VERSION "GM Global B Super Cruise 1 CAN8"
NS_ :

    CM_ BO_ 648 "Full freshness counter companion for 0x0C1. The next observed protected frame carries (counter + 1) modulo 32. Counter pairing verified; authentication key and data ID remain unresolved.";
CM_ BO_ 650 "Full freshness counter companion for 0x0C6. The next observed protected frame carries (counter + 1) modulo 32. Counter pairing verified; authentication key and data ID remain unresolved.";
CM_ BO_ 654 "Full freshness counter companion for 0x0D1. The next observed protected frame carries (counter + 1) modulo 32. Counter pairing verified; authentication key and data ID remain unresolved.";
CM_ BO_ 656 "Full freshness counter companion for 0x0D4. The next observed protected frame carries (counter + 1) modulo 32. Counter pairing verified; authentication key and data ID remain unresolved.";
CM_ BO_ 655 "Full freshness counter companion for 0x0FE. The next observed protected frame carries (counter + 1) modulo 32. Counter pairing verified; authentication key and data ID remain unresolved.";
CM_ BO_ 1326 "Full freshness counter companion for 0x252. The next observed protected frame carries (counter + 1) modulo 32. Counter pairing verified; authentication key and data ID remain unresolved.";

BA_DEF_
    BA_
    BA_DEF_DEF_
BS_:
BU_: ACP3_MCU CGM FCM PARK_ASSIST LRR LFR RFR LCRR LRR_SIDE RRR_SIDE Vector__XXX

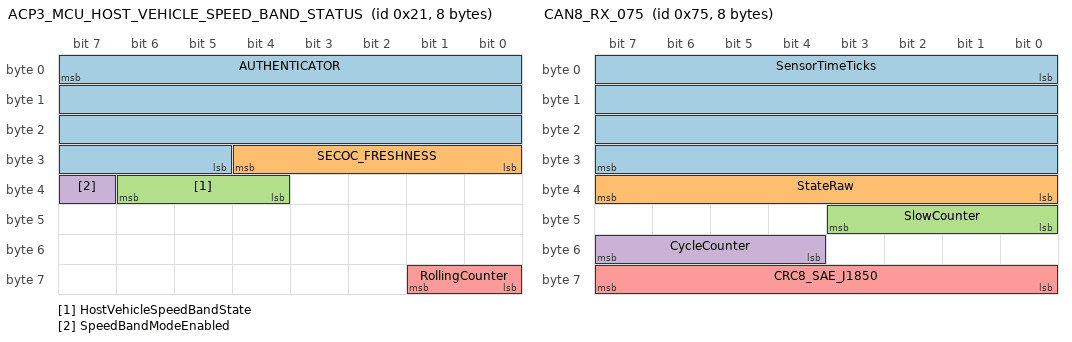
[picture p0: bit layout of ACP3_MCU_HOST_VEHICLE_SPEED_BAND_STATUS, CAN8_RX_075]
BO_ 33 ACP3_MCU_HOST_VEHICLE_SPEED_BAND_STATUS: 8 ACP3_MCU
 SG_ AUTHENTICATOR : 7|27@0+ (1,0) [0|134217727] "" Vector__XXX
 SG_ SECOC_FRESHNESS : 28|5@0+ (1,0) [0|31] "" Vector__XXX
 SG_ HostVehicleSpeedBandState : 36|3@1+ (1,0) [0|7] "" Vector__XXX
 SG_ SpeedBandModeEnabled : 39|1@1+ (1,0) [0|1] "" Vector__XXX
 SG_ RollingCounter : 56|2@1+ (1,0) [0|3] "" Vector__XXX

BO_ 117 CAN8_RX_075: 8 Vector__XXX
 SG_ SensorTimeTicks : 0|32@1+ (1,0) [0|4294967295] "tick" ACP3_MCU
 SG_ StateRaw : 32|8@1+ (1,0) [0|255] "" ACP3_MCU
 SG_ SlowCounter : 40|4@1+ (1,0) [0|15] "" ACP3_MCU
 SG_ CycleCounter : 52|4@1+ (1,0) [0|15] "" ACP3_MCU
 SG_ CRC8_SAE_J1850 : 56|8@1+ (1,0) [0|255] "" ACP3_MCU

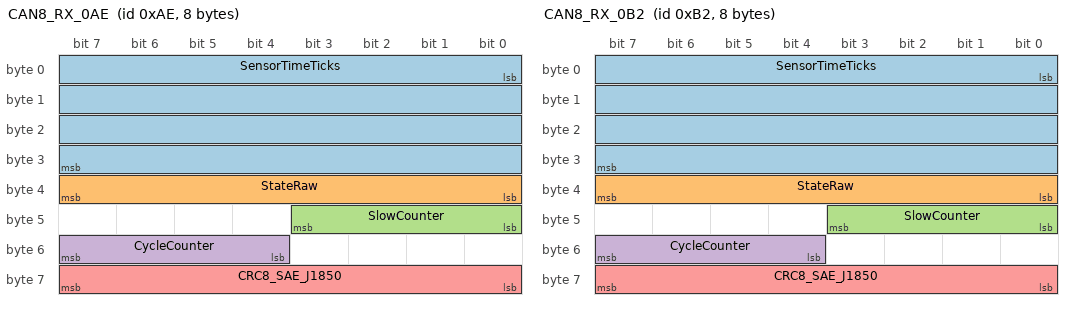
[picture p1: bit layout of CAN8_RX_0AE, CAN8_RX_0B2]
BO_ 174 CAN8_RX_0AE: 8 Vector__XXX
 SG_ SensorTimeTicks : 0|32@1+ (1,0) [0|4294967295] "tick" ACP3_MCU
 SG_ StateRaw : 32|8@1+ (1,0) [0|255] "" ACP3_MCU
 SG_ SlowCounter : 40|4@1+ (1,0) [0|15] "" ACP3_MCU
 SG_ CycleCounter : 52|4@1+ (1,0) [0|15] "" ACP3_MCU
 SG_ CRC8_SAE_J1850 : 56|8@1+ (1,0) [0|255] "" ACP3_MCU

BO_ 178 CAN8_RX_0B2: 8 Vector__XXX
 SG_ SensorTimeTicks : 0|32@1+ (1,0) [0|4294967295] "tick" ACP3_MCU
 SG_ StateRaw : 32|8@1+ (1,0) [0|255] "" ACP3_MCU
 SG_ SlowCounter : 40|4@1+ (1,0) [0|15] "" ACP3_MCU
 SG_ CycleCounter : 52|4@1+ (1,0) [0|15] "" ACP3_MCU
 SG_ CRC8_SAE_J1850 : 56|8@1+ (1,0) [0|255] "" ACP3_MCU

BO_ 180 PARK_ASSIST_ULTRASONIC_BANK_A_0B4: 48 PARK_ASSIST
 SG_ AUTHENTICATOR : 7|32@0+ (1,0) [0|4294967295] "" ACP3_MCU
 SG_ SECOC_FRESHNESS : 39|5@0+ (1,0) [0|31] "" ACP3_MCU
 SG_ SECOC_AUX : 34|3@0+ (1,0) [0|7] "" ACP3_MCU
 SG_ ApplicationHeaderRaw : 40|8@1+ (1,0) [0|255] "" ACP3_MCU
 SG_ UltrasonicRecord1Raw : 48|48@1+ (1,0) [0|281474976710655] "" ACP3_MCU
 SG_ UltrasonicRecord2Raw : 96|48@1+ (1,0) [0|281474976710655] "" ACP3_MCU
 SG_ UltrasonicRecord3Raw : 144|48@1+ (1,0) [0|281474976710655] "" ACP3_MCU
 SG_ UltrasonicRecord4Raw : 192|48@1+ (1,0) [0|281474976710655] "" ACP3_MCU
 SG_ UltrasonicRecord5Raw : 240|48@1+ (1,0) [0|281474976710655] "" ACP3_MCU
 SG_ UltrasonicRecord6Raw : 288|48@1+ (1,0) [0|281474976710655] "" ACP3_MCU
 SG_ ApplicationTailRaw : 336|16@1+ (1,0) [0|65535] "" ACP3_MCU
 SG_ ReservedTail : 352|32@1+ (1,0) [0|4294967295] "" ACP3_MCU

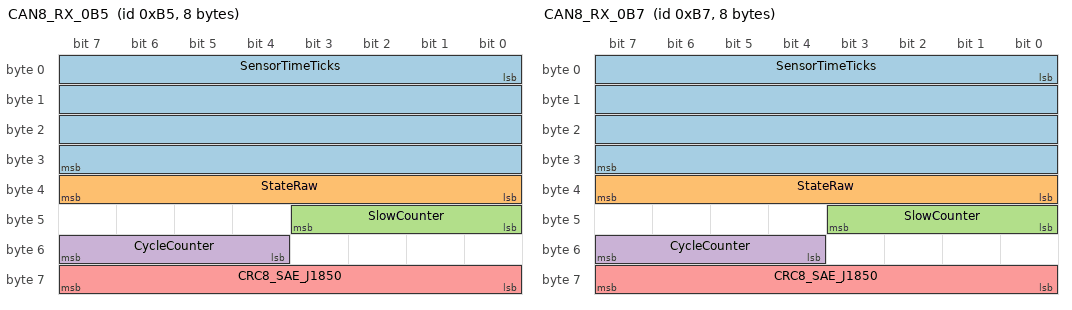
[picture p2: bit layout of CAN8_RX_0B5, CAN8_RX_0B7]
BO_ 181 CAN8_RX_0B5: 8 Vector__XXX
 SG_ SensorTimeTicks : 0|32@1+ (1,0) [0|4294967295] "tick" ACP3_MCU
 SG_ StateRaw : 32|8@1+ (1,0) [0|255] "" ACP3_MCU
 SG_ SlowCounter : 40|4@1+ (1,0) [0|15] "" ACP3_MCU
 SG_ CycleCounter : 52|4@1+ (1,0) [0|15] "" ACP3_MCU
 SG_ CRC8_SAE_J1850 : 56|8@1+ (1,0) [0|255] "" ACP3_MCU

BO_ 183 CAN8_RX_0B7: 8 Vector__XXX
 SG_ SensorTimeTicks : 0|32@1+ (1,0) [0|4294967295] "tick" ACP3_MCU
 SG_ StateRaw : 32|8@1+ (1,0) [0|255] "" ACP3_MCU
 SG_ SlowCounter : 40|4@1+ (1,0) [0|15] "" ACP3_MCU
 SG_ CycleCounter : 52|4@1+ (1,0) [0|15] "" ACP3_MCU
 SG_ CRC8_SAE_J1850 : 56|8@1+ (1,0) [0|255] "" ACP3_MCU

BO_ 190 RRR_SIDE_OBJECT_PAGE0_0BE: 64 RRR_SIDE
 SG_ CycleCounter : 6|2@1+ (1,0) [0|3] "" ACP3_MCU
 SG_ Object0LongitudinalEstimate : 318|11@0- (0.125,0) [-128|127.875] "m" ACP3_MCU
 SG_ Object0LateralEstimate : 323|10@0- (0.125,0) [-64|63.875] "m" ACP3_MCU
 SG_ Object1LongitudinalEstimate : 329|11@0- (0.125,0) [-128|127.875] "m" ACP3_MCU
 SG_ Object1LateralEstimate : 350|10@0- (0.125,0) [-64|63.875] "m" ACP3_MCU
 SG_ Object2LongitudinalEstimate : 356|11@0- (0.125,0) [-128|127.875] "m" ACP3_MCU
 SG_ Object2LateralEstimate : 361|10@0- (0.125,0) [-64|63.875] "m" ACP3_MCU
 SG_ Object3LongitudinalEstimate : 383|11@0- (0.125,0) [-128|127.875] "m" ACP3_MCU
 SG_ Object3LateralEstimate : 388|10@0- (0.125,0) [-64|63.875] "m" ACP3_MCU
 SG_ Object4LongitudinalEstimate : 394|11@0- (0.125,0) [-128|127.875] "m" ACP3_MCU
 SG_ Object4LateralEstimate : 415|10@0- (0.125,0) [-64|63.875] "m" ACP3_MCU
 SG_ Object5LongitudinalEstimate : 421|11@0- (0.125,0) [-128|127.875] "m" ACP3_MCU
 SG_ Object5LateralEstimate : 426|10@0- (0.125,0) [-64|63.875] "m" ACP3_MCU
 SG_ Object6LongitudinalEstimate : 432|11@0- (0.125,0) [-128|127.875] "m" ACP3_MCU
 SG_ Object6LateralEstimate : 453|10@0- (0.125,0) [-64|63.875] "m" ACP3_MCU
 SG_ Object7LongitudinalEstimate : 459|11@0- (0.125,0) [-128|127.875] "m" ACP3_MCU
 SG_ Object7LateralEstimate : 464|10@0- (0.125,0) [-64|63.875] "m" ACP3_MCU
 SG_ Object8LongitudinalEstimate : 486|11@0- (0.125,0) [-128|127.875] "m" ACP3_MCU
 SG_ Object8LateralEstimate : 491|10@0- (0.125,0) [-64|63.875] "m" ACP3_MCU

BO_ 191 RRR_SIDE_OBJECT_PAGE1_0BF: 64 RRR_SIDE
 SG_ CycleCounter : 6|2@1+ (1,0) [0|3] "" ACP3_MCU

BO_ 193 RRR_SIDE_SECURITY_AUX0_0C1: 48 RRR_SIDE
 SG_ SECOC_FRESHNESS : 39|5@0+ (1,0) [0|31] "" ACP3_MCU
 SG_ ApplicationCounter : 376|2@1+ (1,0) [0|3] "" ACP3_MCU
 SG_ Object0LongitudinalRaw : 278|11@0- (1,0) [-1024|1023] "" ACP3_MCU
 SG_ Object0TrackId : 240|6@0+ (1,0) [0|63] "" ACP3_MCU
 SG_ Object0RelativeLongitudinalVelocityRaw : 307|11@0- (1,0) [-1024|1023] "" ACP3_MCU
 SG_ Object0RelativeLateralVelocityCandidateRaw : 248|9@0- (1,0) [-256|255] "" ACP3_MCU

BO_ 197 LRR_SIDE_OBJECT_PAGE0_0C5: 64 LRR_SIDE
 SG_ CycleCounter : 6|2@1+ (1,0) [0|3] "" ACP3_MCU
 SG_ Object1TrackId : 102|6@0+ (1,0) [0|63] "" ACP3_MCU
 SG_ Object2TrackId : 226|6@0+ (1,0) [0|63] "" ACP3_MCU
 SG_ Object3TrackId : 374|6@0+ (1,0) [0|63] "" ACP3_MCU
 SG_ Object1RelativeLongitudinalVelocityRaw : 145|11@0- (1,0) [-1024|1023] "" ACP3_MCU
 SG_ Object1RelativeLateralVelocityCandidateRaw : 110|9@0- (1,0) [-256|255] "" ACP3_MCU
 SG_ Object2RelativeLongitudinalVelocityRaw : 293|11@0- (1,0) [-1024|1023] "" ACP3_MCU
 SG_ Object2RelativeLateralVelocityCandidateRaw : 234|9@0- (1,0) [-256|255] "" ACP3_MCU
 SG_ Object3RelativeLongitudinalVelocityRaw : 425|11@0- (1,0) [-1024|1023] "" ACP3_MCU
 SG_ Object3RelativeLateralVelocityCandidateRaw : 382|9@0- (1,0) [-256|255] "" ACP3_MCU

BO_ 198 LRR_SIDE_SECURITY_AUX0_0C6: 48 LRR_SIDE
 SG_ SECOC_FRESHNESS : 39|5@0+ (1,0) [0|31] "" ACP3_MCU
 SG_ ApplicationCounter : 376|2@1+ (1,0) [0|3] "" ACP3_MCU
 SG_ Object0LongitudinalRaw : 278|11@0- (1,0) [-1024|1023] "" ACP3_MCU
 SG_ Object0TrackId : 240|6@0+ (1,0) [0|63] "" ACP3_MCU
 SG_ Object0RelativeLongitudinalVelocityRaw : 307|11@0- (1,0) [-1024|1023] "" ACP3_MCU
 SG_ Object0RelativeLateralVelocityCandidateRaw : 248|9@0- (1,0) [-256|255] "" ACP3_MCU

BO_ 199 LCRR_OBJECT_PAGE0_0C7: 64 LCRR
 SG_ CycleCounter : 6|2@1+ (1,0) [0|3] "" ACP3_MCU
 SG_ Object0LongitudinalEstimate : 318|11@0- (0.125,0) [-128|127.875] "m" ACP3_MCU
 SG_ Object0LateralEstimate : 323|10@0- (0.125,0) [-64|63.875] "m" ACP3_MCU
 SG_ Object1LongitudinalEstimate : 329|11@0- (0.125,0) [-128|127.875] "m" ACP3_MCU
 SG_ Object1LateralEstimate : 350|10@0- (0.125,0) [-64|63.875] "m" ACP3_MCU
 SG_ Object2LongitudinalEstimate : 356|11@0- (0.125,0) [-128|127.875] "m" ACP3_MCU
 SG_ Object2LateralEstimate : 361|10@0- (0.125,0) [-64|63.875] "m" ACP3_MCU
 SG_ Object3LongitudinalEstimate : 383|11@0- (0.125,0) [-128|127.875] "m" ACP3_MCU
 SG_ Object3LateralEstimate : 388|10@0- (0.125,0) [-64|63.875] "m" ACP3_MCU
 SG_ Object4LongitudinalEstimate : 394|11@0- (0.125,0) [-128|127.875] "m" ACP3_MCU
 SG_ Object4LateralEstimate : 415|10@0- (0.125,0) [-64|63.875] "m" ACP3_MCU
 SG_ Object5LongitudinalEstimate : 421|11@0- (0.125,0) [-128|127.875] "m" ACP3_MCU
 SG_ Object5LateralEstimate : 426|10@0- (0.125,0) [-64|63.875] "m" ACP3_MCU
 SG_ Object6LongitudinalEstimate : 432|11@0- (0.125,0) [-128|127.875] "m" ACP3_MCU
 SG_ Object6LateralEstimate : 453|10@0- (0.125,0) [-64|63.875] "m" ACP3_MCU
 SG_ Object7LongitudinalEstimate : 459|11@0- (0.125,0) [-128|127.875] "m" ACP3_MCU
 SG_ Object7LateralEstimate : 464|10@0- (0.125,0) [-64|63.875] "m" ACP3_MCU
 SG_ Object8LongitudinalEstimate : 486|11@0- (0.125,0) [-128|127.875] "m" ACP3_MCU
 SG_ Object8LateralEstimate : 491|10@0- (0.125,0) [-64|63.875] "m" ACP3_MCU

BO_ 200 LCRR_OBJECT_PAGE1_0C8: 64 LCRR
 SG_ CycleCounter : 6|2@1+ (1,0) [0|3] "" ACP3_MCU

BO_ 201 LCRR_OBJECT_PAGE2_0C9: 64 LCRR
 SG_ CycleCounter : 6|2@1+ (1,0) [0|3] "" ACP3_MCU
 SG_ Object1TrackId : 102|6@0+ (1,0) [0|63] "" ACP3_MCU
 SG_ Object2TrackId : 226|6@0+ (1,0) [0|63] "" ACP3_MCU
 SG_ Object3TrackId : 374|6@0+ (1,0) [0|63] "" ACP3_MCU
 SG_ Object1RelativeLongitudinalVelocityRaw : 145|11@0- (1,0) [-1024|1023] "" ACP3_MCU
 SG_ Object1RelativeLateralVelocityCandidateRaw : 110|9@0- (1,0) [-256|255] "" ACP3_MCU
 SG_ Object2RelativeLongitudinalVelocityRaw : 293|11@0- (1,0) [-1024|1023] "" ACP3_MCU
 SG_ Object2RelativeLateralVelocityCandidateRaw : 234|9@0- (1,0) [-256|255] "" ACP3_MCU
 SG_ Object3RelativeLongitudinalVelocityRaw : 425|11@0- (1,0) [-1024|1023] "" ACP3_MCU
 SG_ Object3RelativeLateralVelocityCandidateRaw : 382|9@0- (1,0) [-256|255] "" ACP3_MCU

BO_ 207 RFR_OBJECT_PAGE0_0CF: 64 RFR
 SG_ CycleCounter : 6|2@1+ (1,0) [0|3] "" ACP3_MCU
 SG_ Object0LongitudinalEstimate : 318|11@0- (0.125,0) [-128|127.875] "m" ACP3_MCU
 SG_ Object0LateralEstimate : 323|10@0- (0.125,0) [-64|63.875] "m" ACP3_MCU
 SG_ Object1LongitudinalEstimate : 329|11@0- (0.125,0) [-128|127.875] "m" ACP3_MCU
 SG_ Object1LateralEstimate : 350|10@0- (0.125,0) [-64|63.875] "m" ACP3_MCU
 SG_ Object2LongitudinalEstimate : 356|11@0- (0.125,0) [-128|127.875] "m" ACP3_MCU
 SG_ Object2LateralEstimate : 361|10@0- (0.125,0) [-64|63.875] "m" ACP3_MCU
 SG_ Object3LongitudinalEstimate : 383|11@0- (0.125,0) [-128|127.875] "m" ACP3_MCU
 SG_ Object3LateralEstimate : 388|10@0- (0.125,0) [-64|63.875] "m" ACP3_MCU
 SG_ Object4LongitudinalEstimate : 394|11@0- (0.125,0) [-128|127.875] "m" ACP3_MCU
 SG_ Object4LateralEstimate : 415|10@0- (0.125,0) [-64|63.875] "m" ACP3_MCU
 SG_ Object5LongitudinalEstimate : 421|11@0- (0.125,0) [-128|127.875] "m" ACP3_MCU
 SG_ Object5LateralEstimate : 426|10@0- (0.125,0) [-64|63.875] "m" ACP3_MCU
 SG_ Object6LongitudinalEstimate : 432|11@0- (0.125,0) [-128|127.875] "m" ACP3_MCU
 SG_ Object6LateralEstimate : 453|10@0- (0.125,0) [-64|63.875] "m" ACP3_MCU
 SG_ Object7LongitudinalEstimate : 459|11@0- (0.125,0) [-128|127.875] "m" ACP3_MCU
 SG_ Object7LateralEstimate : 464|10@0- (0.125,0) [-64|63.875] "m" ACP3_MCU
 SG_ Object8LongitudinalEstimate : 486|11@0- (0.125,0) [-128|127.875] "m" ACP3_MCU
 SG_ Object8LateralEstimate : 491|10@0- (0.125,0) [-64|63.875] "m" ACP3_MCU

BO_ 208 RFR_OBJECT_PAGE1_0D0: 64 RFR
 SG_ CycleCounter : 6|2@1+ (1,0) [0|3] "" ACP3_MCU

BO_ 209 RFR_SECURITY_AUX0_0D1: 48 RFR
 SG_ SECOC_FRESHNESS : 39|5@0+ (1,0) [0|31] "" ACP3_MCU
 SG_ ApplicationCounter : 376|2@1+ (1,0) [0|3] "" ACP3_MCU
 SG_ Object0LongitudinalRaw : 278|11@0- (1,0) [-1024|1023] "" ACP3_MCU
 SG_ Object0TrackId : 240|6@0+ (1,0) [0|63] "" ACP3_MCU
 SG_ Object0RelativeLongitudinalVelocityRaw : 307|11@0- (1,0) [-1024|1023] "" ACP3_MCU
 SG_ Object0RelativeLateralVelocityCandidateRaw : 248|9@0- (1,0) [-256|255] "" ACP3_MCU

BO_ 210 LFR_OBJECT_PAGE2_0D2: 64 LFR
 SG_ CycleCounter : 6|2@1+ (1,0) [0|3] "" ACP3_MCU
 SG_ Object0LongitudinalEstimate : 318|11@0- (0.125,0) [-128|127.875] "m" ACP3_MCU
 SG_ Object0LateralEstimate : 323|10@0- (0.125,0) [-64|63.875] "m" ACP3_MCU
 SG_ Object1LongitudinalEstimate : 329|11@0- (0.125,0) [-128|127.875] "m" ACP3_MCU
 SG_ Object1LateralEstimate : 350|10@0- (0.125,0) [-64|63.875] "m" ACP3_MCU
 SG_ Object2LongitudinalEstimate : 356|11@0- (0.125,0) [-128|127.875] "m" ACP3_MCU
 SG_ Object2LateralEstimate : 361|10@0- (0.125,0) [-64|63.875] "m" ACP3_MCU
 SG_ Object3LongitudinalEstimate : 383|11@0- (0.125,0) [-128|127.875] "m" ACP3_MCU
 SG_ Object3LateralEstimate : 388|10@0- (0.125,0) [-64|63.875] "m" ACP3_MCU
 SG_ Object4LongitudinalEstimate : 394|11@0- (0.125,0) [-128|127.875] "m" ACP3_MCU
 SG_ Object4LateralEstimate : 415|10@0- (0.125,0) [-64|63.875] "m" ACP3_MCU
 SG_ Object5LongitudinalEstimate : 421|11@0- (0.125,0) [-128|127.875] "m" ACP3_MCU
 SG_ Object5LateralEstimate : 426|10@0- (0.125,0) [-64|63.875] "m" ACP3_MCU
 SG_ Object6LongitudinalEstimate : 432|11@0- (0.125,0) [-128|127.875] "m" ACP3_MCU
 SG_ Object6LateralEstimate : 453|10@0- (0.125,0) [-64|63.875] "m" ACP3_MCU
 SG_ Object7LongitudinalEstimate : 459|11@0- (0.125,0) [-128|127.875] "m" ACP3_MCU
 SG_ Object7LateralEstimate : 464|10@0- (0.125,0) [-64|63.875] "m" ACP3_MCU
 SG_ Object8LongitudinalEstimate : 486|11@0- (0.125,0) [-128|127.875] "m" ACP3_MCU
 SG_ Object8LateralEstimate : 491|10@0- (0.125,0) [-64|63.875] "m" ACP3_MCU

BO_ 211 LFR_OBJECT_PAGE3_0D3: 64 LFR
 SG_ CycleCounter : 6|2@1+ (1,0) [0|3] "" ACP3_MCU

BO_ 212 LFR_SECURITY_AUX1_0D4: 48 LFR
 SG_ SECOC_FRESHNESS : 39|5@0+ (1,0) [0|31] "" ACP3_MCU
 SG_ ApplicationCounter : 376|2@1+ (1,0) [0|3] "" ACP3_MCU
 SG_ Object0LongitudinalRaw : 278|11@0- (1,0) [-1024|1023] "" ACP3_MCU
 SG_ Object0TrackId : 240|6@0+ (1,0) [0|63] "" ACP3_MCU
 SG_ Object0RelativeLongitudinalVelocityRaw : 307|11@0- (1,0) [-1024|1023] "" ACP3_MCU
 SG_ Object0RelativeLateralVelocityCandidateRaw : 248|9@0- (1,0) [-256|255] "" ACP3_MCU

BO_ 216 CAMERA_0D8: 48 FCM
 SG_ RawField01 : 4|2@1+ (1,0) [0|0] "" ACP3_MCU
 SG_ RawField02_RollingCounter : 6|2@1+ (1,0) [0|0] "" ACP3_MCU
 SG_ RawField03 : 3|5@0+ (1,0) [0|0] "" ACP3_MCU
 SG_ RawField04 : 14|9@0- (1,0) [0|0] "" ACP3_MCU
 SG_ RawField05 : 18|2@1+ (1,0) [0|0] "" ACP3_MCU
 SG_ RawField06 : 20|2@1+ (1,0) [0|0] "" ACP3_MCU
 SG_ RawField07 : 17|5@0+ (1,0) [0|0] "" ACP3_MCU
 SG_ RawField08 : 28|9@0- (1,0) [0|0] "" ACP3_MCU
 SG_ RawField09 : 32|2@1+ (1,0) [0|0] "" ACP3_MCU
 SG_ RawField10 : 34|2@1+ (1,0) [0|0] "" ACP3_MCU
 SG_ RawField11 : 42|9@0- (1,0) [0|0] "" ACP3_MCU
 SG_ RawField12 : 43|5@1+ (1,0) [0|0] "" ACP3_MCU
 SG_ RawField13 : 48|2@1+ (1,0) [0|0] "" ACP3_MCU
 SG_ RawField14 : 56|9@0- (1,0) [0|0] "" ACP3_MCU
 SG_ RawField15 : 57|5@1+ (1,0) [0|0] "" ACP3_MCU
 SG_ RawField16 : 62|2@1+ (1,0) [0|0] "" ACP3_MCU
 SG_ RawField17 : 76|2@1+ (1,0) [0|0] "" ACP3_MCU
 SG_ RawField18 : 78|2@1+ (1,0) [0|0] "" ACP3_MCU
 SG_ RawField19 : 75|5@0+ (1,0) [0|0] "" ACP3_MCU
 SG_ RawField20 : 86|9@0- (1,0) [0|0] "" ACP3_MCU
 SG_ RawField21 : 90|2@1+ (1,0) [0|0] "" ACP3_MCU
 SG_ RawField22 : 92|2@1+ (1,0) [0|0] "" ACP3_MCU
 SG_ RawField23 : 89|5@0+ (1,0) [0|0] "" ACP3_MCU
 SG_ RawField24 : 100|9@0- (1,0) [0|0] "" ACP3_MCU
 SG_ RawField25 : 104|2@1+ (1,0) [0|0] "" ACP3_MCU
 SG_ RawField26 : 106|2@1+ (1,0) [0|0] "" ACP3_MCU
 SG_ RawField27 : 114|9@0- (1,0) [0|0] "" ACP3_MCU
 SG_ RawField28 : 115|5@1+ (1,0) [0|0] "" ACP3_MCU
 SG_ RawField29 : 120|2@1+ (1,0) [0|0] "" ACP3_MCU
 SG_ RawField30 : 128|9@0- (1,0) [0|0] "" ACP3_MCU
 SG_ RawField31 : 129|5@1+ (1,0) [0|0] "" ACP3_MCU
 SG_ RawField32 : 134|2@1+ (1,0) [0|0] "" ACP3_MCU
 SG_ RawField33 : 148|2@1+ (1,0) [0|0] "" ACP3_MCU
 SG_ RawField34 : 150|2@1+ (1,0) [0|0] "" ACP3_MCU
 SG_ RawField35 : 147|5@0+ (1,0) [0|0] "" ACP3_MCU
 SG_ RawField36 : 158|9@0- (1,0) [0|0] "" ACP3_MCU
 SG_ RawField37 : 162|2@1+ (1,0) [0|0] "" ACP3_MCU
 SG_ RawField38 : 164|2@1+ (1,0) [0|0] "" ACP3_MCU
 SG_ RawField39 : 161|5@0+ (1,0) [0|0] "" ACP3_MCU
 SG_ RawField40 : 172|9@0- (1,0) [0|0] "" ACP3_MCU
 SG_ RawField41 : 176|2@1+ (1,0) [0|0] "" ACP3_MCU
 SG_ RawField42 : 178|2@1+ (1,0) [0|0] "" ACP3_MCU
 SG_ RawField43 : 186|9@0- (1,0) [0|0] "" ACP3_MCU
 SG_ RawField44 : 187|5@1+ (1,0) [0|0] "" ACP3_MCU
 SG_ RawField45 : 192|2@1+ (1,0) [0|0] "" ACP3_MCU
 SG_ RawField46 : 200|9@0- (1,0) [0|0] "" ACP3_MCU
 SG_ RawField47 : 201|5@1+ (1,0) [0|0] "" ACP3_MCU
 SG_ RawField48 : 206|2@1+ (1,0) [0|0] "" ACP3_MCU
 SG_ RawField49 : 220|2@1+ (1,0) [0|0] "" ACP3_MCU
 SG_ RawField50 : 222|2@1+ (1,0) [0|0] "" ACP3_MCU
 SG_ RawField51 : 219|5@0+ (1,0) [0|0] "" ACP3_MCU
 SG_ RawField52 : 230|9@0- (1,0) [0|0] "" ACP3_MCU
 SG_ RawField53 : 234|2@1+ (1,0) [0|0] "" ACP3_MCU
 SG_ RawField54 : 236|2@1+ (1,0) [0|0] "" ACP3_MCU
 SG_ RawField55 : 233|5@0+ (1,0) [0|0] "" ACP3_MCU
 SG_ RawField56 : 244|9@0- (1,0) [0|0] "" ACP3_MCU
 SG_ RawField57 : 248|2@1+ (1,0) [0|0] "" ACP3_MCU
 SG_ RawField58 : 250|2@1+ (1,0) [0|0] "" ACP3_MCU
 SG_ RawField59 : 258|9@0- (1,0) [0|0] "" ACP3_MCU
 SG_ RawField60 : 259|5@1+ (1,0) [0|0] "" ACP3_MCU
 SG_ RawField61 : 264|2@1+ (1,0) [0|0] "" ACP3_MCU
 SG_ RawField62 : 272|6@1+ (1,0) [0|0] "" ACP3_MCU
 SG_ RawField63 : 278|2@1+ (1,0) [0|0] "" ACP3_MCU
 SG_ RawField64 : 287|9@0- (1,0) [0|0] "" ACP3_MCU
 SG_ RawField65 : 294|11@0- (1,0) [0|0] "" ACP3_MCU
 SG_ RawField66 : 298|2@1+ (1,0) [0|0] "" ACP3_MCU
 SG_ RawField67 : 297|6@0+ (1,0) [0|0] "" ACP3_MCU
 SG_ RawField68 : 307|7@0+ (1,0) [0|0] "" ACP3_MCU
 SG_ RawField69 : 315|2@1+ (1,0) [0|0] "" ACP3_MCU
 SG_ RawField70 : 314|8@0+ (1,0) [0|0] "" ACP3_MCU
 SG_ RawField71 : 321|2@1+ (1,0) [0|0] "" ACP3_MCU
 SG_ RawField72 : 320|6@0+ (1,0) [0|0] "" ACP3_MCU
 SG_ RawField73 : 330|9@0- (1,0) [0|0] "" ACP3_MCU
 SG_ RawField74 : 337|11@0- (1,0) [0|0] "" ACP3_MCU
 SG_ RawField75 : 357|2@1+ (1,0) [0|0] "" ACP3_MCU
 SG_ RawField76 : 356|6@0+ (1,0) [0|0] "" ACP3_MCU
 SG_ RawField77 : 360|7@1+ (1,0) [0|0] "" ACP3_MCU
 SG_ RawField78 : 374|2@1+ (1,0) [0|0] "" ACP3_MCU
 SG_ RawField79 : 373|8@0+ (1,0) [0|0] "" ACP3_MCU
 SG_ RawField80 : 376|6@1+ (1,0) [0|0] "" ACP3_MCU

BO_ 217 CAMERA_0D9: 64 FCM
 SG_ RawField01_RollingCounter : 6|2@1+ (1,0) [0|0] "" ACP3_MCU
 SG_ RawField02 : 5|8@0+ (1,0) [0|0] "" ACP3_MCU
 SG_ RawField03 : 8|1@1+ (1,0) [0|0] "" ACP3_MCU
 SG_ RawField04 : 9|2@1+ (1,0) [0|0] "" ACP3_MCU
 SG_ RawField05 : 11|1@1+ (1,0) [0|0] "" ACP3_MCU
 SG_ RawField06 : 12|2@1+ (1,0) [0|0] "" ACP3_MCU
 SG_ RawField07 : 23|1@1+ (1,0) [0|0] "" ACP3_MCU
 SG_ RawField08 : 22|8@0+ (1,0) [0|0] "" ACP3_MCU
 SG_ RawField09 : 24|1@1+ (1,0) [0|0] "" ACP3_MCU
 SG_ RawField10 : 25|1@1+ (1,0) [0|0] "" ACP3_MCU
 SG_ RawField11 : 26|2@1+ (1,0) [0|0] "" ACP3_MCU
 SG_ RawField12 : 28|1@1+ (1,0) [0|0] "" ACP3_MCU
 SG_ RawField13 : 29|2@1+ (1,0) [0|0] "" ACP3_MCU
 SG_ RawField14 : 32|8@1+ (1,0) [0|0] "" ACP3_MCU
 SG_ RawField15 : 41|1@1+ (1,0) [0|0] "" ACP3_MCU
 SG_ RawField16 : 40|8@0+ (1,0) [0|0] "" ACP3_MCU
 SG_ RawField17 : 42|1@1+ (1,0) [0|0] "" ACP3_MCU
 SG_ RawField18 : 43|2@1+ (1,0) [0|0] "" ACP3_MCU
 SG_ RawField19 : 45|1@1+ (1,0) [0|0] "" ACP3_MCU
 SG_ RawField20 : 46|2@1+ (1,0) [0|0] "" ACP3_MCU
 SG_ RawField21 : 48|2@0+ (1,0) [0|0] "" ACP3_MCU
 SG_ RawField22 : 58|1@1+ (1,0) [0|0] "" ACP3_MCU
 SG_ RawField23 : 57|8@0+ (1,0) [0|0] "" ACP3_MCU
 SG_ RawField24 : 59|1@1+ (1,0) [0|0] "" ACP3_MCU
 SG_ RawField25 : 60|2@1+ (1,0) [0|0] "" ACP3_MCU
 SG_ RawField26 : 62|1@1+ (1,0) [0|0] "" ACP3_MCU
 SG_ RawField27 : 64|2@1+ (1,0) [0|0] "" ACP3_MCU
 SG_ RawField28 : 75|1@1+ (1,0) [0|0] "" ACP3_MCU
 SG_ RawField29 : 74|8@0+ (1,0) [0|0] "" ACP3_MCU
 SG_ RawField30 : 76|1@1+ (1,0) [0|0] "" ACP3_MCU
 SG_ RawField31 : 77|2@1+ (1,0) [0|0] "" ACP3_MCU
 SG_ RawField32 : 79|1@1+ (1,0) [0|0] "" ACP3_MCU
 SG_ RawField33 : 80|1@1+ (1,0) [0|0] "" ACP3_MCU
 SG_ RawField34 : 81|2@1+ (1,0) [0|0] "" ACP3_MCU
 SG_ RawField35 : 90|2@1+ (1,0) [0|0] "" ACP3_MCU
 SG_ RawField36 : 89|16@0- (1,0) [0|0] "" ACP3_MCU
 SG_ RawField37 : 92|1@1+ (1,0) [0|0] "" ACP3_MCU
 SG_ RawField38 : 93|1@1+ (1,0) [0|0] "" ACP3_MCU
 SG_ RawField39 : 94|2@1+ (1,0) [0|0] "" ACP3_MCU
 SG_ RawField40 : 105|16@0- (1,0) [0|0] "" ACP3_MCU
 SG_ RawField41 : 121|10@0- (1,0) [0|0] "" ACP3_MCU
 SG_ RawField42 : 136|8@1+ (1,0) [0|0] "" ACP3_MCU
 SG_ RawField43 : 151|10@0+ (1,0) [0|0] "" ACP3_MCU
 SG_ RawField44 : 157|8@0+ (1,0) [0|0] "" ACP3_MCU
 SG_ RawField45 : 165|8@0+ (1,0) [0|0] "" ACP3_MCU
 SG_ RawField46 : 172|2@1+ (1,0) [0|0] "" ACP3_MCU
 SG_ RawField47 : 171|16@0- (1,0) [0|0] "" ACP3_MCU
 SG_ RawField48 : 187|16@0- (1,0) [0|0] "" ACP3_MCU
 SG_ RawField49 : 203|10@0- (1,0) [0|0] "" ACP3_MCU
 SG_ RawField50 : 209|8@0+ (1,0) [0|0] "" ACP3_MCU
 SG_ RawField51 : 217|10@0+ (1,0) [0|0] "" ACP3_MCU
 SG_ RawField52 : 232|8@1+ (1,0) [0|0] "" ACP3_MCU
 SG_ RawField53 : 240|8@1+ (1,0) [0|0] "" ACP3_MCU
 SG_ RawField54 : 254|2@1+ (1,0) [0|0] "" ACP3_MCU
 SG_ RawField55 : 253|16@0- (1,0) [0|0] "" ACP3_MCU
 SG_ RawField56 : 269|16@0- (1,0) [0|0] "" ACP3_MCU
 SG_ RawField57 : 285|10@0- (1,0) [0|0] "" ACP3_MCU
 SG_ RawField58 : 291|8@0+ (1,0) [0|0] "" ACP3_MCU
 SG_ RawField59 : 299|10@0+ (1,0) [0|0] "" ACP3_MCU
 SG_ RawField60 : 305|8@0+ (1,0) [0|0] "" ACP3_MCU
 SG_ RawField61 : 313|8@0+ (1,0) [0|0] "" ACP3_MCU
 SG_ RawField62 : 321|10@0- (1,0) [0|0] "" ACP3_MCU
 SG_ RawField63 : 343|10@0- (1,0) [0|0] "" ACP3_MCU
 SG_ RawField64 : 349|10@0- (1,0) [0|0] "" ACP3_MCU
 SG_ RawField65 : 355|10@0- (1,0) [0|0] "" ACP3_MCU
 SG_ RawField66 : 361|10@0- (1,0) [0|0] "" ACP3_MCU
 SG_ RawField67 : 383|10@0- (1,0) [0|0] "" ACP3_MCU
 SG_ RawField68 : 389|10@0- (1,0) [0|0] "" ACP3_MCU
 SG_ RawField69 : 395|10@0- (1,0) [0|0] "" ACP3_MCU
 SG_ RawField70 : 401|10@0- (1,0) [0|0] "" ACP3_MCU
 SG_ RawField71 : 423|10@0- (1,0) [0|0] "" ACP3_MCU
 SG_ RawField72 : 429|10@0- (1,0) [0|0] "" ACP3_MCU
 SG_ RawField73 : 435|10@0- (1,0) [0|0] "" ACP3_MCU
 SG_ RawField74 : 441|10@0- (1,0) [0|0] "" ACP3_MCU
 SG_ RawField75 : 463|10@0- (1,0) [0|0] "" ACP3_MCU
 SG_ RawField76 : 469|10@0- (1,0) [0|0] "" ACP3_MCU
 SG_ RawField77 : 475|32@0+ (1,0) [0|0] "" ACP3_MCU
 SG_ RawField78 : 504|4@1+ (1,0) [0|0] "" ACP3_MCU

BO_ 218 CAMERA_0DA: 64 FCM
 SG_ RawField01 : 3|11@0+ (1,0) [0|0] "" ACP3_MCU
 SG_ RawField02 : 4|2@1+ (1,0) [0|0] "" ACP3_MCU
 SG_ RawField03_RollingCounter : 6|2@1+ (1,0) [0|0] "" ACP3_MCU
 SG_ RawField04 : 8|10@0+ (1,0) [0|0] "" ACP3_MCU
 SG_ RawField05 : 28|11@0+ (1,0) [0|0] "" ACP3_MCU
 SG_ RawField06 : 29|2@1+ (1,0) [0|0] "" ACP3_MCU
 SG_ RawField07 : 33|10@0+ (1,0) [0|0] "" ACP3_MCU
 SG_ RawField08 : 51|11@0+ (1,0) [0|0] "" ACP3_MCU
 SG_ RawField09 : 52|2@1+ (1,0) [0|0] "" ACP3_MCU
 SG_ RawField10 : 54|2@1+ (1,0) [0|0] "" ACP3_MCU
 SG_ RawField11 : 56|10@0+ (1,0) [0|0] "" ACP3_MCU
 SG_ RawField12 : 76|11@0+ (1,0) [0|0] "" ACP3_MCU
 SG_ RawField13_Flag : 77|2@1+ (1,0) [0|0] "" ACP3_MCU
 SG_ RawField14 : 81|10@0+ (1,0) [0|0] "" ACP3_MCU
 SG_ RawField15 : 99|11@0+ (1,0) [0|0] "" ACP3_MCU
 SG_ RawField16 : 100|2@1+ (1,0) [0|0] "" ACP3_MCU
 SG_ RawField17 : 102|2@1+ (1,0) [0|0] "" ACP3_MCU
 SG_ RawField18 : 104|10@0+ (1,0) [0|0] "" ACP3_MCU
 SG_ RawField19 : 124|11@0+ (1,0) [0|0] "" ACP3_MCU
 SG_ RawField20_Flag : 125|2@1+ (1,0) [0|0] "" ACP3_MCU
 SG_ RawField21 : 129|10@0+ (1,0) [0|0] "" ACP3_MCU
 SG_ RawField22 : 147|11@0+ (1,0) [0|0] "" ACP3_MCU
 SG_ RawField23 : 148|2@1+ (1,0) [0|0] "" ACP3_MCU
 SG_ RawField24 : 150|2@1+ (1,0) [0|0] "" ACP3_MCU
 SG_ RawField25 : 152|10@0+ (1,0) [0|0] "" ACP3_MCU
 SG_ RawField26 : 172|11@0+ (1,0) [0|0] "" ACP3_MCU
 SG_ RawField27 : 173|2@1+ (1,0) [0|0] "" ACP3_MCU
 SG_ RawField28 : 177|10@0+ (1,0) [0|0] "" ACP3_MCU
 SG_ RawField29 : 195|11@0+ (1,0) [0|0] "" ACP3_MCU
 SG_ RawField30 : 196|2@1+ (1,0) [0|0] "" ACP3_MCU
 SG_ RawField31 : 198|2@1+ (1,0) [0|0] "" ACP3_MCU
 SG_ RawField32 : 200|10@0+ (1,0) [0|0] "" ACP3_MCU
 SG_ RawField33 : 220|11@0+ (1,0) [0|0] "" ACP3_MCU
 SG_ RawField34 : 221|2@1+ (1,0) [0|0] "" ACP3_MCU
 SG_ RawField35 : 225|10@0+ (1,0) [0|0] "" ACP3_MCU
 SG_ RawField36 : 243|11@0+ (1,0) [0|0] "" ACP3_MCU
 SG_ RawField37 : 244|2@1+ (1,0) [0|0] "" ACP3_MCU
 SG_ RawField38 : 246|2@1+ (1,0) [0|0] "" ACP3_MCU
 SG_ RawField39 : 248|10@0+ (1,0) [0|0] "" ACP3_MCU
 SG_ RawField40 : 268|11@0+ (1,0) [0|0] "" ACP3_MCU
 SG_ RawField41 : 269|2@1+ (1,0) [0|0] "" ACP3_MCU
 SG_ RawField42 : 273|10@0+ (1,0) [0|0] "" ACP3_MCU
 SG_ RawField43 : 291|11@0+ (1,0) [0|0] "" ACP3_MCU
 SG_ RawField44 : 292|2@1+ (1,0) [0|0] "" ACP3_MCU
 SG_ RawField45 : 294|2@1+ (1,0) [0|0] "" ACP3_MCU
 SG_ RawField46 : 296|10@0+ (1,0) [0|0] "" ACP3_MCU
 SG_ RawField47 : 316|11@0+ (1,0) [0|0] "" ACP3_MCU
 SG_ RawField48 : 317|2@1+ (1,0) [0|0] "" ACP3_MCU
 SG_ RawField49 : 321|10@0+ (1,0) [0|0] "" ACP3_MCU
 SG_ RawField50 : 339|11@0+ (1,0) [0|0] "" ACP3_MCU
 SG_ RawField51 : 340|2@1+ (1,0) [0|0] "" ACP3_MCU
 SG_ RawField52 : 342|2@1+ (1,0) [0|0] "" ACP3_MCU
 SG_ RawField53 : 344|10@0+ (1,0) [0|0] "" ACP3_MCU
 SG_ RawField54 : 364|11@0+ (1,0) [0|0] "" ACP3_MCU
 SG_ RawField55 : 365|2@1+ (1,0) [0|0] "" ACP3_MCU
 SG_ RawField56 : 369|10@0+ (1,0) [0|0] "" ACP3_MCU
 SG_ RawField57 : 387|11@0+ (1,0) [0|0] "" ACP3_MCU
 SG_ RawField58 : 388|2@1+ (1,0) [0|0] "" ACP3_MCU
 SG_ RawField59 : 390|2@1+ (1,0) [0|0] "" ACP3_MCU
 SG_ RawField60 : 392|10@0+ (1,0) [0|0] "" ACP3_MCU
 SG_ RawField61 : 412|11@0+ (1,0) [0|0] "" ACP3_MCU
 SG_ RawField62 : 413|2@1+ (1,0) [0|0] "" ACP3_MCU
 SG_ RawField63 : 417|10@0+ (1,0) [0|0] "" ACP3_MCU
 SG_ RawField64 : 435|11@0+ (1,0) [0|0] "" ACP3_MCU
 SG_ RawField65 : 436|2@1+ (1,0) [0|0] "" ACP3_MCU
 SG_ RawField66 : 438|2@1+ (1,0) [0|0] "" ACP3_MCU
 SG_ RawField67 : 440|10@0+ (1,0) [0|0] "" ACP3_MCU
 SG_ RawField68 : 460|11@0+ (1,0) [0|0] "" ACP3_MCU
 SG_ RawField69 : 461|2@1+ (1,0) [0|0] "" ACP3_MCU
 SG_ RawField70 : 465|10@0+ (1,0) [0|0] "" ACP3_MCU
 SG_ RawField71 : 481|26@0+ (1,0) [0|0] "" ACP3_MCU
 SG_ RawField72 : 482|2@1+ (1,0) [0|0] "" ACP3_MCU
 SG_ RawField73 : 484|2@1+ (1,0) [0|0] "" ACP3_MCU
 SG_ RawField74 : 486|2@1+ (1,0) [0|0] "" ACP3_MCU

BO_ 219 CAMERA_0DB: 64 FCM
 SG_ RawField01 : 4|2@1+ (1,0) [0|0] "" ACP3_MCU
 SG_ RightRoadEdgeCandidateCurvatureRaw : 3|16@0- (1,0) [0|0] "" ACP3_MCU
 SG_ RawField03_RollingCounter : 6|2@1+ (1,0) [0|0] "" ACP3_MCU
 SG_ RightRoadEdgeCandidateCurvatureRateRaw : 19|16@0- (1,0) [0|0] "" ACP3_MCU
 SG_ RawField05 : 35|7@0+ (1,0) [0|0] "" ACP3_MCU
 SG_ RawField06 : 44|7@0+ (1,0) [0|0] "" ACP3_MCU
 SG_ RawField07 : 53|7@0+ (1,0) [0|0] "" ACP3_MCU
 SG_ RawField08 : 56|7@1+ (1,0) [0|0] "" ACP3_MCU
 SG_ RightRoadEdgeCandidateHeadingRaw : 71|10@0- (1,0) [0|0] "" ACP3_MCU
 SG_ RightRoadEdgeCandidateOffsetEstimate : 77|13@0- (0.00390625,0) [-16|15.99609375] "m" ACP3_MCU
 SG_ RightRoadEdgeCandidateRoleCandidateRaw : 80|4@0+ (1,0) [0|0] "" ACP3_MCU
 SG_ RawField12 : 88|3@1+ (1,0) [0|0] "" ACP3_MCU
 SG_ RightRoadEdgeCandidateActivityCandidateRaw : 91|2@1+ (1,0) [0|0] "" ACP3_MCU
 SG_ RightRoadEdgeCandidateRangeEndEstimate : 97|7@1+ (1,0) [0|127] "m" ACP3_MCU
 SG_ RightRoadEdgeCandidateRangeStartEstimate : 96|7@0+ (1,0) [0|127] "m" ACP3_MCU
 SG_ RawField16 : 105|6@0+ (1,0) [0|0] "" ACP3_MCU
 SG_ RawField17 : 114|2@1+ (1,0) [0|0] "" ACP3_MCU
 SG_ RawField18 : 113|6@0+ (1,0) [0|0] "" ACP3_MCU
 SG_ RawField19 : 122|2@1+ (1,0) [0|0] "" ACP3_MCU
 SG_ RawField20 : 121|3@0+ (1,0) [0|0] "" ACP3_MCU
 SG_ Object0OrientationCandidateRaw : 133|11@0- (1,0) [0|0] "" ACP3_MCU
 SG_ RawField22 : 134|1@1+ (1,0) [0|0] "" ACP3_MCU
 SG_ RawField23 : 138|13@0- (1,0) [0|0] "" ACP3_MCU
 SG_ Object0IdCandidate : 152|6@1+ (1,0) [0|0] "" ACP3_MCU
 SG_ RawField25 : 162|9@0- (1,0) [0|0] "" ACP3_MCU
 SG_ RawField26 : 163|2@1+ (1,0) [0|0] "" ACP3_MCU
 SG_ RawField27 : 165|3@1+ (1,0) [0|0] "" ACP3_MCU
 SG_ RawField28 : 169|9@0- (1,0) [0|0] "" ACP3_MCU
 SG_ Object0LongitudinalEstimate : 176|11@0+ (0.125,0) [0|255.875] "m" ACP3_MCU
 SG_ RawField30 : 197|15@0+ (1,0) [0|0] "" ACP3_MCU
 SG_ Object0RelativeLongitudinalVelocityEstimate : 214|11@0- (0.125,0) [-128|127.875] "m/s" ACP3_MCU
 SG_ RawField32 : 219|10@0+ (1,0) [0|0] "" ACP3_MCU
 SG_ Object0LateralEstimate : 225|10@0- (0.125,0) [-64|63.875] "m" ACP3_MCU
 SG_ RawField34 : 247|14@0+ (1,0) [0|0] "" ACP3_MCU
 SG_ Object0RelativeLateralVelocityEstimate : 249|9@0- (0.125,0) [-32|31.875] "m/s" ACP3_MCU
 SG_ RawField36 : 256|10@0+ (1,0) [0|0] "" ACP3_MCU
 SG_ RawField37 : 272|7@1+ (1,0) [0|0] "" ACP3_MCU
 SG_ Object0StateCandidateRaw : 281|2@1+ (1,0) [0|0] "" ACP3_MCU
 SG_ RawField39 : 283|2@1+ (1,0) [0|0] "" ACP3_MCU
 SG_ RawField40 : 285|3@1+ (1,0) [0|0] "" ACP3_MCU
 SG_ RawField41 : 280|2@0+ (1,0) [0|0] "" ACP3_MCU
 SG_ RawField42 : 289|6@1+ (1,0) [0|0] "" ACP3_MCU
 SG_ RawField43 : 288|2@0+ (1,0) [0|0] "" ACP3_MCU
 SG_ Object1OrientationCandidateRaw : 298|11@0- (1,0) [0|0] "" ACP3_MCU
 SG_ RawField45 : 299|1@1+ (1,0) [0|0] "" ACP3_MCU
 SG_ RawField46 : 300|3@1+ (1,0) [0|0] "" ACP3_MCU
 SG_ RawField47 : 319|13@0- (1,0) [0|0] "" ACP3_MCU
 SG_ Object1IdCandidate : 322|6@0+ (1,0) [0|0] "" ACP3_MCU
 SG_ RawField49 : 328|2@1+ (1,0) [0|0] "" ACP3_MCU
 SG_ RawField50 : 330|3@1+ (1,0) [0|0] "" ACP3_MCU
 SG_ RawField51 : 343|9@0- (1,0) [0|0] "" ACP3_MCU
 SG_ RawField52 : 350|9@0- (1,0) [0|0] "" ACP3_MCU
 SG_ Object1LongitudinalEstimate : 357|11@0+ (0.125,0) [0|255.875] "m" ACP3_MCU
 SG_ RawField54 : 362|15@0+ (1,0) [0|0] "" ACP3_MCU
 SG_ Object1RelativeLongitudinalVelocityEstimate : 379|11@0- (0.125,0) [-128|127.875] "m/s" ACP3_MCU
 SG_ RawField56 : 384|10@0+ (1,0) [0|0] "" ACP3_MCU
 SG_ Object1LateralEstimate : 406|10@0- (0.125,0) [-64|63.875] "m" ACP3_MCU
 SG_ RawField58 : 412|14@0+ (1,0) [0|0] "" ACP3_MCU
 SG_ Object1RelativeLateralVelocityEstimate : 430|9@0- (0.125,0) [-32|31.875] "m/s" ACP3_MCU
 SG_ RawField60 : 437|10@0+ (1,0) [0|0] "" ACP3_MCU
 SG_ RawField61 : 443|7@0+ (1,0) [0|0] "" ACP3_MCU
 SG_ RawField62 : 448|2@1+ (1,0) [0|0] "" ACP3_MCU
 SG_ RawField63 : 450|3@1+ (1,0) [0|0] "" ACP3_MCU
 SG_ RawField64 : 458|2@1+ (1,0) [0|0] "" ACP3_MCU
 SG_ RawField65 : 460|2@1+ (1,0) [0|0] "" ACP3_MCU
 SG_ Object1StateCandidateRaw : 462|2@1+ (1,0) [0|0] "" ACP3_MCU
 SG_ RawField67 : 457|28@0+ (1,0) [0|0] "" ACP3_MCU
 SG_ RawField68 : 493|19@0+ (1,0) [0|0] "" ACP3_MCU

BO_ 220 CAMERA_0DC: 64 FCM
 SG_ RawField01 : 4|2@1+ (1,0) [0|0] "" ACP3_MCU
 SG_ RawField02 : 3|16@0- (1,0) [0|0] "" ACP3_MCU
 SG_ RawField03_RollingCounter : 6|2@1+ (1,0) [0|0] "" ACP3_MCU
 SG_ RawField04 : 19|16@0- (1,0) [0|0] "" ACP3_MCU
 SG_ RawField05 : 35|7@0+ (1,0) [0|0] "" ACP3_MCU
 SG_ RawField06 : 44|7@0+ (1,0) [0|0] "" ACP3_MCU
 SG_ RawField07 : 53|7@0+ (1,0) [0|0] "" ACP3_MCU
 SG_ RawField08 : 56|7@1+ (1,0) [0|0] "" ACP3_MCU
 SG_ RawField09 : 71|10@0- (1,0) [0|0] "" ACP3_MCU
 SG_ RightSecondaryBoundaryCandidateOffsetEstimate : 77|13@0- (0.00390625,0) [-16|15.99609375] "m" ACP3_MCU
 SG_ RightSecondaryBoundaryCandidateRoleCandidateRaw : 80|4@0+ (1,0) [0|0] "" ACP3_MCU
 SG_ RawField12 : 88|3@1+ (1,0) [0|0] "" ACP3_MCU
 SG_ RightSecondaryBoundaryCandidateActivityCandidateRaw : 91|2@1+ (1,0) [0|0] "" ACP3_MCU
 SG_ RightSecondaryBoundaryCandidateRangeEndEstimate : 97|7@1+ (1,0) [0|127] "m" ACP3_MCU
 SG_ RightSecondaryBoundaryCandidateRangeStartEstimate : 96|7@0+ (1,0) [0|127] "m" ACP3_MCU
 SG_ RawField16 : 105|6@0+ (1,0) [0|0] "" ACP3_MCU
 SG_ RawField17 : 114|2@1+ (1,0) [0|0] "" ACP3_MCU
 SG_ RawField18 : 113|6@0+ (1,0) [0|0] "" ACP3_MCU
 SG_ RawField19 : 122|2@1+ (1,0) [0|0] "" ACP3_MCU
 SG_ RawField20 : 121|3@0+ (1,0) [0|0] "" ACP3_MCU
 SG_ Object0OrientationCandidateRaw : 133|11@0- (1,0) [0|0] "" ACP3_MCU
 SG_ RawField22 : 134|1@1+ (1,0) [0|0] "" ACP3_MCU
 SG_ RawField23 : 138|13@0- (1,0) [0|0] "" ACP3_MCU
 SG_ Object0IdCandidate : 152|6@1+ (1,0) [0|0] "" ACP3_MCU
 SG_ RawField25 : 162|9@0- (1,0) [0|0] "" ACP3_MCU
 SG_ RawField26 : 163|2@1+ (1,0) [0|0] "" ACP3_MCU
 SG_ RawField27 : 165|3@1+ (1,0) [0|0] "" ACP3_MCU
 SG_ RawField28 : 169|9@0- (1,0) [0|0] "" ACP3_MCU
 SG_ Object0LongitudinalEstimate : 176|11@0+ (0.125,0) [0|255.875] "m" ACP3_MCU
 SG_ RawField30 : 197|15@0+ (1,0) [0|0] "" ACP3_MCU
 SG_ Object0RelativeLongitudinalVelocityEstimate : 214|11@0- (0.125,0) [-128|127.875] "m/s" ACP3_MCU
 SG_ RawField32 : 219|10@0+ (1,0) [0|0] "" ACP3_MCU
 SG_ Object0LateralEstimate : 225|10@0- (0.125,0) [-64|63.875] "m" ACP3_MCU
 SG_ RawField34 : 247|14@0+ (1,0) [0|0] "" ACP3_MCU
 SG_ Object0RelativeLateralVelocityEstimate : 249|9@0- (0.125,0) [-32|31.875] "m/s" ACP3_MCU
 SG_ RawField36 : 256|10@0+ (1,0) [0|0] "" ACP3_MCU
 SG_ RawField37 : 272|7@1+ (1,0) [0|0] "" ACP3_MCU
 SG_ Object0StateCandidateRaw : 281|2@1+ (1,0) [0|0] "" ACP3_MCU
 SG_ RawField39 : 283|2@1+ (1,0) [0|0] "" ACP3_MCU
 SG_ RawField40 : 285|3@1+ (1,0) [0|0] "" ACP3_MCU
 SG_ RawField41 : 280|2@0+ (1,0) [0|0] "" ACP3_MCU
 SG_ RawField42 : 289|6@1+ (1,0) [0|0] "" ACP3_MCU
 SG_ RawField43 : 288|2@0+ (1,0) [0|0] "" ACP3_MCU
 SG_ Object1OrientationCandidateRaw : 298|11@0- (1,0) [0|0] "" ACP3_MCU
 SG_ RawField45 : 299|1@1+ (1,0) [0|0] "" ACP3_MCU
 SG_ RawField46 : 300|3@1+ (1,0) [0|0] "" ACP3_MCU
 SG_ RawField47 : 319|13@0- (1,0) [0|0] "" ACP3_MCU
 SG_ Object1IdCandidate : 322|6@0+ (1,0) [0|0] "" ACP3_MCU
 SG_ RawField49 : 328|2@1+ (1,0) [0|0] "" ACP3_MCU
 SG_ RawField50 : 330|3@1+ (1,0) [0|0] "" ACP3_MCU
 SG_ RawField51 : 343|9@0- (1,0) [0|0] "" ACP3_MCU
 SG_ RawField52 : 350|9@0- (1,0) [0|0] "" ACP3_MCU
 SG_ Object1LongitudinalEstimate : 357|11@0+ (0.125,0) [0|255.875] "m" ACP3_MCU
 SG_ RawField54 : 362|15@0+ (1,0) [0|0] "" ACP3_MCU
 SG_ Object1RelativeLongitudinalVelocityEstimate : 379|11@0- (0.125,0) [-128|127.875] "m/s" ACP3_MCU
 SG_ RawField56 : 384|10@0+ (1,0) [0|0] "" ACP3_MCU
 SG_ Object1LateralEstimate : 406|10@0- (0.125,0) [-64|63.875] "m" ACP3_MCU
 SG_ RawField58 : 412|14@0+ (1,0) [0|0] "" ACP3_MCU
 SG_ Object1RelativeLateralVelocityEstimate : 430|9@0- (0.125,0) [-32|31.875] "m/s" ACP3_MCU
 SG_ RawField60 : 437|10@0+ (1,0) [0|0] "" ACP3_MCU
 SG_ RawField61 : 443|7@0+ (1,0) [0|0] "" ACP3_MCU
 SG_ RawField62 : 448|2@1+ (1,0) [0|0] "" ACP3_MCU
 SG_ RawField63 : 450|3@1+ (1,0) [0|0] "" ACP3_MCU
 SG_ RawField64 : 458|2@1+ (1,0) [0|0] "" ACP3_MCU
 SG_ RawField65 : 460|2@1+ (1,0) [0|0] "" ACP3_MCU
 SG_ Object1StateCandidateRaw : 462|2@1+ (1,0) [0|0] "" ACP3_MCU
 SG_ RawField67 : 457|28@0+ (1,0) [0|0] "" ACP3_MCU
 SG_ RawField68 : 493|22@0+ (1,0) [0|0] "" ACP3_MCU

BO_ 221 CAMERA_0DD: 64 FCM
 SG_ RawField01 : 4|2@1+ (1,0) [0|0] "" ACP3_MCU
 SG_ RawField02 : 3|16@0- (1,0) [0|0] "" ACP3_MCU
 SG_ RawField03_RollingCounter : 6|2@1+ (1,0) [0|0] "" ACP3_MCU
 SG_ RawField04 : 19|16@0- (1,0) [0|0] "" ACP3_MCU
 SG_ RawField05 : 35|7@0+ (1,0) [0|0] "" ACP3_MCU
 SG_ RawField06 : 44|7@0+ (1,0) [0|0] "" ACP3_MCU
 SG_ RawField07 : 53|7@0+ (1,0) [0|0] "" ACP3_MCU
 SG_ RawField08 : 56|7@1+ (1,0) [0|0] "" ACP3_MCU
 SG_ RawField09 : 71|10@0- (1,0) [0|0] "" ACP3_MCU
 SG_ RawField10 : 77|13@0- (1,0) [0|0] "" ACP3_MCU
 SG_ RawField11 : 80|4@0+ (1,0) [0|0] "" ACP3_MCU
 SG_ RawField12 : 88|3@1+ (1,0) [0|0] "" ACP3_MCU
 SG_ RawField13 : 91|2@1+ (1,0) [0|0] "" ACP3_MCU
 SG_ RawField14 : 97|7@1+ (1,0) [0|0] "" ACP3_MCU
 SG_ RawField15 : 96|7@0+ (1,0) [0|0] "" ACP3_MCU
 SG_ RawField16 : 105|6@0+ (1,0) [0|0] "" ACP3_MCU
 SG_ RawField17 : 114|2@1+ (1,0) [0|0] "" ACP3_MCU
 SG_ OuterRightLaneCandidateCurvatureRaw : 113|16@0- (1,0) [0|0] "" ACP3_MCU
 SG_ OuterRightLaneCandidateCurvatureRateRaw : 129|16@0- (1,0) [0|0] "" ACP3_MCU
 SG_ OuterRightLaneCandidateSupportRaw : 145|7@0+ (1,0) [0|0] "" ACP3_MCU
 SG_ RawField21 : 154|7@0+ (1,0) [0|0] "" ACP3_MCU
 SG_ RawField22 : 163|7@0+ (1,0) [0|0] "" ACP3_MCU
 SG_ RawField23 : 172|7@0+ (1,0) [0|0] "" ACP3_MCU
 SG_ OuterRightLaneCandidateHeadingRaw : 181|10@0- (1,0) [0|0] "" ACP3_MCU
 SG_ OuterRightLaneCandidateOffsetEstimate : 187|13@0- (0.00390625,0) [-16|15.99609375] "m" ACP3_MCU
 SG_ OuterRightLaneCandidateActivityCandidateRaw : 201|2@1+ (1,0) [0|0] "" ACP3_MCU
 SG_ OuterRightLaneCandidateRoleCandidateRaw : 203|4@1+ (1,0) [0|0] "" ACP3_MCU
 SG_ RawField28 : 200|3@0+ (1,0) [0|0] "" ACP3_MCU
 SG_ OuterRightLaneCandidateRangeEndEstimate : 213|7@0+ (1,0) [0|127] "m" ACP3_MCU
 SG_ OuterRightLaneCandidateRangeStartEstimate : 216|7@1+ (1,0) [0|127] "m" ACP3_MCU
 SG_ RawField31 : 224|2@1+ (1,0) [0|0] "" ACP3_MCU
 SG_ RawField32 : 226|6@1+ (1,0) [0|0] "" ACP3_MCU
 SG_ RawField33 : 237|3@1+ (1,0) [0|0] "" ACP3_MCU
 SG_ RawField34 : 236|6@0+ (1,0) [0|0] "" ACP3_MCU
 SG_ RawField35 : 241|6@1+ (1,0) [0|0] "" ACP3_MCU
 SG_ RawField36 : 240|2@0+ (1,0) [0|0] "" ACP3_MCU
 SG_ RawField37 : 254|9@0- (1,0) [0|0] "" ACP3_MCU
 SG_ RawField38 : 261|9@0- (1,0) [0|0] "" ACP3_MCU
 SG_ RawField39 : 268|11@0+ (1,0) [0|0] "" ACP3_MCU
 SG_ RawField40 : 273|10@0- (1,0) [0|0] "" ACP3_MCU
 SG_ RawField41 : 295|10@0- (1,0) [0|0] "" ACP3_MCU
 SG_ RawField42 : 301|9@0- (1,0) [0|0] "" ACP3_MCU
 SG_ RawField43 : 305|2@1+ (1,0) [0|0] "" ACP3_MCU
 SG_ RawField44 : 307|2@1+ (1,0) [0|0] "" ACP3_MCU
 SG_ RawField45 : 304|2@0+ (1,0) [0|0] "" ACP3_MCU
 SG_ RawField46 : 313|6@1+ (1,0) [0|0] "" ACP3_MCU
 SG_ RawField47 : 312|2@0+ (1,0) [0|0] "" ACP3_MCU
 SG_ Object0OrientationCandidateRaw : 322|11@0- (1,0) [0|0] "" ACP3_MCU
 SG_ RawField49 : 323|1@1+ (1,0) [0|0] "" ACP3_MCU
 SG_ RawField50 : 324|3@1+ (1,0) [0|0] "" ACP3_MCU
 SG_ RawField51 : 343|13@0- (1,0) [0|0] "" ACP3_MCU
 SG_ Object0IdCandidate : 346|6@0+ (1,0) [0|0] "" ACP3_MCU
 SG_ RawField53 : 352|2@1+ (1,0) [0|0] "" ACP3_MCU
 SG_ RawField54 : 354|3@1+ (1,0) [0|0] "" ACP3_MCU
 SG_ RawField55 : 367|9@0- (1,0) [0|0] "" ACP3_MCU
 SG_ RawField56 : 374|9@0- (1,0) [0|0] "" ACP3_MCU
 SG_ Object0LongitudinalEstimate : 381|11@0+ (0.125,0) [0|255.875] "m" ACP3_MCU
 SG_ RawField58 : 386|15@0+ (1,0) [0|0] "" ACP3_MCU
 SG_ Object0RelativeLongitudinalVelocityEstimate : 403|11@0- (0.125,0) [-128|127.875] "m/s" ACP3_MCU
 SG_ RawField60 : 408|10@0+ (1,0) [0|0] "" ACP3_MCU
 SG_ Object0LateralEstimate : 430|10@0- (0.125,0) [-64|63.875] "m" ACP3_MCU
 SG_ RawField62 : 436|14@0+ (1,0) [0|0] "" ACP3_MCU
 SG_ Object0RelativeLateralVelocityEstimate : 454|9@0- (0.125,0) [-32|31.875] "m/s" ACP3_MCU
 SG_ RawField64 : 461|10@0+ (1,0) [0|0] "" ACP3_MCU
 SG_ RawField65 : 467|7@0+ (1,0) [0|0] "" ACP3_MCU
 SG_ RawField66 : 472|2@1+ (1,0) [0|0] "" ACP3_MCU
 SG_ RawField67 : 474|3@1+ (1,0) [0|0] "" ACP3_MCU
 SG_ RawField68 : 480|2@1+ (1,0) [0|0] "" ACP3_MCU
 SG_ RawField69 : 482|2@1+ (1,0) [0|0] "" ACP3_MCU
 SG_ RawField70 : 484|2@1+ (1,0) [0|0] "" ACP3_MCU
 SG_ Object0StateCandidateRaw : 486|2@1+ (1,0) [0|0] "" ACP3_MCU
 SG_ RawField72 : 495|24@0+ (1,0) [0|0] "" ACP3_MCU

BO_ 222 CAMERA_0DE: 64 FCM
 SG_ RawField01 : 4|2@1+ (1,0) [0|0] "" ACP3_MCU
 SG_ RawField02 : 3|6@0+ (1,0) [0|0] "" ACP3_MCU
 SG_ RawField03_RollingCounter : 6|2@1+ (1,0) [0|0] "" ACP3_MCU
 SG_ RawField04 : 12|2@1+ (1,0) [0|0] "" ACP3_MCU
 SG_ RawField05 : 11|7@0+ (1,0) [0|0] "" ACP3_MCU
 SG_ RawField06 : 16|3@1+ (1,0) [0|0] "" ACP3_MCU
 SG_ RawField07 : 19|2@1+ (1,0) [0|0] "" ACP3_MCU
 SG_ RawField08_Flag : 24|1@1+ (1,0) [0|0] "" ACP3_MCU
 SG_ RawField09 : 25|3@1+ (1,0) [0|0] "" ACP3_MCU
 SG_ RawField10 : 28|4@1+ (1,0) [0|0] "" ACP3_MCU
 SG_ RawField11 : 36|11@0+ (1,0) [0|0] "" ACP3_MCU
 SG_ RawField12 : 37|3@1+ (1,0) [0|0] "" ACP3_MCU
 SG_ RawField13 : 41|1@1+ (1,0) [0|0] "" ACP3_MCU
 SG_ RawField14 : 40|2@0+ (1,0) [0|0] "" ACP3_MCU
 SG_ RightLaneCurvatureRaw : 54|16@0- (1,0) [0|0] "" ACP3_MCU
 SG_ RawField16 : 70|16@0- (1,0) [0|0] "" ACP3_MCU
 SG_ RawField17 : 80|7@1+ (1,0) [0|0] "" ACP3_MCU
 SG_ RawField18 : 89|7@1+ (1,0) [0|0] "" ACP3_MCU
 SG_ RawField19 : 88|7@0+ (1,0) [0|0] "" ACP3_MCU
 SG_ RawField20 : 97|7@0+ (1,0) [0|0] "" ACP3_MCU
 SG_ RightLaneHeadingRaw : 106|10@0- (1,0) [0|0] "" ACP3_MCU
 SG_ RightLaneOffsetEstimate : 112|13@0- (0.00390625,0) [-16|15.99609375] "m" ACP3_MCU
 SG_ RightLaneRoleCandidateRaw : 128|4@1+ (1,0) [0|0] "" ACP3_MCU
 SG_ RightLaneStateRaw : 139|3@1+ (1,0) [0|0] "" ACP3_MCU
 SG_ RightLaneRangeEndEstimate : 138|7@0+ (1,0) [0|127] "m" ACP3_MCU
 SG_ RightLaneActivityCandidateRaw : 142|2@1+ (1,0) [0|0] "" ACP3_MCU
 SG_ RightLaneRangeStartEstimate : 147|7@0+ (1,0) [0|127] "m" ACP3_MCU
 SG_ RawField28 : 156|6@0+ (1,0) [0|0] "" ACP3_MCU
 SG_ RawField29 : 162|5@1+ (1,0) [0|0] "" ACP3_MCU
 SG_ RawField30 : 161|8@0+ (1,0) [0|0] "" ACP3_MCU
 SG_ RawField31 : 169|1@1+ (1,0) [0|0] "" ACP3_MCU
 SG_ RawField32 : 168|6@0+ (1,0) [0|0] "" ACP3_MCU
 SG_ RawField33 : 176|3@1+ (1,0) [0|0] "" ACP3_MCU
 SG_ RawField34 : 187|3@1+ (1,0) [0|0] "" ACP3_MCU
 SG_ RawField35 : 186|6@0+ (1,0) [0|0] "" ACP3_MCU
 SG_ RawField36 : 190|2@1+ (1,0) [0|0] "" ACP3_MCU
 SG_ RawField37 : 196|6@0+ (1,0) [0|0] "" ACP3_MCU
 SG_ RawField38 : 204|9@0- (1,0) [0|0] "" ACP3_MCU
 SG_ RawField39 : 205|2@1+ (1,0) [0|0] "" ACP3_MCU
 SG_ RawField40 : 211|9@0- (1,0) [0|0] "" ACP3_MCU
 SG_ RawField41 : 218|11@0+ (1,0) [0|0] "" ACP3_MCU
 SG_ RawField42 : 239|10@0- (1,0) [0|0] "" ACP3_MCU
 SG_ RawField43 : 245|10@0- (1,0) [0|0] "" ACP3_MCU
 SG_ RawField44 : 251|9@0- (1,0) [0|0] "" ACP3_MCU
 SG_ RawField45 : 257|2@1+ (1,0) [0|0] "" ACP3_MCU
 SG_ RawField46 : 256|2@0+ (1,0) [0|0] "" ACP3_MCU
 SG_ RawField47 : 266|5@1+ (1,0) [0|0] "" ACP3_MCU
 SG_ RawField48 : 265|8@0+ (1,0) [0|0] "" ACP3_MCU
 SG_ RawField49 : 273|1@1+ (1,0) [0|0] "" ACP3_MCU
 SG_ RawField50 : 272|4@0+ (1,0) [0|0] "" ACP3_MCU
 SG_ RawField51 : 282|2@1+ (1,0) [0|0] "" ACP3_MCU
 SG_ RawField52 : 281|8@0+ (1,0) [0|0] "" ACP3_MCU
 SG_ RawField53 : 284|1@1+ (1,0) [0|0] "" ACP3_MCU
 SG_ RawField54 : 289|1@1+ (1,0) [0|0] "" ACP3_MCU
 SG_ RawField55_Flag : 288|2@0+ (1,0) [0|0] "" ACP3_MCU
 SG_ RawField56 : 297|6@1+ (1,0) [0|0] "" ACP3_MCU
 SG_ RawField57_Flag : 296|2@0+ (1,0) [0|0] "" ACP3_MCU
 SG_ Object0OrientationCandidateRaw : 306|11@0- (1,0) [0|0] "" ACP3_MCU
 SG_ RawField59 : 307|1@1+ (1,0) [0|0] "" ACP3_MCU
 SG_ RawField60 : 308|3@1+ (1,0) [0|0] "" ACP3_MCU
 SG_ RawField61 : 327|13@0- (1,0) [0|0] "" ACP3_MCU
 SG_ Object0IdCandidate : 330|6@0+ (1,0) [0|0] "" ACP3_MCU
 SG_ RawField63 : 336|2@1+ (1,0) [0|0] "" ACP3_MCU
 SG_ RawField64 : 338|3@1+ (1,0) [0|0] "" ACP3_MCU
 SG_ RawField65 : 351|9@0- (1,0) [0|0] "" ACP3_MCU
 SG_ RawField66 : 358|9@0- (1,0) [0|0] "" ACP3_MCU
 SG_ Object0LongitudinalEstimate : 365|11@0+ (0.125,0) [0|255.875] "m" ACP3_MCU
 SG_ RawField68 : 370|15@0+ (1,0) [0|0] "" ACP3_MCU
 SG_ Object0RelativeLongitudinalVelocityEstimate : 387|11@0- (0.125,0) [-128|127.875] "m/s" ACP3_MCU
 SG_ RawField70 : 392|10@0+ (1,0) [0|0] "" ACP3_MCU
 SG_ Object0LateralEstimate : 414|10@0- (0.125,0) [-64|63.875] "m" ACP3_MCU
 SG_ RawField72 : 420|14@0+ (1,0) [0|0] "" ACP3_MCU
 SG_ Object0RelativeLateralVelocityEstimate : 438|9@0- (0.125,0) [-32|31.875] "m/s" ACP3_MCU
 SG_ RawField74 : 445|10@0+ (1,0) [0|0] "" ACP3_MCU
 SG_ RawField75 : 451|7@0+ (1,0) [0|0] "" ACP3_MCU
 SG_ RawField76 : 456|2@1+ (1,0) [0|0] "" ACP3_MCU
 SG_ RawField77 : 458|3@1+ (1,0) [0|0] "" ACP3_MCU
 SG_ RawField78 : 466|4@1+ (1,0) [0|0] "" ACP3_MCU
 SG_ Object0StateCandidateRaw : 470|2@1+ (1,0) [0|0] "" ACP3_MCU
 SG_ RawField80 : 465|3@0+ (1,0) [0|0] "" ACP3_MCU
 SG_ RawField81 : 473|6@1+ (1,0) [0|0] "" ACP3_MCU
 SG_ RawField82 : 472|6@0+ (1,0) [0|0] "" ACP3_MCU
 SG_ RawField83 : 480|1@1+ (1,0) [0|0] "" ACP3_MCU
 SG_ RawField84 : 481|1@1+ (1,0) [0|0] "" ACP3_MCU
 SG_ RawField85 : 482|1@1+ (1,0) [0|0] "" ACP3_MCU
 SG_ RawField86 : 489|2@1+ (1,0) [0|0] "" ACP3_MCU
 SG_ RawField87 : 491|2@1+ (1,0) [0|0] "" ACP3_MCU
 SG_ RawField88 : 493|1@1+ (1,0) [0|0] "" ACP3_MCU
 SG_ RawField89 : 494|1@1+ (1,0) [0|0] "" ACP3_MCU
 SG_ RawField90 : 495|1@1+ (1,0) [0|0] "" ACP3_MCU
 SG_ RawField91 : 488|2@0+ (1,0) [0|0] "" ACP3_MCU
 SG_ RawField92 : 502|15@0+ (1,0) [0|0] "" ACP3_MCU

BO_ 233 CAMERA_0E9: 64 FCM
 SG_ RawField01_Entropy : 7|32@0+ (1,0) [0|0] "" ACP3_MCU
 SG_ RawField02_Counter : 35|5@1+ (1,0) [0|0] "" ACP3_MCU
 SG_ LeftLaneStateRaw : 44|2@1+ (1,0) [0|0] "" ACP3_MCU
 SG_ LeftLaneCurvatureRaw : 43|16@0- (1,0) [0|0] "" ACP3_MCU
 SG_ RawField05_RollingCounter : 46|2@1+ (1,0) [0|0] "" ACP3_MCU
 SG_ RawField06 : 59|16@0- (1,0) [0|0] "" ACP3_MCU
 SG_ RawField07 : 75|7@0+ (1,0) [0|0] "" ACP3_MCU
 SG_ RawField08 : 84|7@0+ (1,0) [0|0] "" ACP3_MCU
 SG_ RawField09 : 93|7@0+ (1,0) [0|0] "" ACP3_MCU
 SG_ RawField10 : 96|7@1+ (1,0) [0|0] "" ACP3_MCU
 SG_ LeftLaneHeadingRaw : 111|10@0- (1,0) [0|0] "" ACP3_MCU
 SG_ LeftLaneOffsetEstimate : 117|13@0- (0.00390625,0) [-16|15.99609375] "m" ACP3_MCU
 SG_ LeftLaneRoleCandidateRaw : 120|4@0+ (1,0) [0|0] "" ACP3_MCU
 SG_ RawField14 : 128|3@1+ (1,0) [0|0] "" ACP3_MCU
 SG_ LeftLaneActivityCandidateRaw : 131|2@1+ (1,0) [0|0] "" ACP3_MCU
 SG_ LeftLaneRangeEndEstimate : 137|7@1+ (1,0) [0|127] "m" ACP3_MCU
 SG_ LeftLaneRangeStartEstimate : 136|7@0+ (1,0) [0|127] "m" ACP3_MCU
 SG_ RawField18 : 145|6@0+ (1,0) [0|0] "" ACP3_MCU
 SG_ RawField19 : 154|2@1+ (1,0) [0|0] "" ACP3_MCU
 SG_ RawField20 : 153|3@0+ (1,0) [0|0] "" ACP3_MCU
 SG_ RawField21 : 161|6@1+ (1,0) [0|0] "" ACP3_MCU
 SG_ RawField22 : 160|6@0+ (1,0) [0|0] "" ACP3_MCU
 SG_ RawField23 : 168|9@0- (1,0) [0|0] "" ACP3_MCU
 SG_ RawField24 : 169|2@1+ (1,0) [0|0] "" ACP3_MCU
 SG_ RawField25 : 191|9@0- (1,0) [0|0] "" ACP3_MCU
 SG_ RawField26 : 198|11@0+ (1,0) [0|0] "" ACP3_MCU
 SG_ RawField27 : 203|10@0- (1,0) [0|0] "" ACP3_MCU
 SG_ RawField28 : 209|10@0- (1,0) [0|0] "" ACP3_MCU
 SG_ RawField29 : 231|9@0- (1,0) [0|0] "" ACP3_MCU
 SG_ RawField30_Flag : 233|2@1+ (1,0) [0|0] "" ACP3_MCU
 SG_ RawField31 : 235|2@1+ (1,0) [0|0] "" ACP3_MCU
 SG_ RawField32 : 232|6@0+ (1,0) [0|0] "" ACP3_MCU
 SG_ RawField33 : 237|2@1+ (1,0) [0|0] "" ACP3_MCU
 SG_ RawField34_Flag : 241|2@1+ (1,0) [0|0] "" ACP3_MCU
 SG_ RawField35 : 240|3@0+ (1,0) [0|0] "" ACP3_MCU
 SG_ Object0OrientationCandidateRaw : 252|11@0- (1,0) [0|0] "" ACP3_MCU
 SG_ RawField37 : 253|1@1+ (1,0) [0|0] "" ACP3_MCU
 SG_ RawField38 : 257|13@0- (1,0) [0|0] "" ACP3_MCU
 SG_ Object0IdCandidate : 276|6@0+ (1,0) [0|0] "" ACP3_MCU
 SG_ RawField40 : 281|9@0- (1,0) [0|0] "" ACP3_MCU
 SG_ RawField41 : 282|2@1+ (1,0) [0|0] "" ACP3_MCU
 SG_ RawField42 : 284|3@1+ (1,0) [0|0] "" ACP3_MCU
 SG_ RawField43 : 288|9@0- (1,0) [0|0] "" ACP3_MCU
 SG_ Object0LongitudinalEstimate : 311|11@0+ (0.125,0) [0|255.875] "m" ACP3_MCU
 SG_ RawField45 : 316|15@0+ (1,0) [0|0] "" ACP3_MCU
 SG_ Object0RelativeLongitudinalVelocityEstimate : 333|11@0- (0.125,0) [-128|127.875] "m/s" ACP3_MCU
 SG_ RawField47 : 338|10@0+ (1,0) [0|0] "" ACP3_MCU
 SG_ Object0LateralEstimate : 344|10@0- (0.125,0) [-64|63.875] "m" ACP3_MCU
 SG_ RawField49 : 366|14@0+ (1,0) [0|0] "" ACP3_MCU
 SG_ Object0RelativeLateralVelocityEstimate : 368|9@0- (0.125,0) [-32|31.875] "m/s" ACP3_MCU
 SG_ RawField51 : 391|10@0+ (1,0) [0|0] "" ACP3_MCU
 SG_ RawField52 : 397|7@0+ (1,0) [0|0] "" ACP3_MCU
 SG_ Object0StateCandidateRaw : 400|2@1+ (1,0) [0|0] "" ACP3_MCU
 SG_ RawField54 : 402|2@1+ (1,0) [0|0] "" ACP3_MCU
 SG_ RawField55 : 404|3@1+ (1,0) [0|0] "" ACP3_MCU
 SG_ RawField56 : 413|9@0- (1,0) [0|0] "" ACP3_MCU
 SG_ RawField57_RollingCounter : 414|2@1+ (1,0) [0|0] "" ACP3_MCU
 SG_ RawField58 : 420|9@0- (1,0) [0|0] "" ACP3_MCU
 SG_ RawField59 : 427|9@0- (1,0) [0|0] "" ACP3_MCU
 SG_ RawField60 : 434|9@0- (1,0) [0|0] "" ACP3_MCU
 SG_ RawField61 : 441|9@0- (1,0) [0|0] "" ACP3_MCU
 SG_ RawField62 : 448|9@0- (1,0) [0|0] "" ACP3_MCU
 SG_ RawField63 : 471|9@0- (1,0) [0|0] "" ACP3_MCU
 SG_ RawField64 : 478|9@0- (1,0) [0|0] "" ACP3_MCU
 SG_ RawField65 : 485|9@0- (1,0) [0|0] "" ACP3_MCU
 SG_ RawField66 : 492|9@0- (1,0) [0|0] "" ACP3_MCU
 SG_ RawField67 : 496|2@1+ (1,0) [0|0] "" ACP3_MCU
 SG_ RawField68 : 498|2@1+ (1,0) [0|0] "" ACP3_MCU
 SG_ RawField69 : 504|6@1+ (1,0) [0|0] "" ACP3_MCU
 SG_ RawField70 : 510|2@1+ (1,0) [0|0] "" ACP3_MCU

BO_ 234 CAMERA_0EA: 64 FCM
 SG_ RawField01 : 1|1@1+ (1,0) [0|0] "" ACP3_MCU
 SG_ RawField02 : 2|1@1+ (1,0) [0|0] "" ACP3_MCU
 SG_ RawField03 : 0|7@0+ (1,0) [0|0] "" ACP3_MCU
 SG_ RawField04 : 3|1@1+ (1,0) [0|0] "" ACP3_MCU
 SG_ RawField05 : 4|1@1+ (1,0) [0|0] "" ACP3_MCU
 SG_ RawField06 : 5|1@1+ (1,0) [0|0] "" ACP3_MCU
 SG_ RawField07_RollingCounter : 6|2@1+ (1,0) [0|0] "" ACP3_MCU
 SG_ RawField08 : 9|1@1+ (1,0) [0|0] "" ACP3_MCU
 SG_ RawField09 : 8|7@0+ (1,0) [0|0] "" ACP3_MCU
 SG_ RawField10 : 17|1@1+ (1,0) [0|0] "" ACP3_MCU
 SG_ RawField11 : 16|7@0+ (1,0) [0|0] "" ACP3_MCU
 SG_ RawField12 : 25|1@1+ (1,0) [0|0] "" ACP3_MCU
 SG_ RawField13 : 24|7@0+ (1,0) [0|0] "" ACP3_MCU
 SG_ RawField14 : 33|1@1+ (1,0) [0|0] "" ACP3_MCU
 SG_ RawField15 : 32|7@0+ (1,0) [0|0] "" ACP3_MCU
 SG_ RawField16 : 41|1@1+ (1,0) [0|0] "" ACP3_MCU
 SG_ RawField17 : 40|7@0+ (1,0) [0|0] "" ACP3_MCU
 SG_ RawField18 : 49|1@1+ (1,0) [0|0] "" ACP3_MCU
 SG_ RawField19 : 48|7@0+ (1,0) [0|0] "" ACP3_MCU
 SG_ RawField20 : 56|1@1+ (1,0) [0|0] "" ACP3_MCU
 SG_ RawField21 : 57|1@1+ (1,0) [0|0] "" ACP3_MCU
 SG_ RawField22 : 69|11@0+ (1,0) [0|0] "" ACP3_MCU
 SG_ RawField23 : 70|1@1+ (1,0) [0|0] "" ACP3_MCU
 SG_ RawField24 : 71|1@1+ (1,0) [0|0] "" ACP3_MCU
 SG_ RawField25_Flag : 74|1@1+ (1,0) [0|0] "" ACP3_MCU
 SG_ RawField26 : 73|6@0+ (1,0) [0|0] "" ACP3_MCU
 SG_ RawField27 : 83|10@0+ (1,0) [0|0] "" ACP3_MCU
 SG_ RawField28 : 88|2@1+ (1,0) [0|0] "" ACP3_MCU
 SG_ RawField29_Flag : 96|6@1+ (1,0) [0|0] "" ACP3_MCU
 SG_ RawField30 : 102|2@1+ (1,0) [0|0] "" ACP3_MCU
 SG_ RawField31 : 111|10@0+ (1,0) [0|0] "" ACP3_MCU
 SG_ RawField32 : 116|2@1+ (1,0) [0|0] "" ACP3_MCU
 SG_ OuterLeftLaneCandidateCurvatureRaw : 115|16@0- (1,0) [0|0] "" ACP3_MCU
 SG_ OuterLeftLaneCandidateCurvatureRateRaw : 131|16@0- (1,0) [0|0] "" ACP3_MCU
 SG_ OuterLeftLaneCandidateSupportRaw : 147|7@0+ (1,0) [0|0] "" ACP3_MCU
 SG_ RawField36 : 156|7@0+ (1,0) [0|0] "" ACP3_MCU
 SG_ RawField37 : 165|7@0+ (1,0) [0|0] "" ACP3_MCU
 SG_ RawField38 : 168|7@1+ (1,0) [0|0] "" ACP3_MCU
 SG_ OuterLeftLaneCandidateHeadingRaw : 183|10@0- (1,0) [0|0] "" ACP3_MCU
 SG_ OuterLeftLaneCandidateOffsetEstimate : 189|13@0- (0.00390625,0) [-16|15.99609375] "m" ACP3_MCU
 SG_ OuterLeftLaneCandidateRoleCandidateRaw : 192|4@0+ (1,0) [0|0] "" ACP3_MCU
 SG_ RawField42 : 200|3@1+ (1,0) [0|0] "" ACP3_MCU
 SG_ OuterLeftLaneCandidateActivityCandidateRaw : 203|2@1+ (1,0) [0|0] "" ACP3_MCU
 SG_ OuterLeftLaneCandidateRangeEndEstimate : 209|7@1+ (1,0) [0|127] "m" ACP3_MCU
 SG_ OuterLeftLaneCandidateRangeStartEstimate : 208|7@0+ (1,0) [0|127] "m" ACP3_MCU
 SG_ RawField46 : 217|6@0+ (1,0) [0|0] "" ACP3_MCU
 SG_ RawField47 : 226|2@1+ (1,0) [0|0] "" ACP3_MCU
 SG_ RawField48 : 225|3@0+ (1,0) [0|0] "" ACP3_MCU
 SG_ RawField49 : 233|6@1+ (1,0) [0|0] "" ACP3_MCU
 SG_ RawField50 : 232|6@0+ (1,0) [0|0] "" ACP3_MCU
 SG_ RawField51 : 240|9@0- (1,0) [0|0] "" ACP3_MCU
 SG_ RawField52 : 241|2@1+ (1,0) [0|0] "" ACP3_MCU
 SG_ RawField53 : 263|9@0- (1,0) [0|0] "" ACP3_MCU
 SG_ RawField54 : 270|11@0+ (1,0) [0|0] "" ACP3_MCU
 SG_ RawField55 : 275|10@0- (1,0) [0|0] "" ACP3_MCU
 SG_ RawField56 : 281|10@0- (1,0) [0|0] "" ACP3_MCU
 SG_ RawField57 : 303|9@0- (1,0) [0|0] "" ACP3_MCU
 SG_ RawField58 : 305|1@1+ (1,0) [0|0] "" ACP3_MCU
 SG_ RawField59 : 306|1@1+ (1,0) [0|0] "" ACP3_MCU
 SG_ RawField60 : 307|2@1+ (1,0) [0|0] "" ACP3_MCU
 SG_ RawField61 : 309|2@1+ (1,0) [0|0] "" ACP3_MCU
 SG_ RawField62 : 304|2@0+ (1,0) [0|0] "" ACP3_MCU
 SG_ RawField63 : 313|6@1+ (1,0) [0|0] "" ACP3_MCU
 SG_ RawField64 : 312|2@0+ (1,0) [0|0] "" ACP3_MCU
 SG_ Object0OrientationCandidateRaw : 322|11@0- (1,0) [0|0] "" ACP3_MCU
 SG_ RawField66 : 323|1@1+ (1,0) [0|0] "" ACP3_MCU
 SG_ RawField67 : 324|3@1+ (1,0) [0|0] "" ACP3_MCU
 SG_ RawField68 : 343|13@0- (1,0) [0|0] "" ACP3_MCU
 SG_ Object0IdCandidate : 346|6@0+ (1,0) [0|0] "" ACP3_MCU
 SG_ RawField70 : 352|2@1+ (1,0) [0|0] "" ACP3_MCU
 SG_ RawField71 : 354|3@1+ (1,0) [0|0] "" ACP3_MCU
 SG_ RawField72 : 367|9@0- (1,0) [0|0] "" ACP3_MCU
 SG_ RawField73 : 374|9@0- (1,0) [0|0] "" ACP3_MCU
 SG_ Object0LongitudinalEstimate : 381|11@0+ (0.125,0) [0|255.875] "m" ACP3_MCU
 SG_ RawField75 : 386|15@0+ (1,0) [0|0] "" ACP3_MCU
 SG_ Object0RelativeLongitudinalVelocityEstimate : 403|11@0- (0.125,0) [-128|127.875] "m/s" ACP3_MCU
 SG_ RawField77 : 408|10@0+ (1,0) [0|0] "" ACP3_MCU
 SG_ Object0LateralEstimate : 430|10@0- (0.125,0) [-64|63.875] "m" ACP3_MCU
 SG_ RawField79 : 436|14@0+ (1,0) [0|0] "" ACP3_MCU
 SG_ Object0RelativeLateralVelocityEstimate : 454|9@0- (0.125,0) [-32|31.875] "m/s" ACP3_MCU
 SG_ RawField81 : 461|10@0+ (1,0) [0|0] "" ACP3_MCU
 SG_ RawField82 : 467|7@0+ (1,0) [0|0] "" ACP3_MCU
 SG_ RawField83 : 472|2@1+ (1,0) [0|0] "" ACP3_MCU
 SG_ RawField84 : 474|3@1+ (1,0) [0|0] "" ACP3_MCU
 SG_ RawField85 : 483|10@0+ (1,0) [0|0] "" ACP3_MCU
 SG_ RawField86 : 484|1@1+ (1,0) [0|0] "" ACP3_MCU
 SG_ RawField87 : 485|1@1+ (1,0) [0|0] "" ACP3_MCU
 SG_ Object0StateCandidateRaw : 486|2@1+ (1,0) [0|0] "" ACP3_MCU
 SG_ RawField89 : 489|1@1+ (1,0) [0|0] "" ACP3_MCU
 SG_ RawField90 : 488|2@0+ (1,0) [0|0] "" ACP3_MCU
 SG_ RawField91 : 496|2@1+ (1,0) [0|0] "" ACP3_MCU
 SG_ RawField92 : 498|2@1+ (1,0) [0|0] "" ACP3_MCU
 SG_ RawField93 : 500|2@1+ (1,0) [0|0] "" ACP3_MCU
 SG_ RawField94 : 502|1@1+ (1,0) [0|0] "" ACP3_MCU
 SG_ RawField95 : 504|8@1+ (1,0) [0|0] "" ACP3_MCU

BO_ 235 CAMERA_0EB: 64 FCM
 SG_ RawField01 : 4|2@1+ (1,0) [0|0] "" ACP3_MCU
 SG_ RawField02 : 3|16@0- (1,0) [0|0] "" ACP3_MCU
 SG_ RawField03_RollingCounter : 6|2@1+ (1,0) [0|0] "" ACP3_MCU
 SG_ RawField04 : 19|16@0- (1,0) [0|0] "" ACP3_MCU
 SG_ RawField05 : 35|7@0+ (1,0) [0|0] "" ACP3_MCU
 SG_ RawField06 : 44|7@0+ (1,0) [0|0] "" ACP3_MCU
 SG_ RawField07 : 53|7@0+ (1,0) [0|0] "" ACP3_MCU
 SG_ RawField08 : 56|7@1+ (1,0) [0|0] "" ACP3_MCU
 SG_ RawField09 : 71|10@0- (1,0) [0|0] "" ACP3_MCU
 SG_ RawField10 : 77|13@0- (1,0) [0|0] "" ACP3_MCU
 SG_ RawField11 : 80|4@0+ (1,0) [0|0] "" ACP3_MCU
 SG_ RawField12 : 88|3@1+ (1,0) [0|0] "" ACP3_MCU
 SG_ RawField13 : 91|2@1+ (1,0) [0|0] "" ACP3_MCU
 SG_ RawField14 : 97|7@1+ (1,0) [0|0] "" ACP3_MCU
 SG_ RawField15 : 96|7@0+ (1,0) [0|0] "" ACP3_MCU
 SG_ RawField16 : 105|6@0+ (1,0) [0|0] "" ACP3_MCU
 SG_ RawField17 : 114|2@1+ (1,0) [0|0] "" ACP3_MCU
 SG_ RawField18 : 113|16@0- (1,0) [0|0] "" ACP3_MCU
 SG_ RawField19 : 129|16@0- (1,0) [0|0] "" ACP3_MCU
 SG_ RawField20 : 145|7@0+ (1,0) [0|0] "" ACP3_MCU
 SG_ RawField21 : 154|7@0+ (1,0) [0|0] "" ACP3_MCU
 SG_ RawField22 : 163|7@0+ (1,0) [0|0] "" ACP3_MCU
 SG_ RawField23 : 172|7@0+ (1,0) [0|0] "" ACP3_MCU
 SG_ RawField24 : 181|10@0- (1,0) [0|0] "" ACP3_MCU
 SG_ LeftSecondaryBoundaryCandidateOffsetEstimate : 187|13@0- (0.00390625,0) [-16|15.99609375] "m" ACP3_MCU
 SG_ LeftSecondaryBoundaryCandidateActivityCandidateRaw : 201|2@1+ (1,0) [0|0] "" ACP3_MCU
 SG_ LeftSecondaryBoundaryCandidateRoleCandidateRaw : 203|4@1+ (1,0) [0|0] "" ACP3_MCU
 SG_ RawField28 : 200|3@0+ (1,0) [0|0] "" ACP3_MCU
 SG_ LeftSecondaryBoundaryCandidateRangeEndEstimate : 213|7@0+ (1,0) [0|127] "m" ACP3_MCU
 SG_ LeftSecondaryBoundaryCandidateRangeStartEstimate : 216|7@1+ (1,0) [0|127] "m" ACP3_MCU
 SG_ RawField31 : 224|2@1+ (1,0) [0|0] "" ACP3_MCU
 SG_ RawField32 : 226|6@1+ (1,0) [0|0] "" ACP3_MCU
 SG_ RawField33 : 237|3@1+ (1,0) [0|0] "" ACP3_MCU
 SG_ RawField34 : 236|6@0+ (1,0) [0|0] "" ACP3_MCU
 SG_ RawField35 : 241|6@1+ (1,0) [0|0] "" ACP3_MCU
 SG_ RawField36 : 240|2@0+ (1,0) [0|0] "" ACP3_MCU
 SG_ RawField37 : 254|9@0- (1,0) [0|0] "" ACP3_MCU
 SG_ RawField38 : 261|9@0- (1,0) [0|0] "" ACP3_MCU
 SG_ RawField39 : 268|11@0+ (1,0) [0|0] "" ACP3_MCU
 SG_ RawField40 : 273|10@0- (1,0) [0|0] "" ACP3_MCU
 SG_ RawField41 : 295|10@0- (1,0) [0|0] "" ACP3_MCU
 SG_ RawField42 : 301|9@0- (1,0) [0|0] "" ACP3_MCU
 SG_ RawField43 : 305|2@1+ (1,0) [0|0] "" ACP3_MCU
 SG_ RawField44 : 307|2@1+ (1,0) [0|0] "" ACP3_MCU
 SG_ RawField45 : 304|2@0+ (1,0) [0|0] "" ACP3_MCU
 SG_ RawField46 : 313|6@1+ (1,0) [0|0] "" ACP3_MCU
 SG_ RawField47 : 312|2@0+ (1,0) [0|0] "" ACP3_MCU
 SG_ Object0OrientationCandidateRaw : 322|11@0- (1,0) [0|0] "" ACP3_MCU
 SG_ RawField49 : 323|1@1+ (1,0) [0|0] "" ACP3_MCU
 SG_ RawField50 : 324|3@1+ (1,0) [0|0] "" ACP3_MCU
 SG_ RawField51 : 343|13@0- (1,0) [0|0] "" ACP3_MCU
 SG_ Object0IdCandidate : 346|6@0+ (1,0) [0|0] "" ACP3_MCU
 SG_ RawField53 : 352|2@1+ (1,0) [0|0] "" ACP3_MCU
 SG_ RawField54 : 354|3@1+ (1,0) [0|0] "" ACP3_MCU
 SG_ RawField55 : 367|9@0- (1,0) [0|0] "" ACP3_MCU
 SG_ RawField56 : 374|9@0- (1,0) [0|0] "" ACP3_MCU
 SG_ Object0LongitudinalEstimate : 381|11@0+ (0.125,0) [0|255.875] "m" ACP3_MCU
 SG_ RawField58 : 386|15@0+ (1,0) [0|0] "" ACP3_MCU
 SG_ Object0RelativeLongitudinalVelocityEstimate : 403|11@0- (0.125,0) [-128|127.875] "m/s" ACP3_MCU
 SG_ RawField60 : 408|10@0+ (1,0) [0|0] "" ACP3_MCU
 SG_ Object0LateralEstimate : 430|10@0- (0.125,0) [-64|63.875] "m" ACP3_MCU
 SG_ RawField62 : 436|14@0+ (1,0) [0|0] "" ACP3_MCU
 SG_ Object0RelativeLateralVelocityEstimate : 454|9@0- (0.125,0) [-32|31.875] "m/s" ACP3_MCU
 SG_ RawField64 : 461|10@0+ (1,0) [0|0] "" ACP3_MCU
 SG_ RawField65 : 467|7@0+ (1,0) [0|0] "" ACP3_MCU
 SG_ RawField66 : 472|2@1+ (1,0) [0|0] "" ACP3_MCU
 SG_ RawField67 : 474|3@1+ (1,0) [0|0] "" ACP3_MCU
 SG_ RawField68 : 480|2@1+ (1,0) [0|0] "" ACP3_MCU
 SG_ RawField69 : 482|2@1+ (1,0) [0|0] "" ACP3_MCU
 SG_ RawField70 : 484|2@1+ (1,0) [0|0] "" ACP3_MCU
 SG_ Object0StateCandidateRaw : 486|2@1+ (1,0) [0|0] "" ACP3_MCU
 SG_ RawField72 : 495|24@0+ (1,0) [0|0] "" ACP3_MCU

BO_ 236 CAMERA_0EC: 64 FCM
 SG_ RawField01 : 4|2@1+ (1,0) [0|0] "" ACP3_MCU
 SG_ LeftRoadEdgeCandidateCurvatureRaw : 3|16@0- (1,0) [0|0] "" ACP3_MCU
 SG_ RawField03_RollingCounter : 6|2@1+ (1,0) [0|0] "" ACP3_MCU
 SG_ LeftRoadEdgeCandidateCurvatureRateRaw : 19|16@0- (1,0) [0|0] "" ACP3_MCU
 SG_ RawField05 : 35|7@0+ (1,0) [0|0] "" ACP3_MCU
 SG_ RawField06 : 44|7@0+ (1,0) [0|0] "" ACP3_MCU
 SG_ RawField07 : 53|7@0+ (1,0) [0|0] "" ACP3_MCU
 SG_ RawField08 : 56|7@1+ (1,0) [0|0] "" ACP3_MCU
 SG_ LeftRoadEdgeCandidateHeadingRaw : 71|10@0- (1,0) [0|0] "" ACP3_MCU
 SG_ LeftRoadEdgeCandidateOffsetEstimate : 77|13@0- (0.00390625,0) [-16|15.99609375] "m" ACP3_MCU
 SG_ LeftRoadEdgeCandidateRoleCandidateRaw : 80|4@0+ (1,0) [0|0] "" ACP3_MCU
 SG_ RawField12 : 88|3@1+ (1,0) [0|0] "" ACP3_MCU
 SG_ LeftRoadEdgeCandidateActivityCandidateRaw : 91|2@1+ (1,0) [0|0] "" ACP3_MCU
 SG_ LeftRoadEdgeCandidateRangeEndEstimate : 97|7@1+ (1,0) [0|127] "m" ACP3_MCU
 SG_ LeftRoadEdgeCandidateRangeStartEstimate : 96|7@0+ (1,0) [0|127] "m" ACP3_MCU
 SG_ RawField16 : 105|6@0+ (1,0) [0|0] "" ACP3_MCU
 SG_ RawField17 : 114|2@1+ (1,0) [0|0] "" ACP3_MCU
 SG_ RawField18 : 113|16@0- (1,0) [0|0] "" ACP3_MCU
 SG_ RawField19 : 129|16@0- (1,0) [0|0] "" ACP3_MCU
 SG_ RawField20 : 145|7@0+ (1,0) [0|0] "" ACP3_MCU
 SG_ RawField21 : 154|7@0+ (1,0) [0|0] "" ACP3_MCU
 SG_ RawField22 : 163|7@0+ (1,0) [0|0] "" ACP3_MCU
 SG_ RawField23 : 172|7@0+ (1,0) [0|0] "" ACP3_MCU
 SG_ RawField24 : 181|10@0- (1,0) [0|0] "" ACP3_MCU
 SG_ RawField25 : 187|13@0- (1,0) [0|0] "" ACP3_MCU
 SG_ RawField26 : 201|2@1+ (1,0) [0|0] "" ACP3_MCU
 SG_ RawField27 : 203|4@1+ (1,0) [0|0] "" ACP3_MCU
 SG_ RawField28 : 200|3@0+ (1,0) [0|0] "" ACP3_MCU
 SG_ RawField29 : 213|7@0+ (1,0) [0|0] "" ACP3_MCU
 SG_ RawField30 : 216|7@1+ (1,0) [0|0] "" ACP3_MCU
 SG_ RawField31 : 224|2@1+ (1,0) [0|0] "" ACP3_MCU
 SG_ RawField32 : 226|6@1+ (1,0) [0|0] "" ACP3_MCU
 SG_ RawField33 : 232|2@1+ (1,0) [0|0] "" ACP3_MCU
 SG_ RawField34 : 234|6@1+ (1,0) [0|0] "" ACP3_MCU
 SG_ Object0OrientationCandidateRaw : 243|11@0- (1,0) [0|0] "" ACP3_MCU
 SG_ RawField36 : 244|1@1+ (1,0) [0|0] "" ACP3_MCU
 SG_ RawField37 : 245|3@1+ (1,0) [0|0] "" ACP3_MCU
 SG_ RawField38 : 248|13@0- (1,0) [0|0] "" ACP3_MCU
 SG_ Object0IdCandidate : 267|6@0+ (1,0) [0|0] "" ACP3_MCU
 SG_ RawField40 : 272|9@0- (1,0) [0|0] "" ACP3_MCU
 SG_ RawField41 : 273|2@1+ (1,0) [0|0] "" ACP3_MCU
 SG_ RawField42 : 275|3@1+ (1,0) [0|0] "" ACP3_MCU
 SG_ RawField43 : 295|9@0- (1,0) [0|0] "" ACP3_MCU
 SG_ Object0LongitudinalEstimate : 302|11@0+ (0.125,0) [0|255.875] "m" ACP3_MCU
 SG_ RawField45 : 307|15@0+ (1,0) [0|0] "" ACP3_MCU
 SG_ Object0RelativeLongitudinalVelocityEstimate : 324|11@0- (0.125,0) [-128|127.875] "m/s" ACP3_MCU
 SG_ RawField47 : 329|10@0+ (1,0) [0|0] "" ACP3_MCU
 SG_ Object0LateralEstimate : 351|10@0- (0.125,0) [-64|63.875] "m" ACP3_MCU
 SG_ RawField49 : 357|14@0+ (1,0) [0|0] "" ACP3_MCU
 SG_ Object0RelativeLateralVelocityEstimate : 375|9@0- (0.125,0) [-32|31.875] "m/s" ACP3_MCU
 SG_ RawField51 : 382|10@0+ (1,0) [0|0] "" ACP3_MCU
 SG_ RawField52 : 388|7@0+ (1,0) [0|0] "" ACP3_MCU
 SG_ RawField53 : 393|2@1+ (1,0) [0|0] "" ACP3_MCU
 SG_ RawField54 : 395|3@1+ (1,0) [0|0] "" ACP3_MCU
 SG_ Object0StateCandidateRaw : 392|2@0+ (1,0) [0|0] "" ACP3_MCU
 SG_ RawField56 : 403|2@1+ (1,0) [0|0] "" ACP3_MCU
 SG_ RawField57 : 405|2@1+ (1,0) [0|0] "" ACP3_MCU
 SG_ RawField58 : 402|28@0+ (1,0) [0|0] "" ACP3_MCU
 SG_ RawField59 : 438|32@0+ (1,0) [0|0] "" ACP3_MCU
 SG_ RawField60 : 470|32@0+ (1,0) [0|0] "" ACP3_MCU
 SG_ RawField61 : 502|15@0+ (1,0) [0|0] "" ACP3_MCU

BO_ 237 CAMERA_0ED: 48 FCM
 SG_ RawField01 : 0|1@1+ (1,0) [0|0] "" ACP3_MCU
 SG_ RawField02_Flag : 1|1@1+ (1,0) [0|0] "" ACP3_MCU
 SG_ RawField03 : 2|1@1+ (1,0) [0|0] "" ACP3_MCU
 SG_ RawField04 : 3|1@1+ (1,0) [0|0] "" ACP3_MCU
 SG_ RawField05 : 4|1@1+ (1,0) [0|0] "" ACP3_MCU
 SG_ RawField06 : 5|1@1+ (1,0) [0|0] "" ACP3_MCU
 SG_ RawField07_RollingCounter : 6|2@1+ (1,0) [0|0] "" ACP3_MCU
 SG_ RawField08 : 12|1@1+ (1,0) [0|0] "" ACP3_MCU
 SG_ RawField09 : 13|1@1+ (1,0) [0|0] "" ACP3_MCU
 SG_ RawField10 : 11|7@0+ (1,0) [0|0] "" ACP3_MCU
 SG_ RawField11 : 14|1@1+ (1,0) [0|0] "" ACP3_MCU
 SG_ RawField12 : 15|1@1+ (1,0) [0|0] "" ACP3_MCU
 SG_ RawField13 : 20|7@0+ (1,0) [0|0] "" ACP3_MCU
 SG_ RawField14 : 29|7@0+ (1,0) [0|0] "" ACP3_MCU
 SG_ RawField15 : 32|7@1+ (1,0) [0|0] "" ACP3_MCU
 SG_ RawField16 : 41|7@1+ (1,0) [0|0] "" ACP3_MCU
 SG_ LeftBoundaryCandidateCurvatureRaw : 40|16@0- (1,0) [0|0] "" ACP3_MCU
 SG_ LeftBoundaryCandidateCurvatureRateRaw : 56|16@0- (1,0) [0|0] "" ACP3_MCU
 SG_ LeftBoundaryCandidateHeadingRaw : 72|10@0- (1,0) [0|0] "" ACP3_MCU
 SG_ LeftBoundaryCandidateOffsetEstimate : 94|12@0- (0.00390625,0) [-8|7.99609375] "m" ACP3_MCU
 SG_ LeftBoundaryCandidateSupportRaw : 98|7@0+ (1,0) [0|0] "" ACP3_MCU
 SG_ LeftBoundaryCandidateExtentRaw : 107|7@0+ (1,0) [0|0] "" ACP3_MCU
 SG_ RawField23 : 116|7@0+ (1,0) [0|0] "" ACP3_MCU
 SG_ RawField24_Flag : 124|2@1+ (1,0) [0|0] "" ACP3_MCU
 SG_ RightBoundaryCandidateCurvatureRaw : 123|16@0- (1,0) [0|0] "" ACP3_MCU
 SG_ RightBoundaryCandidateCurvatureRateRaw : 139|16@0- (1,0) [0|0] "" ACP3_MCU
 SG_ RightBoundaryCandidateHeadingRaw : 155|10@0- (1,0) [0|0] "" ACP3_MCU
 SG_ RightBoundaryCandidateOffsetEstimate : 161|12@0- (0.00390625,0) [-8|7.99609375] "m" ACP3_MCU
 SG_ RightBoundaryCandidateSupportRaw : 181|7@0+ (1,0) [0|0] "" ACP3_MCU
 SG_ RightBoundaryCandidateExtentRaw : 184|7@1+ (1,0) [0|0] "" ACP3_MCU
 SG_ RawField31 : 193|7@1+ (1,0) [0|0] "" ACP3_MCU
 SG_ RawField32 : 192|2@0+ (1,0) [0|0] "" ACP3_MCU
 SG_ CenterCandidateCurvatureRaw : 206|16@0- (1,0) [0|0] "" ACP3_MCU
 SG_ CenterCandidateCurvatureRateRaw : 222|16@0- (1,0) [0|0] "" ACP3_MCU
 SG_ CenterCandidateHeadingRaw : 238|10@0- (1,0) [0|0] "" ACP3_MCU
 SG_ CenterCandidateOffsetEstimate : 244|12@0- (0.00390625,0) [-8|7.99609375] "m" ACP3_MCU
 SG_ CenterCandidateSupportRaw : 248|7@0+ (1,0) [0|0] "" ACP3_MCU
 SG_ CenterCandidateExtentRaw : 257|7@0+ (1,0) [0|0] "" ACP3_MCU
 SG_ RawField39 : 266|7@0+ (1,0) [0|0] "" ACP3_MCU
 SG_ RawField40 : 274|2@1+ (1,0) [0|0] "" ACP3_MCU
 SG_ CenterCopyCandidateCurvatureRaw : 273|16@0- (1,0) [0|0] "" ACP3_MCU
 SG_ CenterCopyCandidateCurvatureRateRaw : 289|16@0- (1,0) [0|0] "" ACP3_MCU
 SG_ CenterCopyCandidateHeadingRaw : 305|10@0- (1,0) [0|0] "" ACP3_MCU
 SG_ CenterCopyCandidateOffsetEstimate : 327|12@0- (0.00390625,0) [-8|7.99609375] "m" ACP3_MCU
 SG_ CenterCopyCandidateSupportRaw : 331|7@0+ (1,0) [0|0] "" ACP3_MCU
 SG_ CenterCopyCandidateExtentRaw : 340|7@0+ (1,0) [0|0] "" ACP3_MCU
 SG_ RawField47 : 349|7@0+ (1,0) [0|0] "" ACP3_MCU
 SG_ RawField48 : 352|1@1+ (1,0) [0|0] "" ACP3_MCU
 SG_ RawField49 : 353|1@1+ (1,0) [0|0] "" ACP3_MCU
 SG_ RawField50 : 354|1@1+ (1,0) [0|0] "" ACP3_MCU
 SG_ RawField51 : 355|1@1+ (1,0) [0|0] "" ACP3_MCU
 SG_ RawField52 : 356|1@1+ (1,0) [0|0] "" ACP3_MCU
 SG_ RawField53 : 357|2@1+ (1,0) [0|0] "" ACP3_MCU
 SG_ RawField54 : 360|17@0+ (1,0) [0|0] "" ACP3_MCU
 SG_ RawField55 : 361|2@1+ (1,0) [0|0] "" ACP3_MCU
 SG_ RawField56 : 363|2@1+ (1,0) [0|0] "" ACP3_MCU
 SG_ RawField57 : 365|1@1+ (1,0) [0|0] "" ACP3_MCU
 SG_ RawField58 : 366|1@1+ (1,0) [0|0] "" ACP3_MCU
 SG_ RawField59 : 367|1@1+ (1,0) [0|0] "" ACP3_MCU

BO_ 238 CAMERA_0EE: 64 FCM
 SG_ RawField01 : 5|11@0+ (1,0) [0|0] "" ACP3_MCU
 SG_ RawField02_RollingCounter : 6|2@1+ (1,0) [0|0] "" ACP3_MCU
 SG_ RawField03 : 10|10@0+ (1,0) [0|0] "" ACP3_MCU
 SG_ RawField04 : 16|2@0+ (1,0) [0|0] "" ACP3_MCU
 SG_ RawField05 : 30|11@0+ (1,0) [0|0] "" ACP3_MCU
 SG_ RawField06 : 35|10@0+ (1,0) [0|0] "" ACP3_MCU
 SG_ RawField07 : 40|2@1+ (1,0) [0|0] "" ACP3_MCU
 SG_ RawField08 : 55|11@0+ (1,0) [0|0] "" ACP3_MCU
 SG_ RawField09 : 60|10@0+ (1,0) [0|0] "" ACP3_MCU
 SG_ RawField10 : 65|2@1+ (1,0) [0|0] "" ACP3_MCU
 SG_ RawField11 : 64|11@0+ (1,0) [0|0] "" ACP3_MCU
 SG_ RawField12 : 85|10@0+ (1,0) [0|0] "" ACP3_MCU
 SG_ RawField13 : 90|2@1+ (1,0) [0|0] "" ACP3_MCU
 SG_ RawField14 : 89|11@0+ (1,0) [0|0] "" ACP3_MCU
 SG_ RawField15 : 110|10@0+ (1,0) [0|0] "" ACP3_MCU
 SG_ RawField16 : 114|11@0+ (1,0) [0|0] "" ACP3_MCU
 SG_ RawField17 : 115|2@1+ (1,0) [0|0] "" ACP3_MCU
 SG_ RawField18 : 135|10@0+ (1,0) [0|0] "" ACP3_MCU
 SG_ RawField19 : 139|11@0+ (1,0) [0|0] "" ACP3_MCU
 SG_ RawField20 : 140|2@1+ (1,0) [0|0] "" ACP3_MCU
 SG_ RawField21 : 144|10@0+ (1,0) [0|0] "" ACP3_MCU
 SG_ RawField22 : 164|11@0+ (1,0) [0|0] "" ACP3_MCU
 SG_ RawField23 : 165|2@1+ (1,0) [0|0] "" ACP3_MCU
 SG_ RawField24 : 169|10@0+ (1,0) [0|0] "" ACP3_MCU
 SG_ RawField25 : 189|11@0+ (1,0) [0|0] "" ACP3_MCU
 SG_ RawField26 : 190|2@1+ (1,0) [0|0] "" ACP3_MCU
 SG_ RawField27 : 194|10@0+ (1,0) [0|0] "" ACP3_MCU
 SG_ RawField28 : 200|2@0+ (1,0) [0|0] "" ACP3_MCU
 SG_ RawField29 : 214|11@0+ (1,0) [0|0] "" ACP3_MCU
 SG_ RawField30 : 219|10@0+ (1,0) [0|0] "" ACP3_MCU
 SG_ RawField31 : 224|2@1+ (1,0) [0|0] "" ACP3_MCU
 SG_ RawField32 : 239|12@0- (1,0) [0|0] "" ACP3_MCU
 SG_ RawField33 : 243|14@0- (1,0) [0|0] "" ACP3_MCU
 SG_ RawField34 : 259|12@0+ (1,0) [0|0] "" ACP3_MCU
 SG_ RawField35 : 260|2@1+ (1,0) [0|0] "" ACP3_MCU
 SG_ RawField36 : 279|14@0+ (1,0) [0|0] "" ACP3_MCU
 SG_ RawField37 : 280|2@1+ (1,0) [0|0] "" ACP3_MCU
 SG_ RawField38 : 292|10@0+ (1,0) [0|0] "" ACP3_MCU
 SG_ RawField39_Flag : 293|1@1+ (1,0) [0|0] "" ACP3_MCU
 SG_ RawField40 : 294|2@1+ (1,0) [0|0] "" ACP3_MCU
 SG_ RawField41 : 298|10@0+ (1,0) [0|0] "" ACP3_MCU
 SG_ RawField42 : 304|10@0+ (1,0) [0|0] "" ACP3_MCU
 SG_ RawField43 : 326|10@0+ (1,0) [0|0] "" ACP3_MCU
 SG_ RawField44 : 332|10@0+ (1,0) [0|0] "" ACP3_MCU
 SG_ RawField45 : 338|10@0+ (1,0) [0|0] "" ACP3_MCU
 SG_ RawField46 : 344|10@0+ (1,0) [0|0] "" ACP3_MCU
 SG_ RawField47 : 366|10@0+ (1,0) [0|0] "" ACP3_MCU
 SG_ RawField48 : 372|10@0+ (1,0) [0|0] "" ACP3_MCU
 SG_ RawField49 : 378|10@0+ (1,0) [0|0] "" ACP3_MCU
 SG_ RawField50 : 384|10@0+ (1,0) [0|0] "" ACP3_MCU
 SG_ RawField51 : 406|10@0+ (1,0) [0|0] "" ACP3_MCU
 SG_ RawField52 : 412|10@0+ (1,0) [0|0] "" ACP3_MCU
 SG_ RawField53 : 418|10@0+ (1,0) [0|0] "" ACP3_MCU
 SG_ RawField54 : 424|10@0+ (1,0) [0|0] "" ACP3_MCU
 SG_ RawField55 : 441|2@1+ (1,0) [0|0] "" ACP3_MCU
 SG_ RawField56 : 440|30@0+ (1,0) [0|0] "" ACP3_MCU
 SG_ RawField57 : 443|2@1+ (1,0) [0|0] "" ACP3_MCU
 SG_ RawField58 : 445|2@1+ (1,0) [0|0] "" ACP3_MCU
 SG_ RawField59 : 474|32@0+ (1,0) [0|0] "" ACP3_MCU
 SG_ RawField60 : 504|3@1+ (1,0) [0|0] "" ACP3_MCU

BO_ 239 CAMERA_0EF: 64 FCM
 SG_ RawField01_RollingCounter : 6|2@1+ (1,0) [0|0] "" ACP3_MCU
 SG_ RawField02 : 5|8@0+ (1,0) [0|0] "" ACP3_MCU
 SG_ RawField03 : 8|1@1+ (1,0) [0|0] "" ACP3_MCU
 SG_ RawField04 : 9|2@1+ (1,0) [0|0] "" ACP3_MCU
 SG_ RawField05 : 11|1@1+ (1,0) [0|0] "" ACP3_MCU
 SG_ RawField06 : 12|2@1+ (1,0) [0|0] "" ACP3_MCU
 SG_ RawField07 : 22|8@0+ (1,0) [0|0] "" ACP3_MCU
 SG_ RawField08 : 23|1@1+ (1,0) [0|0] "" ACP3_MCU
 SG_ RawField09 : 24|1@1+ (1,0) [0|0] "" ACP3_MCU
 SG_ RawField10 : 25|1@1+ (1,0) [0|0] "" ACP3_MCU
 SG_ RawField11 : 26|2@1+ (1,0) [0|0] "" ACP3_MCU
 SG_ RawField12 : 28|1@1+ (1,0) [0|0] "" ACP3_MCU
 SG_ RawField13 : 29|2@1+ (1,0) [0|0] "" ACP3_MCU
 SG_ RawField14 : 32|8@1+ (1,0) [0|0] "" ACP3_MCU
 SG_ RawField15 : 41|1@1+ (1,0) [0|0] "" ACP3_MCU
 SG_ RawField16 : 40|8@0+ (1,0) [0|0] "" ACP3_MCU
 SG_ RawField17 : 42|1@1+ (1,0) [0|0] "" ACP3_MCU
 SG_ RawField18 : 43|2@1+ (1,0) [0|0] "" ACP3_MCU
 SG_ RawField19 : 45|1@1+ (1,0) [0|0] "" ACP3_MCU
 SG_ RawField20 : 46|2@1+ (1,0) [0|0] "" ACP3_MCU
 SG_ RawField21 : 48|2@0+ (1,0) [0|0] "" ACP3_MCU
 SG_ RawField22 : 56|2@1+ (1,0) [0|0] "" ACP3_MCU
 SG_ RawField23 : 58|1@1+ (1,0) [0|0] "" ACP3_MCU
 SG_ RawField24 : 59|1@1+ (1,0) [0|0] "" ACP3_MCU
 SG_ RawField25 : 60|2@1+ (1,0) [0|0] "" ACP3_MCU
 SG_ RawField26 : 62|1@1+ (1,0) [0|0] "" ACP3_MCU
 SG_ RawField27 : 65|9@0- (1,0) [0|0] "" ACP3_MCU
 SG_ RawField28 : 66|6@1+ (1,0) [0|0] "" ACP3_MCU
 SG_ RawField29 : 72|11@0- (1,0) [0|0] "" ACP3_MCU
 SG_ RawField30 : 92|2@1+ (1,0) [0|0] "" ACP3_MCU
 SG_ RawField31 : 91|6@0+ (1,0) [0|0] "" ACP3_MCU
 SG_ RawField32 : 101|7@0+ (1,0) [0|0] "" ACP3_MCU
 SG_ RawField33 : 109|2@1+ (1,0) [0|0] "" ACP3_MCU
 SG_ RawField34 : 108|8@0+ (1,0) [0|0] "" ACP3_MCU
 SG_ RawField35 : 115|2@1+ (1,0) [0|0] "" ACP3_MCU
 SG_ RawField36 : 114|6@0+ (1,0) [0|0] "" ACP3_MCU
 SG_ RawField37 : 124|9@0- (1,0) [0|0] "" ACP3_MCU
 SG_ RawField38 : 131|11@0- (1,0) [0|0] "" ACP3_MCU
 SG_ RawField39 : 136|2@0+ (1,0) [0|0] "" ACP3_MCU
 SG_ RawField40 : 145|6@1+ (1,0) [0|0] "" ACP3_MCU
 SG_ RawField41 : 144|7@0+ (1,0) [0|0] "" ACP3_MCU
 SG_ RawField42 : 152|2@1+ (1,0) [0|0] "" ACP3_MCU
 SG_ RawField43 : 160|8@1+ (1,0) [0|0] "" ACP3_MCU
 SG_ RawField44 : 168|6@1+ (1,0) [0|0] "" ACP3_MCU
 SG_ RawField45 : 174|2@1+ (1,0) [0|0] "" ACP3_MCU
 SG_ RawField46 : 183|9@0- (1,0) [0|0] "" ACP3_MCU
 SG_ RawField47 : 190|11@0- (1,0) [0|0] "" ACP3_MCU
 SG_ RawField48 : 194|2@1+ (1,0) [0|0] "" ACP3_MCU
 SG_ RawField49 : 193|6@0+ (1,0) [0|0] "" ACP3_MCU
 SG_ RawField50 : 203|7@0+ (1,0) [0|0] "" ACP3_MCU
 SG_ RawField51 : 211|2@1+ (1,0) [0|0] "" ACP3_MCU
 SG_ RawField52 : 210|8@0+ (1,0) [0|0] "" ACP3_MCU
 SG_ RawField53 : 217|2@1+ (1,0) [0|0] "" ACP3_MCU
 SG_ RawField54 : 216|6@0+ (1,0) [0|0] "" ACP3_MCU
 SG_ RawField55 : 226|9@0- (1,0) [0|0] "" ACP3_MCU
 SG_ RawField56 : 233|11@0- (1,0) [0|0] "" ACP3_MCU
 SG_ RawField57 : 253|2@1+ (1,0) [0|0] "" ACP3_MCU
 SG_ RawField58 : 252|6@0+ (1,0) [0|0] "" ACP3_MCU
 SG_ RawField59 : 256|7@1+ (1,0) [0|0] "" ACP3_MCU
 SG_ RawField60 : 270|2@1+ (1,0) [0|0] "" ACP3_MCU
 SG_ RawField61 : 269|8@0+ (1,0) [0|0] "" ACP3_MCU
 SG_ RawField62 : 276|2@1+ (1,0) [0|0] "" ACP3_MCU
 SG_ RawField63 : 275|6@0+ (1,0) [0|0] "" ACP3_MCU
 SG_ RawField64 : 285|9@0- (1,0) [0|0] "" ACP3_MCU
 SG_ RawField65 : 292|11@0- (1,0) [0|0] "" ACP3_MCU
 SG_ RawField66 : 296|2@1+ (1,0) [0|0] "" ACP3_MCU
 SG_ RawField67 : 306|6@1+ (1,0) [0|0] "" ACP3_MCU
 SG_ RawField68 : 305|7@0+ (1,0) [0|0] "" ACP3_MCU
 SG_ RawField69 : 313|2@1+ (1,0) [0|0] "" ACP3_MCU
 SG_ RawField70 : 312|8@0+ (1,0) [0|0] "" ACP3_MCU
 SG_ RawField71 : 320|2@0+ (1,0) [0|0] "" ACP3_MCU
 SG_ RawField72 : 328|9@0- (1,0) [0|0] "" ACP3_MCU
 SG_ RawField73 : 329|6@1+ (1,0) [0|0] "" ACP3_MCU
 SG_ RawField74 : 351|11@0- (1,0) [0|0] "" ACP3_MCU
 SG_ RawField75 : 355|2@1+ (1,0) [0|0] "" ACP3_MCU
 SG_ RawField76 : 354|6@0+ (1,0) [0|0] "" ACP3_MCU
 SG_ RawField77 : 364|7@0+ (1,0) [0|0] "" ACP3_MCU
 SG_ RawField78 : 372|2@1+ (1,0) [0|0] "" ACP3_MCU
 SG_ RawField79 : 371|8@0+ (1,0) [0|0] "" ACP3_MCU
 SG_ RawField80 : 378|2@1+ (1,0) [0|0] "" ACP3_MCU
 SG_ RawField81 : 377|6@0+ (1,0) [0|0] "" ACP3_MCU
 SG_ RawField82 : 387|9@0- (1,0) [0|0] "" ACP3_MCU
 SG_ RawField83 : 394|11@0- (1,0) [0|0] "" ACP3_MCU
 SG_ RawField84 : 408|6@1+ (1,0) [0|0] "" ACP3_MCU
 SG_ RawField85 : 414|2@1+ (1,0) [0|0] "" ACP3_MCU
 SG_ RawField86 : 417|7@1+ (1,0) [0|0] "" ACP3_MCU
 SG_ RawField87 : 416|2@0+ (1,0) [0|0] "" ACP3_MCU
 SG_ RawField88 : 430|8@0+ (1,0) [0|0] "" ACP3_MCU
 SG_ RawField89 : 437|2@1+ (1,0) [0|0] "" ACP3_MCU
 SG_ RawField90 : 436|6@0+ (1,0) [0|0] "" ACP3_MCU
 SG_ RawField91 : 446|9@0- (1,0) [0|0] "" ACP3_MCU
 SG_ RawField92 : 453|11@0- (1,0) [0|0] "" ACP3_MCU
 SG_ RawField93 : 457|2@1+ (1,0) [0|0] "" ACP3_MCU
 SG_ RawField94 : 456|6@0+ (1,0) [0|0] "" ACP3_MCU
 SG_ RawField95 : 466|7@0+ (1,0) [0|0] "" ACP3_MCU
 SG_ RawField96 : 474|2@1+ (1,0) [0|0] "" ACP3_MCU
 SG_ RawField97 : 473|8@0+ (1,0) [0|0] "" ACP3_MCU
 SG_ RawField98 : 481|26@0+ (1,0) [0|0] "" ACP3_MCU

BO_ 240 CAMERA_0F0: 20 FCM
 SG_ RawField01 : 5|10@0+ (1,0) [0|0] "" ACP3_MCU
 SG_ RawField02_RollingCounter : 6|2@1+ (1,0) [0|0] "" ACP3_MCU
 SG_ RawField03 : 11|10@0+ (1,0) [0|0] "" ACP3_MCU
 SG_ RawField04 : 17|10@0+ (1,0) [0|0] "" ACP3_MCU
 SG_ RawField05 : 39|10@0+ (1,0) [0|0] "" ACP3_MCU
 SG_ RawField06 : 45|10@0+ (1,0) [0|0] "" ACP3_MCU
 SG_ RawField07 : 51|10@0+ (1,0) [0|0] "" ACP3_MCU
 SG_ RawField08 : 57|10@0+ (1,0) [0|0] "" ACP3_MCU
 SG_ RawField09 : 79|10@0+ (1,0) [0|0] "" ACP3_MCU
 SG_ RawField10 : 85|10@0+ (1,0) [0|0] "" ACP3_MCU
 SG_ RawField11 : 91|10@0+ (1,0) [0|0] "" ACP3_MCU
 SG_ RawField12 : 97|10@0+ (1,0) [0|0] "" ACP3_MCU
 SG_ RawField13 : 119|10@0+ (1,0) [0|0] "" ACP3_MCU
 SG_ RawField14 : 125|10@0+ (1,0) [0|0] "" ACP3_MCU
 SG_ RawField15 : 131|10@0+ (1,0) [0|0] "" ACP3_MCU
 SG_ RawField16 : 137|10@0+ (1,0) [0|0] "" ACP3_MCU
 SG_ RawField17 : 152|8@1+ (1,0) [0|0] "" ACP3_MCU

BO_ 244 LFR_OBJECT_PAGE0_0F4: 64 LFR
 SG_ CycleCounter : 6|2@1+ (1,0) [0|3] "" ACP3_MCU
 SG_ Object1TrackId : 102|6@0+ (1,0) [0|63] "" ACP3_MCU
 SG_ Object2TrackId : 226|6@0+ (1,0) [0|63] "" ACP3_MCU
 SG_ Object3TrackId : 374|6@0+ (1,0) [0|63] "" ACP3_MCU
 SG_ Object1RelativeLongitudinalVelocityRaw : 145|11@0- (1,0) [-1024|1023] "" ACP3_MCU
 SG_ Object1RelativeLateralVelocityCandidateRaw : 110|9@0- (1,0) [-256|255] "" ACP3_MCU
 SG_ Object2RelativeLongitudinalVelocityRaw : 293|11@0- (1,0) [-1024|1023] "" ACP3_MCU
 SG_ Object2RelativeLateralVelocityCandidateRaw : 234|9@0- (1,0) [-256|255] "" ACP3_MCU
 SG_ Object3RelativeLongitudinalVelocityRaw : 425|11@0- (1,0) [-1024|1023] "" ACP3_MCU
 SG_ Object3RelativeLateralVelocityCandidateRaw : 382|9@0- (1,0) [-256|255] "" ACP3_MCU

BO_ 245 LFR_OBJECT_PAGE1_0F5: 64 LFR
 SG_ CycleCounter : 6|2@1+ (1,0) [0|3] "" ACP3_MCU

BO_ 246 LFR_AUX0_0F6: 48 LFR
 SG_ CycleCounter : 6|2@1+ (1,0) [0|3] "" ACP3_MCU

BO_ 247 RFR_OBJECT_PAGE2_0F7: 64 RFR
 SG_ CycleCounter : 6|2@1+ (1,0) [0|3] "" ACP3_MCU
 SG_ Object1TrackId : 102|6@0+ (1,0) [0|63] "" ACP3_MCU
 SG_ Object2TrackId : 226|6@0+ (1,0) [0|63] "" ACP3_MCU
 SG_ Object3TrackId : 374|6@0+ (1,0) [0|63] "" ACP3_MCU
 SG_ Object1RelativeLongitudinalVelocityRaw : 145|11@0- (1,0) [-1024|1023] "" ACP3_MCU
 SG_ Object1RelativeLateralVelocityCandidateRaw : 110|9@0- (1,0) [-256|255] "" ACP3_MCU
 SG_ Object2RelativeLongitudinalVelocityRaw : 293|11@0- (1,0) [-1024|1023] "" ACP3_MCU
 SG_ Object2RelativeLateralVelocityCandidateRaw : 234|9@0- (1,0) [-256|255] "" ACP3_MCU
 SG_ Object3RelativeLongitudinalVelocityRaw : 425|11@0- (1,0) [-1024|1023] "" ACP3_MCU
 SG_ Object3RelativeLateralVelocityCandidateRaw : 382|9@0- (1,0) [-256|255] "" ACP3_MCU

BO_ 248 RFR_OBJECT_PAGE3_0F8: 64 RFR
 SG_ CycleCounter : 6|2@1+ (1,0) [0|3] "" ACP3_MCU

BO_ 249 RFR_AUX1_0F9: 48 RFR
 SG_ CycleCounter : 6|2@1+ (1,0) [0|3] "" ACP3_MCU

BO_ 254 LCRR_SECURITY_AUX0_0FE: 48 LCRR
 SG_ SECOC_FRESHNESS : 39|5@0+ (1,0) [0|31] "" ACP3_MCU
 SG_ ApplicationCounter : 376|2@1+ (1,0) [0|3] "" ACP3_MCU
 SG_ Object0LongitudinalRaw : 278|11@0- (1,0) [-1024|1023] "" ACP3_MCU
 SG_ Object0TrackId : 240|6@0+ (1,0) [0|63] "" ACP3_MCU
 SG_ Object0RelativeLongitudinalVelocityRaw : 307|11@0- (1,0) [-1024|1023] "" ACP3_MCU
 SG_ Object0RelativeLateralVelocityCandidateRaw : 248|9@0- (1,0) [-256|255] "" ACP3_MCU

BO_ 255 LCRR_OBJECT_PAGE3_0FF: 64 LCRR
 SG_ CycleCounter : 6|2@1+ (1,0) [0|3] "" ACP3_MCU

BO_ 513 LCRR_AUX1_201: 48 LCRR
 SG_ CycleCounter : 6|2@1+ (1,0) [0|3] "" ACP3_MCU

BO_ 515 LRR_SIDE_OBJECT_PAGE1_203: 64 LRR_SIDE
 SG_ CycleCounter : 6|2@1+ (1,0) [0|3] "" ACP3_MCU

BO_ 516 LRR_SIDE_OBJECT_PAGE2_204: 64 LRR_SIDE
 SG_ CycleCounter : 6|2@1+ (1,0) [0|3] "" ACP3_MCU

BO_ 517 LRR_SIDE_OBJECT_PAGE3_205: 64 LRR_SIDE
 SG_ CycleCounter : 6|2@1+ (1,0) [0|3] "" ACP3_MCU
 SG_ Object0LongitudinalEstimate : 318|11@0- (0.125,0) [-128|127.875] "m" ACP3_MCU
 SG_ Object0LateralEstimate : 323|10@0- (0.125,0) [-64|63.875] "m" ACP3_MCU
 SG_ Object1LongitudinalEstimate : 329|11@0- (0.125,0) [-128|127.875] "m" ACP3_MCU
 SG_ Object1LateralEstimate : 350|10@0- (0.125,0) [-64|63.875] "m" ACP3_MCU
 SG_ Object2LongitudinalEstimate : 356|11@0- (0.125,0) [-128|127.875] "m" ACP3_MCU
 SG_ Object2LateralEstimate : 361|10@0- (0.125,0) [-64|63.875] "m" ACP3_MCU
 SG_ Object3LongitudinalEstimate : 383|11@0- (0.125,0) [-128|127.875] "m" ACP3_MCU
 SG_ Object3LateralEstimate : 388|10@0- (0.125,0) [-64|63.875] "m" ACP3_MCU
 SG_ Object4LongitudinalEstimate : 394|11@0- (0.125,0) [-128|127.875] "m" ACP3_MCU
 SG_ Object4LateralEstimate : 415|10@0- (0.125,0) [-64|63.875] "m" ACP3_MCU
 SG_ Object5LongitudinalEstimate : 421|11@0- (0.125,0) [-128|127.875] "m" ACP3_MCU
 SG_ Object5LateralEstimate : 426|10@0- (0.125,0) [-64|63.875] "m" ACP3_MCU
 SG_ Object6LongitudinalEstimate : 432|11@0- (0.125,0) [-128|127.875] "m" ACP3_MCU
 SG_ Object6LateralEstimate : 453|10@0- (0.125,0) [-64|63.875] "m" ACP3_MCU
 SG_ Object7LongitudinalEstimate : 459|11@0- (0.125,0) [-128|127.875] "m" ACP3_MCU
 SG_ Object7LateralEstimate : 464|10@0- (0.125,0) [-64|63.875] "m" ACP3_MCU
 SG_ Object8LongitudinalEstimate : 486|11@0- (0.125,0) [-128|127.875] "m" ACP3_MCU
 SG_ Object8LateralEstimate : 491|10@0- (0.125,0) [-64|63.875] "m" ACP3_MCU

BO_ 518 LRR_SIDE_AUX1_206: 48 LRR_SIDE
 SG_ CycleCounter : 6|2@1+ (1,0) [0|3] "" ACP3_MCU

BO_ 519 RRR_SIDE_OBJECT_PAGE2_207: 64 RRR_SIDE
 SG_ CycleCounter : 6|2@1+ (1,0) [0|3] "" ACP3_MCU
 SG_ Object1TrackId : 102|6@0+ (1,0) [0|63] "" ACP3_MCU
 SG_ Object2TrackId : 226|6@0+ (1,0) [0|63] "" ACP3_MCU
 SG_ Object3TrackId : 374|6@0+ (1,0) [0|63] "" ACP3_MCU
 SG_ Object1RelativeLongitudinalVelocityRaw : 145|11@0- (1,0) [-1024|1023] "" ACP3_MCU
 SG_ Object1RelativeLateralVelocityCandidateRaw : 110|9@0- (1,0) [-256|255] "" ACP3_MCU
 SG_ Object2RelativeLongitudinalVelocityRaw : 293|11@0- (1,0) [-1024|1023] "" ACP3_MCU
 SG_ Object2RelativeLateralVelocityCandidateRaw : 234|9@0- (1,0) [-256|255] "" ACP3_MCU
 SG_ Object3RelativeLongitudinalVelocityRaw : 425|11@0- (1,0) [-1024|1023] "" ACP3_MCU
 SG_ Object3RelativeLateralVelocityCandidateRaw : 382|9@0- (1,0) [-256|255] "" ACP3_MCU

BO_ 520 RRR_SIDE_OBJECT_PAGE4_208: 64 RRR_SIDE
 SG_ CycleCounter : 6|2@1+ (1,0) [0|3] "" ACP3_MCU

BO_ 522 RRR_SIDE_AUX1_20A: 48 RRR_SIDE
 SG_ CycleCounter : 6|2@1+ (1,0) [0|3] "" ACP3_MCU

BO_ 532 PARK_ASSIST_ULTRASONIC_BANK_B_214: 48 PARK_ASSIST
 SG_ AUTHENTICATOR : 7|32@0+ (1,0) [0|4294967295] "" ACP3_MCU
 SG_ SECOC_FRESHNESS : 39|5@0+ (1,0) [0|31] "" ACP3_MCU
 SG_ SECOC_AUX : 34|3@0+ (1,0) [0|7] "" ACP3_MCU
 SG_ ApplicationHeaderRaw : 40|8@1+ (1,0) [0|255] "" ACP3_MCU
 SG_ UltrasonicRecord1Raw : 48|48@1+ (1,0) [0|281474976710655] "" ACP3_MCU
 SG_ UltrasonicRecord2Raw : 96|48@1+ (1,0) [0|281474976710655] "" ACP3_MCU
 SG_ UltrasonicRecord3Raw : 144|48@1+ (1,0) [0|281474976710655] "" ACP3_MCU
 SG_ UltrasonicRecord4Raw : 192|48@1+ (1,0) [0|281474976710655] "" ACP3_MCU
 SG_ UltrasonicRecord5Raw : 240|48@1+ (1,0) [0|281474976710655] "" ACP3_MCU
 SG_ UltrasonicRecord6Raw : 288|48@1+ (1,0) [0|281474976710655] "" ACP3_MCU
 SG_ ApplicationTailRaw : 336|16@1+ (1,0) [0|65535] "" ACP3_MCU
 SG_ ReservedTail : 352|32@1+ (1,0) [0|4294967295] "" ACP3_MCU

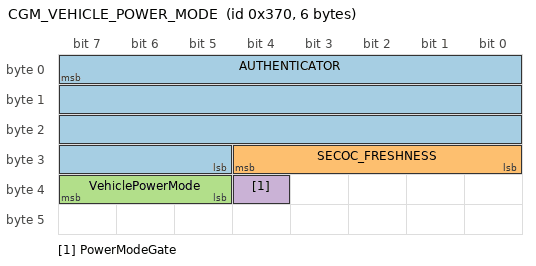
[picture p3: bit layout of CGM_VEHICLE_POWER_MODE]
BO_ 880 CGM_VEHICLE_POWER_MODE: 6 CGM
 SG_ AUTHENTICATOR : 7|27@0+ (1,0) [0|134217727] "" Vector__XXX
 SG_ SECOC_FRESHNESS : 28|5@0+ (1,0) [0|31] "" Vector__XXX
 SG_ VehiclePowerMode : 37|3@1+ (1,0) [0|7] "" Vector__XXX
 SG_ PowerModeGate : 36|1@1+ (1,0) [0|1] "" Vector__XXX

BO_ 882 ACP3_MCU_HOST_VEHICLE_SPEED_BAND_STATUS_FV: 8 ACP3_MCU
 SG_ SECOC_FRESHNESS_VALUE : 0|32@1+ (1,0) [0|4294967295] "" Vector__XXX

BO_ 883 PARK_ASSIST_ULTRASONIC_BANK_B_FV: 8 PARK_ASSIST
 SG_ SECOC_FRESHNESS_VALUE : 0|32@1+ (1,0) [0|4294967295] "" ACP3_MCU

BO_ 884 PARK_ASSIST_ULTRASONIC_BANK_A_FV: 8 PARK_ASSIST
 SG_ SECOC_FRESHNESS_VALUE : 0|32@1+ (1,0) [0|4294967295] "" ACP3_MCU

BO_ 962 CGM_SYSTEM_POWER_MODE_STATUS: 8 CGM
 SG_ SystemPowerModeProtectionFailSafe : 0|1@1+ (1,0) [0|1] "" Vector__XXX

BO_ 963 CGM_AUTHENTICATED_POWER_MODE: 8 CGM
 SG_ SystemPowerModeActive : 40|1@1+ (1,0) [0|1] "" Vector__XXX
 SG_ PrimaryRunCrankCommand : 44|4@1+ (1,0) [0|15] "" Vector__XXX

BO_ 1405 CGM_VEHICLE_POWER_MODE_FV: 8 CGM
 SG_ SECOC_FRESHNESS_VALUE : 0|32@1+ (1,0) [0|4294967295] "" Vector__XXX

BO_ 2147745830 ACP3_MCU_NodeStatus_CAN8: 1 ACP3_MCU
 SG_ NodeStatusBit0 : 0|1@1+ (1,0) [0|1] "" Vector__XXX

BO_ 213 CAN8_RX_0D5: 64 LRR
 SG_ Slot14LongitudinalEstimate : 318|11@0+ (0.125,0) [0|255.875] "m" ACP3_MCU
 SG_ Slot14LateralEstimate : 323|10@0- (0.125,0) [-64|63.875] "m" ACP3_MCU
 SG_ Slot16LongitudinalEstimate : 356|11@0+ (0.125,0) [0|255.875] "m" ACP3_MCU
 SG_ Slot16LateralEstimate : 361|10@0- (0.125,0) [-64|63.875] "m" ACP3_MCU
 SG_ Slot17LongitudinalEstimate : 383|11@0+ (0.125,0) [0|255.875] "m" ACP3_MCU
 SG_ Slot17LateralEstimate : 388|10@0- (0.125,0) [-64|63.875] "m" ACP3_MCU
 SG_ Slot18LongitudinalEstimate : 394|11@0+ (0.125,0) [0|255.875] "m" ACP3_MCU
 SG_ Slot18LateralEstimate : 415|10@0- (0.125,0) [-64|63.875] "m" ACP3_MCU

BO_ 214 CAN8_RX_0D6: 64 LRR

BO_ 215 CAN8_RX_0D7: 64 LRR

BO_ 241 CAN8_RX_0F1: 64 LRR

BO_ 242 CAN8_RX_0F2: 64 LRR

BO_ 243 CAN8_RX_0F3: 48 LRR

BO_ 593 CAN8_RX_251: 20 PARK_ASSIST

BO_ 594 CAN8_RX_252: 64 PARK_ASSIST
 SG_ SECOC_FRESHNESS : 39|5@0+ (1,0) [0|31] "" ACP3_MCU

BO_ 681 CAN8_RX_2A9: 4 LCRR

BO_ 719 CAN8_RX_2CF: 4 LCRR

BO_ 1317 CAN8_RX_525: 8 FCM

CM_ "GM Global B Super Cruise 1 physical CAN8 database. Unknown transmitters use Vector__XXX. RawField numbers are local to each message and do not identify a shared signal across messages.";
BO_ 648 RRR_SIDE_SECURITY_AUX0_0C1_FV: 8 RRR_SIDE
 SG_ SECOC_FRESHNESS_VALUE : 0|32@1+ (1,0) [0|4294967295] "" ACP3_MCU

BO_ 650 LRR_SIDE_SECURITY_AUX0_0C6_FV: 8 LRR_SIDE
 SG_ SECOC_FRESHNESS_VALUE : 0|32@1+ (1,0) [0|4294967295] "" ACP3_MCU

BO_ 654 RFR_SECURITY_AUX0_0D1_FV: 8 RFR
 SG_ SECOC_FRESHNESS_VALUE : 0|32@1+ (1,0) [0|4294967295] "" ACP3_MCU

BO_ 656 LFR_SECURITY_AUX1_0D4_FV: 8 LFR
 SG_ SECOC_FRESHNESS_VALUE : 0|32@1+ (1,0) [0|4294967295] "" ACP3_MCU

BO_ 655 LCRR_SECURITY_AUX0_0FE_FV: 8 LCRR
 SG_ SECOC_FRESHNESS_VALUE : 0|32@1+ (1,0) [0|4294967295] "" ACP3_MCU

BO_ 1326 CAN8_RX_252_FV: 8 PARK_ASSIST
 SG_ SECOC_FRESHNESS_VALUE : 0|32@1+ (1,0) [0|4294967295] "" ACP3_MCU

CM_ BO_ 33 "Transmitter: ACP3_MCU. Host-vehicle speed-band status. Transmitted every 100 ms.";
CM_ SG_ 33 HostVehicleSpeedBandState "Speed band with 5.5 km/h and 15 km/h thresholds and 0.5 km/h hysteresis. Direction is not encoded.";
CM_ SG_ 33 SpeedBandModeEnabled "Speed-band classifier enabled.";
CM_ SG_ 33 RollingCounter "Modulo-four application rolling counter.";
CM_ BO_ 882 "Transmitter: ACP3_MCU. Full freshness value for ACP3_MCU_HOST_VEHICLE_SPEED_BAND_STATUS.";
CM_ BO_ 880 "Transmitter: CGM. Transmitted by CGM; the payload is assembled from decoded gateway signals. CGM route: signal-gateway output on CAN8.";
CM_ BO_ 962 "Transmitter: CGM. Transmitted by CGM; reports protected system-power-mode fail-safe status. CGM route: signal-gateway output on CAN8.";
CM_ BO_ 963 "Transmitter: CGM. Transmitted by CGM; carries authenticated power-state inputs. CGM route: signal-gateway output on CAN8.";
CM_ BO_ 117 "Transmitter remains unresolved. Radar synchronization/status frame.";
CM_ BO_ 174 "Transmitter remains unresolved. Radar synchronization/status frame.";
CM_ BO_ 178 "Transmitter remains unresolved. Radar synchronization/status frame.";
CM_ BO_ 181 "Transmitter remains unresolved. Radar synchronization/status frame.";
CM_ BO_ 183 "Transmitter remains unresolved. Radar synchronization/status frame.";
CM_ BO_ 180 "Transmitter: PARK_ASSIST. Authenticated parking-assist ultrasonic bank containing six repeated six-byte records. Banks A and B are likely the front and rear sensor groups, but their physical assignment and record ordering are not yet established.";
CM_ BO_ 532 "Transmitter: PARK_ASSIST. Authenticated parking-assist ultrasonic bank containing six repeated six-byte records. Banks A and B are likely the front and rear sensor groups, but their physical assignment and record ordering are not yet established.";
CM_ BO_ 190 "Transmitter: RRR_SIDE.";
CM_ BO_ 191 "Transmitter: RRR_SIDE.";
CM_ BO_ 193 "Transmitter: RRR_SIDE.";
CM_ BO_ 197 "Transmitter: LRR_SIDE.";
CM_ BO_ 198 "Transmitter: LRR_SIDE.";
CM_ BO_ 199 "Transmitter: LCRR.";
CM_ BO_ 200 "Transmitter: LCRR.";
CM_ BO_ 201 "Transmitter: LCRR.";
CM_ BO_ 207 "Transmitter: RFR.";
CM_ BO_ 208 "Transmitter: RFR.";
CM_ BO_ 209 "Transmitter: RFR.";
CM_ BO_ 210 "Transmitter: LFR.";
CM_ BO_ 211 "Transmitter: LFR.";
CM_ BO_ 212 "Transmitter: LFR.";
CM_ BO_ 213 "Transmitter: LRR.";
CM_ BO_ 214 "Transmitter: LRR.";
CM_ BO_ 215 "Transmitter: LRR.";
CM_ BO_ 216 "Transmitter: FCM.";
CM_ BO_ 217 "Transmitter: FCM.";
CM_ BO_ 218 "Transmitter: FCM.";
CM_ BO_ 219 "Transmitter: FCM.";
CM_ BO_ 220 "Transmitter: FCM.";
CM_ BO_ 221 "Transmitter: FCM.";
CM_ BO_ 222 "Transmitter: FCM.";
CM_ BO_ 233 "Transmitter: FCM.";
CM_ BO_ 234 "Transmitter: FCM.";
CM_ BO_ 235 "Transmitter: FCM.";
CM_ BO_ 236 "Transmitter: FCM.";
CM_ BO_ 237 "Four repeated lane-model candidates: two boundary offsets and two equal centre offsets, with common curvature and heading in tested recordings. Centre is approximately the boundary midpoint; exceptional frames and OEM validity remain unresolved. Support-like trailing fields are not confirmed validity flags. No physical units or steering-command interpretation assigned.";
CM_ BO_ 238 "Transmitter: FCM.";
CM_ BO_ 239 "Transmitter: FCM.";
CM_ BO_ 240 "Transmitter: FCM.";
CM_ BO_ 241 "Transmitter: LRR.";
CM_ BO_ 242 "Transmitter: LRR.";
CM_ BO_ 243 "Transmitter: LRR.";
CM_ BO_ 244 "Transmitter: LFR.";
CM_ BO_ 245 "Transmitter: LFR.";
CM_ BO_ 246 "Transmitter: LFR.";
CM_ BO_ 247 "Transmitter: RFR.";
CM_ BO_ 248 "Transmitter: RFR.";
CM_ BO_ 249 "Transmitter: RFR.";
CM_ BO_ 254 "Transmitter: LCRR.";
CM_ BO_ 255 "Transmitter: LCRR.";
CM_ BO_ 513 "Transmitter: LCRR.";
CM_ BO_ 515 "Transmitter: LRR_SIDE.";
CM_ BO_ 516 "Transmitter: LRR_SIDE.";
CM_ BO_ 517 "Transmitter: LRR_SIDE.";
CM_ BO_ 518 "Transmitter: LRR_SIDE.";
CM_ BO_ 519 "Transmitter: RRR_SIDE.";
CM_ BO_ 520 "Transmitter: RRR_SIDE.";
CM_ BO_ 522 "Transmitter: RRR_SIDE.";
CM_ BO_ 593 "Transmitter: PARK_ASSIST.";
CM_ BO_ 594 "Transmitter: PARK_ASSIST.";
CM_ BO_ 681 "Transmitter: LCRR.";
CM_ BO_ 719 "Transmitter: LCRR.";
CM_ BO_ 1317 "Transmitter: FCM.";
CM_ BO_ 1405 "Transmitter: CGM. CGM route: signal-gateway output on CAN8.";
CM_ SG_ 963 PrimaryRunCrankCommand "The exact command-value labels remain unknown.";

CM_ SG_ 222 RightLaneCurvatureRaw "Image-space curvature fit only; physical radius scale is unverified. Heading and extent retain raw units.";
CM_ SG_ 222 RightLaneStateRaw "State meaning unresolved. Values 1 and 2 both occur with valid-looking lanes; do not interpret as an availability flag.";
CM_ SG_ 233 LeftLaneCurvatureRaw "Image-space curvature fit only; physical radius scale is unverified. Heading and extent retain raw units.";
CM_ SG_ 233 LeftLaneStateRaw "State meaning unresolved. Values 1 and 2 both occur with valid-looking lanes; do not interpret as an availability flag.";
CM_ SG_ 221 Object0IdCandidate "Candidate identity can follow a vehicle across records; not proven globally unique or persistent. Object0 denotes this message record, not a fixed vehicle.";
CM_ SG_ 222 Object0IdCandidate "Candidate identity can follow a vehicle across records; not proven globally unique or persistent. Object0 denotes this message record, not a fixed vehicle.";
CM_ SG_ 233 Object0IdCandidate "Candidate identity can follow a vehicle across records; not proven globally unique or persistent. Object0 denotes this message record, not a fixed vehicle.";
CM_ SG_ 212 Object0LongitudinalRaw "First-object longitudinal duplicate at MSB-stream bit273; agrees within one raw count with its compact summary in the rear-left pass recording. Not an additional target.";
CM_ SG_ 209 Object0LongitudinalRaw "First-object longitudinal duplicate at MSB-stream bit273; agrees within one raw count with its compact summary in the rear-left pass recording. Not an additional target.";
CM_ SG_ 198 Object0LongitudinalRaw "First-object longitudinal duplicate at MSB-stream bit273; agrees within one raw count with its compact summary in the rear-left pass recording. Not an additional target.";
CM_ SG_ 193 Object0LongitudinalRaw "First-object longitudinal duplicate at MSB-stream bit273; agrees within one raw count with its compact summary in the rear-left pass recording. Not an additional target.";
CM_ SG_ 254 Object0LongitudinalRaw "First-object longitudinal duplicate at MSB-stream bit273; agrees within one raw count with its compact summary in the rear-left pass recording. Not an additional target.";
CM_ SG_ 180 UltrasonicRecord1Raw "All six six-byte records contain candidate 11-bit echo values at MSB-first record offsets 4,15,26. Repeated 2000 appears to be a sentinel; zeros and remaining bits need validity decoding. Millimetres, bank position and sensor order remain hypotheses. Raw records intentionally retained.";
CM_ SG_ 532 UltrasonicRecord1Raw "All six six-byte records contain candidate 11-bit echo values at MSB-first record offsets 4,15,26. Repeated 2000 appears to be a sentinel; zeros and remaining bits need validity decoding. Millimetres, bank position and sensor order remain hypotheses. Raw records intentionally retained.";

CM_ SG_ 219 Object0IdCandidate "Six-bit identity candidate; not proven globally unique or persistent. Record index is not vehicle identity. RelativeMotionCandidate retains uncalibrated signed raw units.";
CM_ SG_ 219 Object1IdCandidate "Six-bit identity candidate; not proven globally unique or persistent. Record index is not vehicle identity. RelativeMotionCandidate retains uncalibrated signed raw units.";
CM_ SG_ 220 Object0IdCandidate "Six-bit identity candidate; not proven globally unique or persistent. Record index is not vehicle identity. RelativeMotionCandidate retains uncalibrated signed raw units.";
CM_ SG_ 220 Object1IdCandidate "Six-bit identity candidate; not proven globally unique or persistent. Record index is not vehicle identity. RelativeMotionCandidate retains uncalibrated signed raw units.";
CM_ SG_ 234 Object0IdCandidate "Six-bit identity candidate; not proven globally unique or persistent. Record index is not vehicle identity. RelativeMotionCandidate retains uncalibrated signed raw units.";
CM_ SG_ 235 Object0IdCandidate "Six-bit identity candidate; not proven globally unique or persistent. Record index is not vehicle identity. RelativeMotionCandidate retains uncalibrated signed raw units.";
CM_ SG_ 236 Object0IdCandidate "Six-bit identity candidate; not proven globally unique or persistent. Record index is not vehicle identity. RelativeMotionCandidate retains uncalibrated signed raw units.";

BA_DEF_ BO_ "GenMsgCycleTime" INT 0 65535;
BA_DEF_ BO_ "VFrameFormat" ENUM "StandardCAN","ExtendedCAN","reserved","J1939PG","StandardCAN_FD","ExtendedCAN_FD";
BA_DEF_ BO_ "SecOCKeyRole" STRING;
BA_DEF_ BO_ "SecOCDataId" INT 0 255;
BA_DEF_ BO_ "SecOCCompanionId" INT 0 536870911;

BA_DEF_DEF_ "GenMsgCycleTime" 0;
BA_DEF_DEF_ "VFrameFormat" "StandardCAN";

BA_ "SecOCKeyRole" BO_ 33 "safety_control_key";
BA_ "SecOCDataId" BO_ 33 1;
BA_ "SecOCCompanionId" BO_ 33 882;
BA_ "SecOCKeyRole" BO_ 180 "parking_assist_key";
BA_ "SecOCDataId" BO_ 180 1;
BA_ "SecOCCompanionId" BO_ 180 884;
BA_ "SecOCKeyRole" BO_ 532 "parking_assist_key";
BA_ "SecOCDataId" BO_ 532 1;
BA_ "SecOCCompanionId" BO_ 532 883;
BA_ "SecOCKeyRole" BO_ 880 "central_gateway_key";
BA_ "SecOCDataId" BO_ 880 1;
BA_ "SecOCCompanionId" BO_ 880 1405;
BA_ "GenMsgCycleTime" BO_ 33 100;
BA_ "GenMsgCycleTime" BO_ 117 50;
BA_ "GenMsgCycleTime" BO_ 174 50;
BA_ "GenMsgCycleTime" BO_ 178 50;
BA_ "GenMsgCycleTime" BO_ 180 40;
BA_ "GenMsgCycleTime" BO_ 181 50;
BA_ "GenMsgCycleTime" BO_ 183 50;
BA_ "GenMsgCycleTime" BO_ 190 50;
BA_ "GenMsgCycleTime" BO_ 191 50;
BA_ "GenMsgCycleTime" BO_ 193 50;
BA_ "GenMsgCycleTime" BO_ 197 50;
BA_ "GenMsgCycleTime" BO_ 198 50;
BA_ "GenMsgCycleTime" BO_ 199 50;
BA_ "GenMsgCycleTime" BO_ 200 50;
BA_ "GenMsgCycleTime" BO_ 201 50;
BA_ "GenMsgCycleTime" BO_ 207 50;
BA_ "GenMsgCycleTime" BO_ 208 50;
BA_ "GenMsgCycleTime" BO_ 209 50;
BA_ "GenMsgCycleTime" BO_ 210 50;
BA_ "GenMsgCycleTime" BO_ 211 50;
BA_ "GenMsgCycleTime" BO_ 212 50;
BA_ "GenMsgCycleTime" BO_ 216 30;
BA_ "GenMsgCycleTime" BO_ 217 30;
BA_ "GenMsgCycleTime" BO_ 218 30;
BA_ "GenMsgCycleTime" BO_ 219 30;
BA_ "GenMsgCycleTime" BO_ 220 30;
BA_ "GenMsgCycleTime" BO_ 221 30;
BA_ "GenMsgCycleTime" BO_ 222 30;
BA_ "GenMsgCycleTime" BO_ 233 30;
BA_ "GenMsgCycleTime" BO_ 234 30;
BA_ "GenMsgCycleTime" BO_ 235 30;
BA_ "GenMsgCycleTime" BO_ 236 30;
BA_ "GenMsgCycleTime" BO_ 237 30;
BA_ "GenMsgCycleTime" BO_ 238 30;
BA_ "GenMsgCycleTime" BO_ 239 30;
BA_ "GenMsgCycleTime" BO_ 240 30;
BA_ "GenMsgCycleTime" BO_ 244 50;
BA_ "GenMsgCycleTime" BO_ 245 50;
BA_ "GenMsgCycleTime" BO_ 246 50;
BA_ "GenMsgCycleTime" BO_ 247 50;
BA_ "GenMsgCycleTime" BO_ 248 50;
BA_ "GenMsgCycleTime" BO_ 249 50;
BA_ "GenMsgCycleTime" BO_ 254 50;
BA_ "GenMsgCycleTime" BO_ 255 50;
BA_ "GenMsgCycleTime" BO_ 513 50;
BA_ "GenMsgCycleTime" BO_ 515 50;
BA_ "GenMsgCycleTime" BO_ 516 50;
BA_ "GenMsgCycleTime" BO_ 517 50;
BA_ "GenMsgCycleTime" BO_ 518 50;
BA_ "GenMsgCycleTime" BO_ 519 50;
BA_ "GenMsgCycleTime" BO_ 520 50;
BA_ "GenMsgCycleTime" BO_ 522 50;
BA_ "GenMsgCycleTime" BO_ 532 40;
BA_ "GenMsgCycleTime" BO_ 880 250;
BA_ "GenMsgCycleTime" BO_ 882 1600;
BA_ "GenMsgCycleTime" BO_ 883 640;
BA_ "GenMsgCycleTime" BO_ 884 640;
BA_ "GenMsgCycleTime" BO_ 1405 1000;
BA_ "GenMsgCycleTime" BO_ 962 1000;
BA_ "GenMsgCycleTime" BO_ 963 1000;
BA_ "GenMsgCycleTime" BO_ 2147745830 1000;
BA_ "GenMsgCycleTime" BO_ 213 50;
BA_ "GenMsgCycleTime" BO_ 214 50;
BA_ "GenMsgCycleTime" BO_ 215 50;
BA_ "GenMsgCycleTime" BO_ 241 50;
BA_ "GenMsgCycleTime" BO_ 242 50;
BA_ "GenMsgCycleTime" BO_ 243 50;
BA_ "GenMsgCycleTime" BO_ 593 100;
BA_ "GenMsgCycleTime" BO_ 594 100;
BA_ "GenMsgCycleTime" BO_ 681 100;
BA_ "GenMsgCycleTime" BO_ 719 100;
BA_ "GenMsgCycleTime" BO_ 1317 1000;
BA_ "VFrameFormat" BO_ 33 4;
BA_ "VFrameFormat" BO_ 117 4;
BA_ "VFrameFormat" BO_ 174 4;
BA_ "VFrameFormat" BO_ 178 4;
BA_ "VFrameFormat" BO_ 180 4;
BA_ "VFrameFormat" BO_ 181 4;
BA_ "VFrameFormat" BO_ 183 4;
BA_ "VFrameFormat" BO_ 190 4;
BA_ "VFrameFormat" BO_ 191 4;
BA_ "VFrameFormat" BO_ 193 4;
BA_ "VFrameFormat" BO_ 197 4;
BA_ "VFrameFormat" BO_ 198 4;
BA_ "VFrameFormat" BO_ 199 4;
BA_ "VFrameFormat" BO_ 200 4;
BA_ "VFrameFormat" BO_ 201 4;
BA_ "VFrameFormat" BO_ 207 4;
BA_ "VFrameFormat" BO_ 208 4;
BA_ "VFrameFormat" BO_ 209 4;
BA_ "VFrameFormat" BO_ 210 4;
BA_ "VFrameFormat" BO_ 211 4;
BA_ "VFrameFormat" BO_ 212 4;
BA_ "VFrameFormat" BO_ 216 4;
BA_ "VFrameFormat" BO_ 217 4;
BA_ "VFrameFormat" BO_ 218 4;
BA_ "VFrameFormat" BO_ 219 4;
BA_ "VFrameFormat" BO_ 220 4;
BA_ "VFrameFormat" BO_ 221 4;
BA_ "VFrameFormat" BO_ 222 4;
BA_ "VFrameFormat" BO_ 233 4;
BA_ "VFrameFormat" BO_ 234 4;
BA_ "VFrameFormat" BO_ 235 4;
BA_ "VFrameFormat" BO_ 236 4;
BA_ "VFrameFormat" BO_ 237 4;
BA_ "VFrameFormat" BO_ 238 4;
BA_ "VFrameFormat" BO_ 239 4;
BA_ "VFrameFormat" BO_ 240 4;
BA_ "VFrameFormat" BO_ 244 4;
BA_ "VFrameFormat" BO_ 245 4;
BA_ "VFrameFormat" BO_ 246 4;
BA_ "VFrameFormat" BO_ 247 4;
BA_ "VFrameFormat" BO_ 248 4;
BA_ "VFrameFormat" BO_ 249 4;
BA_ "VFrameFormat" BO_ 254 4;
BA_ "VFrameFormat" BO_ 255 4;
BA_ "VFrameFormat" BO_ 513 4;
BA_ "VFrameFormat" BO_ 515 4;
BA_ "VFrameFormat" BO_ 516 4;
BA_ "VFrameFormat" BO_ 517 4;
BA_ "VFrameFormat" BO_ 518 4;
BA_ "VFrameFormat" BO_ 519 4;
BA_ "VFrameFormat" BO_ 520 4;
BA_ "VFrameFormat" BO_ 522 4;
BA_ "VFrameFormat" BO_ 532 4;
BA_ "VFrameFormat" BO_ 882 4;
BA_ "VFrameFormat" BO_ 883 4;
BA_ "VFrameFormat" BO_ 884 4;
BA_ "VFrameFormat" BO_ 2147745830 1;
BA_ "VFrameFormat" BO_ 213 4;
BA_ "VFrameFormat" BO_ 214 4;
BA_ "VFrameFormat" BO_ 215 4;
BA_ "VFrameFormat" BO_ 241 4;
BA_ "VFrameFormat" BO_ 242 4;
BA_ "VFrameFormat" BO_ 243 4;
BA_ "VFrameFormat" BO_ 593 4;
BA_ "VFrameFormat" BO_ 594 4;
BA_ "VFrameFormat" BO_ 681 4;
BA_ "VFrameFormat" BO_ 719 4;
BA_ "VFrameFormat" BO_ 1317 4;

VAL_ 117 StateRaw 1 "Unknown_State_1";
VAL_ 174 StateRaw 1 "Unknown_State_1";
VAL_ 178 StateRaw 1 "Unknown_State_1";
VAL_ 181 StateRaw 1 "Unknown_State_1";
VAL_ 183 StateRaw 1 "Unknown_State_1";
VAL_ 33 HostVehicleSpeedBandState 0 "Inactive" 1 "Low_Speed" 2 "Medium_Speed" 3 "High_Speed";
VAL_ 33 SpeedBandModeEnabled 0 "Disabled" 1 "Enabled";
VAL_ 880 VehiclePowerMode 0 "Off" 1 "Accessory" 2 "Run" 3 "Start_Crank" 4 "Propulsion";
VAL_ 880 PowerModeGate 0 "Inactive" 1 "Active";
VAL_ 962 SystemPowerModeProtectionFailSafe 0 "Inactive" 1 "Active";
VAL_ 963 SystemPowerModeActive 0 "Inactive" 1 "Active";
VAL_ 2147745830 NodeStatusBit0 0 "Unknown_0" 1 "Unknown_1";

BA_ "SecOCCompanionId" BO_ 193 648;
BA_ "SecOCCompanionId" BO_ 198 650;
BA_ "SecOCCompanionId" BO_ 209 654;
BA_ "SecOCCompanionId" BO_ 212 656;
BA_ "SecOCCompanionId" BO_ 254 655;
BA_ "SecOCCompanionId" BO_ 594 1326;

BO_ 204 CAMERA_LANE_MODEL_RIGHT_CANDIDATE_0CC: 48 Vector__XXX
 SG_ LaneCurvatureCandidateRaw : 37|16@0- (1,0) [-32768|32767] "" Vector__XXX
 SG_ LaneCurvatureRateCandidateRaw : 53|16@0- (1,0) [-32768|32767] "" Vector__XXX
 SG_ LaneHeadingCandidateRaw : 69|10@0- (1,0) [-512|511] "" Vector__XXX
 SG_ LaneOffsetEstimate : 75|13@0- (0.00390625,0) [-16|15.99609375] "m" Vector__XXX

CM_ BO_ 204 "Empirical right lane-model candidate. Geometric fields track the corresponding camera boundary; this may be processed or copied camera data, not an independent sensor. Transmitter, validity bits, unused payload and physical units remain unresolved.";
BA_ "VFrameFormat" BO_ 204 4;

BO_ 206 CAMERA_LANE_MODEL_LEFT_CANDIDATE_0CE: 64 Vector__XXX
 SG_ LaneCurvatureCandidateRaw : 37|16@0- (1,0) [-32768|32767] "" Vector__XXX
 SG_ LaneCurvatureRateCandidateRaw : 53|16@0- (1,0) [-32768|32767] "" Vector__XXX
 SG_ LaneHeadingCandidateRaw : 69|10@0- (1,0) [-512|511] "" Vector__XXX
 SG_ LaneOffsetEstimate : 75|13@0- (0.00390625,0) [-16|15.99609375] "m" Vector__XXX

CM_ BO_ 206 "Empirical left lane-model candidate. Geometric fields track the corresponding camera boundary; this may be processed or copied camera data, not an independent sensor. Transmitter, validity bits, unused payload and physical units remain unresolved.";
BA_ "VFrameFormat" BO_ 206 4;

CM_ SG_ 237 LeftBoundaryCandidateSupportRaw "Empirical support-like field. Zero in the checked parked recording and positive during supported highway tracking; OEM validity semantics and physical units remain unresolved. Application thresholds are not a decoded validity flag.";
CM_ SG_ 237 LeftBoundaryCandidateExtentRaw "Empirical extent-like field. Zero in the checked parked recording and positive during supported highway tracking; OEM validity semantics and physical units remain unresolved. Application thresholds are not a decoded validity flag.";
CM_ SG_ 237 RightBoundaryCandidateSupportRaw "Empirical support-like field. Zero in the checked parked recording and positive during supported highway tracking; OEM validity semantics and physical units remain unresolved. Application thresholds are not a decoded validity flag.";
CM_ SG_ 237 RightBoundaryCandidateExtentRaw "Empirical extent-like field. Zero in the checked parked recording and positive during supported highway tracking; OEM validity semantics and physical units remain unresolved. Application thresholds are not a decoded validity flag.";
CM_ SG_ 237 CenterCandidateSupportRaw "Empirical support-like field. Zero in the checked parked recording and positive during supported highway tracking; OEM validity semantics and physical units remain unresolved. Application thresholds are not a decoded validity flag.";
CM_ SG_ 237 CenterCandidateExtentRaw "Empirical extent-like field. Zero in the checked parked recording and positive during supported highway tracking; OEM validity semantics and physical units remain unresolved. Application thresholds are not a decoded validity flag.";
CM_ SG_ 237 CenterCopyCandidateSupportRaw "Empirical support-like field. Zero in the checked parked recording and positive during supported highway tracking; OEM validity semantics and physical units remain unresolved. Application thresholds are not a decoded validity flag.";
CM_ SG_ 237 CenterCopyCandidateExtentRaw "Empirical extent-like field. Zero in the checked parked recording and positive during supported highway tracking; OEM validity semantics and physical units remain unresolved. Application thresholds are not a decoded validity flag.";

CM_ SG_ 221 OuterRightLaneCandidateSupportRaw "Support-like raw field, not a confirmed validity flag. Nonzero values can persist with frozen geometry.";
CM_ SG_ 234 OuterLeftLaneCandidateSupportRaw "Support-like raw field, not a confirmed validity flag. Nonzero values can persist with frozen geometry.";

CM_ SG_ 219 RightRoadEdgeCandidateCurvatureRaw "Empirical right road-edge candidate; same polynomial representation as camera lanes. Image alignment supports pavement/curb boundary; physical units and exact OEM boundary class unresolved. Activity zero retains old geometry.";

CM_ SG_ 219 RightRoadEdgeCandidateCurvatureRateRaw "Empirical right road-edge candidate; same polynomial representation as camera lanes. Image alignment supports pavement/curb boundary; physical units and exact OEM boundary class unresolved. Activity zero retains old geometry.";

CM_ SG_ 219 RightRoadEdgeCandidateHeadingRaw "Empirical right road-edge candidate; same polynomial representation as camera lanes. Image alignment supports pavement/curb boundary; physical units and exact OEM boundary class unresolved. Activity zero retains old geometry.";

CM_ SG_ 219 RightRoadEdgeCandidateActivityCandidateRaw "Empirical polynomial activity: 0 retains geometry; 2 and 3 can update geometry; 1 not observed. Not an OEM validity or confidence enum. Freshness and geometric checks remain necessary.";

CM_ SG_ 220 RightSecondaryBoundaryCandidateActivityCandidateRaw "Empirical polynomial activity: 0 retains geometry; 2 and 3 can update geometry; 1 not observed. Not an OEM validity or confidence enum. Freshness and geometric checks remain necessary.";

CM_ SG_ 221 OuterRightLaneCandidateActivityCandidateRaw "Empirical polynomial activity: 0 retains geometry; 2 and 3 can update geometry; 1 not observed. Not an OEM validity or confidence enum. Freshness and geometric checks remain necessary.";

CM_ SG_ 222 RightLaneActivityCandidateRaw "Empirical polynomial activity: 0 retains geometry; 2 and 3 can update geometry; 1 not observed. Not an OEM validity or confidence enum. Freshness and geometric checks remain necessary.";

CM_ SG_ 233 LeftLaneActivityCandidateRaw "Empirical polynomial activity: 0 retains geometry; 2 and 3 can update geometry; 1 not observed. Not an OEM validity or confidence enum. Freshness and geometric checks remain necessary.";

CM_ SG_ 234 OuterLeftLaneCandidateActivityCandidateRaw "Empirical polynomial activity: 0 retains geometry; 2 and 3 can update geometry; 1 not observed. Not an OEM validity or confidence enum. Freshness and geometric checks remain necessary.";

CM_ SG_ 235 LeftSecondaryBoundaryCandidateActivityCandidateRaw "Empirical polynomial activity: 0 retains geometry; 2 and 3 can update geometry; 1 not observed. Not an OEM validity or confidence enum. Freshness and geometric checks remain necessary.";

CM_ SG_ 236 LeftRoadEdgeCandidateCurvatureRaw "Empirical left road-edge candidate; same polynomial representation as camera lanes. Image alignment supports pavement/curb boundary; physical units and exact OEM boundary class unresolved. Activity zero retains old geometry.";

CM_ SG_ 236 LeftRoadEdgeCandidateCurvatureRateRaw "Empirical left road-edge candidate; same polynomial representation as camera lanes. Image alignment supports pavement/curb boundary; physical units and exact OEM boundary class unresolved. Activity zero retains old geometry.";

CM_ SG_ 236 LeftRoadEdgeCandidateHeadingRaw "Empirical left road-edge candidate; same polynomial representation as camera lanes. Image alignment supports pavement/curb boundary; physical units and exact OEM boundary class unresolved. Activity zero retains old geometry.";

CM_ SG_ 236 LeftRoadEdgeCandidateActivityCandidateRaw "Empirical polynomial activity: 0 retains geometry; 2 and 3 can update geometry; 1 not observed. Not an OEM validity or confidence enum. Freshness and geometric checks remain necessary.";

CM_ SG_ 219 RightRoadEdgeCandidateRoleCandidateRaw "Observed active role value is fixed by slot: E9=1, DE=2, EA=3, DD=4, EB=5, DC=6, EC=7, DB=8. Slots5/6 align with farther left/right boundaries in image review; exact paint/barrier class unresolved. Zero commonly accompanies retained/inactive geometry.";

CM_ SG_ 220 RightSecondaryBoundaryCandidateRoleCandidateRaw "Observed active role value is fixed by slot: E9=1, DE=2, EA=3, DD=4, EB=5, DC=6, EC=7, DB=8. Slots5/6 align with farther left/right boundaries in image review; exact paint/barrier class unresolved. Zero commonly accompanies retained/inactive geometry.";

CM_ SG_ 221 OuterRightLaneCandidateRoleCandidateRaw "Observed active role value is fixed by slot: E9=1, DE=2, EA=3, DD=4, EB=5, DC=6, EC=7, DB=8. Slots5/6 align with farther left/right boundaries in image review; exact paint/barrier class unresolved. Zero commonly accompanies retained/inactive geometry.";

CM_ SG_ 222 RightLaneRoleCandidateRaw "Observed active role value is fixed by slot: E9=1, DE=2, EA=3, DD=4, EB=5, DC=6, EC=7, DB=8. Slots5/6 align with farther left/right boundaries in image review; exact paint/barrier class unresolved. Zero commonly accompanies retained/inactive geometry.";

CM_ SG_ 233 LeftLaneRoleCandidateRaw "Observed active role value is fixed by slot: E9=1, DE=2, EA=3, DD=4, EB=5, DC=6, EC=7, DB=8. Slots5/6 align with farther left/right boundaries in image review; exact paint/barrier class unresolved. Zero commonly accompanies retained/inactive geometry.";

CM_ SG_ 234 OuterLeftLaneCandidateRoleCandidateRaw "Observed active role value is fixed by slot: E9=1, DE=2, EA=3, DD=4, EB=5, DC=6, EC=7, DB=8. Slots5/6 align with farther left/right boundaries in image review; exact paint/barrier class unresolved. Zero commonly accompanies retained/inactive geometry.";

CM_ SG_ 235 LeftSecondaryBoundaryCandidateRoleCandidateRaw "Observed active role value is fixed by slot: E9=1, DE=2, EA=3, DD=4, EB=5, DC=6, EC=7, DB=8. Slots5/6 align with farther left/right boundaries in image review; exact paint/barrier class unresolved. Zero commonly accompanies retained/inactive geometry.";

CM_ SG_ 236 LeftRoadEdgeCandidateRoleCandidateRaw "Observed active role value is fixed by slot: E9=1, DE=2, EA=3, DD=4, EB=5, DC=6, EC=7, DB=8. Slots5/6 align with farther left/right boundaries in image review; exact paint/barrier class unresolved. Zero commonly accompanies retained/inactive geometry.";

CM_ SG_ 206 LaneOffsetEstimate "Metric estimate from lane-width and image-ground-contact calibration; not independently surveyed or OEM confirmed. Encoding unchanged; raw values remain available with scaling disabled. Apply freshness/activity and geometry checks; offset alone does not establish a valid boundary.";

CM_ SG_ 219 RightRoadEdgeCandidateOffsetEstimate "Metric estimate from lane-width and image-ground-contact calibration; not independently surveyed or OEM confirmed. Encoding unchanged; raw values remain available with scaling disabled. Apply freshness/activity and geometry checks; offset alone does not establish a valid boundary.";

CM_ SG_ 219 RightRoadEdgeCandidateRangeEndEstimate "Metric estimate from lane-width and image-ground-contact calibration; not independently surveyed or OEM confirmed. Encoding unchanged; raw values remain available with scaling disabled. Boundary endpoint: activity zero retains old values; 127 may be a range ceiling.";

CM_ SG_ 219 RightRoadEdgeCandidateRangeStartEstimate "Metric estimate from lane-width and image-ground-contact calibration; not independently surveyed or OEM confirmed. Encoding unchanged; raw values remain available with scaling disabled. Boundary endpoint: activity zero retains old values; 127 may be a range ceiling.";

CM_ SG_ 219 Object0LongitudinalEstimate "Metric estimate from lane-width and image-ground-contact calibration; not independently surveyed or OEM confirmed. Encoding unchanged; raw values remain available with scaling disabled. Position or velocity does not independently establish object validity; retain source identity and freshness checks.";

CM_ SG_ 219 Object0RelativeLongitudinalVelocityEstimate "Metric estimate from lane-width and image-ground-contact calibration; not independently surveyed or OEM confirmed. Encoding unchanged; raw values remain available with scaling disabled. Position or velocity does not independently establish object validity; retain source identity and freshness checks.";

CM_ SG_ 219 Object0LateralEstimate "Metric estimate from lane-width and image-ground-contact calibration; not independently surveyed or OEM confirmed. Encoding unchanged; raw values remain available with scaling disabled. Position or velocity does not independently establish object validity; retain source identity and freshness checks.";

CM_ SG_ 219 Object0RelativeLateralVelocityEstimate "Metric estimate from lane-width and image-ground-contact calibration; not independently surveyed or OEM confirmed. Encoding unchanged; raw values remain available with scaling disabled. Position or velocity does not independently establish object validity; retain source identity and freshness checks. Raw -256/+255 endpoints excluded from numeric extrapolation; exact sentinel semantics unverified.";

CM_ SG_ 219 Object1LongitudinalEstimate "Metric estimate from lane-width and image-ground-contact calibration; not independently surveyed or OEM confirmed. Encoding unchanged; raw values remain available with scaling disabled. Position or velocity does not independently establish object validity; retain source identity and freshness checks.";

CM_ SG_ 219 Object1RelativeLongitudinalVelocityEstimate "Metric estimate from lane-width and image-ground-contact calibration; not independently surveyed or OEM confirmed. Encoding unchanged; raw values remain available with scaling disabled. Position or velocity does not independently establish object validity; retain source identity and freshness checks.";

CM_ SG_ 219 Object1LateralEstimate "Metric estimate from lane-width and image-ground-contact calibration; not independently surveyed or OEM confirmed. Encoding unchanged; raw values remain available with scaling disabled. Position or velocity does not independently establish object validity; retain source identity and freshness checks.";

CM_ SG_ 219 Object1RelativeLateralVelocityEstimate "Metric estimate from lane-width and image-ground-contact calibration; not independently surveyed or OEM confirmed. Encoding unchanged; raw values remain available with scaling disabled. Position or velocity does not independently establish object validity; retain source identity and freshness checks. Raw -256/+255 endpoints excluded from numeric extrapolation; exact sentinel semantics unverified.";

CM_ SG_ 220 RightSecondaryBoundaryCandidateOffsetEstimate "Metric estimate from lane-width and image-ground-contact calibration; not independently surveyed or OEM confirmed. Encoding unchanged; raw values remain available with scaling disabled. Apply freshness/activity and geometry checks; offset alone does not establish a valid boundary.";

CM_ SG_ 220 RightSecondaryBoundaryCandidateRangeEndEstimate "Metric estimate from lane-width and image-ground-contact calibration; not independently surveyed or OEM confirmed. Encoding unchanged; raw values remain available with scaling disabled. Boundary endpoint: activity zero retains old values; 127 may be a range ceiling.";

CM_ SG_ 220 RightSecondaryBoundaryCandidateRangeStartEstimate "Metric estimate from lane-width and image-ground-contact calibration; not independently surveyed or OEM confirmed. Encoding unchanged; raw values remain available with scaling disabled. Boundary endpoint: activity zero retains old values; 127 may be a range ceiling.";

CM_ SG_ 220 Object0LongitudinalEstimate "Metric estimate from lane-width and image-ground-contact calibration; not independently surveyed or OEM confirmed. Encoding unchanged; raw values remain available with scaling disabled. Position or velocity does not independently establish object validity; retain source identity and freshness checks.";

CM_ SG_ 220 Object0RelativeLongitudinalVelocityEstimate "Metric estimate from lane-width and image-ground-contact calibration; not independently surveyed or OEM confirmed. Encoding unchanged; raw values remain available with scaling disabled. Position or velocity does not independently establish object validity; retain source identity and freshness checks.";

CM_ SG_ 220 Object0LateralEstimate "Metric estimate from lane-width and image-ground-contact calibration; not independently surveyed or OEM confirmed. Encoding unchanged; raw values remain available with scaling disabled. Position or velocity does not independently establish object validity; retain source identity and freshness checks.";

CM_ SG_ 220 Object0RelativeLateralVelocityEstimate "Metric estimate from lane-width and image-ground-contact calibration; not independently surveyed or OEM confirmed. Encoding unchanged; raw values remain available with scaling disabled. Position or velocity does not independently establish object validity; retain source identity and freshness checks. Raw -256/+255 endpoints excluded from numeric extrapolation; exact sentinel semantics unverified.";

CM_ SG_ 220 Object1LongitudinalEstimate "Metric estimate from lane-width and image-ground-contact calibration; not independently surveyed or OEM confirmed. Encoding unchanged; raw values remain available with scaling disabled. Position or velocity does not independently establish object validity; retain source identity and freshness checks.";

CM_ SG_ 220 Object1RelativeLongitudinalVelocityEstimate "Metric estimate from lane-width and image-ground-contact calibration; not independently surveyed or OEM confirmed. Encoding unchanged; raw values remain available with scaling disabled. Position or velocity does not independently establish object validity; retain source identity and freshness checks.";

CM_ SG_ 220 Object1LateralEstimate "Metric estimate from lane-width and image-ground-contact calibration; not independently surveyed or OEM confirmed. Encoding unchanged; raw values remain available with scaling disabled. Position or velocity does not independently establish object validity; retain source identity and freshness checks.";

CM_ SG_ 220 Object1RelativeLateralVelocityEstimate "Metric estimate from lane-width and image-ground-contact calibration; not independently surveyed or OEM confirmed. Encoding unchanged; raw values remain available with scaling disabled. Position or velocity does not independently establish object validity; retain source identity and freshness checks. Raw -256/+255 endpoints excluded from numeric extrapolation; exact sentinel semantics unverified.";

CM_ SG_ 221 OuterRightLaneCandidateOffsetEstimate "Metric estimate from lane-width and image-ground-contact calibration; not independently surveyed or OEM confirmed. Encoding unchanged; raw values remain available with scaling disabled. Apply freshness/activity and geometry checks; offset alone does not establish a valid boundary.";

CM_ SG_ 221 OuterRightLaneCandidateRangeEndEstimate "Metric estimate from lane-width and image-ground-contact calibration; not independently surveyed or OEM confirmed. Encoding unchanged; raw values remain available with scaling disabled. Boundary endpoint: activity zero retains old values; 127 may be a range ceiling.";

CM_ SG_ 221 OuterRightLaneCandidateRangeStartEstimate "Metric estimate from lane-width and image-ground-contact calibration; not independently surveyed or OEM confirmed. Encoding unchanged; raw values remain available with scaling disabled. Boundary endpoint: activity zero retains old values; 127 may be a range ceiling.";

CM_ SG_ 221 Object0LongitudinalEstimate "Metric estimate from lane-width and image-ground-contact calibration; not independently surveyed or OEM confirmed. Encoding unchanged; raw values remain available with scaling disabled. Position or velocity does not independently establish object validity; retain source identity and freshness checks.";

CM_ SG_ 221 Object0RelativeLongitudinalVelocityEstimate "Metric estimate from lane-width and image-ground-contact calibration; not independently surveyed or OEM confirmed. Encoding unchanged; raw values remain available with scaling disabled. Position or velocity does not independently establish object validity; retain source identity and freshness checks.";

CM_ SG_ 221 Object0LateralEstimate "Metric estimate from lane-width and image-ground-contact calibration; not independently surveyed or OEM confirmed. Encoding unchanged; raw values remain available with scaling disabled. Position or velocity does not independently establish object validity; retain source identity and freshness checks.";

CM_ SG_ 221 Object0RelativeLateralVelocityEstimate "Metric estimate from lane-width and image-ground-contact calibration; not independently surveyed or OEM confirmed. Encoding unchanged; raw values remain available with scaling disabled. Position or velocity does not independently establish object validity; retain source identity and freshness checks. Raw -256/+255 endpoints excluded from numeric extrapolation; exact sentinel semantics unverified.";

CM_ SG_ 222 RightLaneOffsetEstimate "Metric estimate from lane-width and image-ground-contact calibration; not independently surveyed or OEM confirmed. Encoding unchanged; raw values remain available with scaling disabled. Apply freshness/activity and geometry checks; offset alone does not establish a valid boundary.";

CM_ SG_ 222 RightLaneRangeEndEstimate "Metric estimate from lane-width and image-ground-contact calibration; not independently surveyed or OEM confirmed. Encoding unchanged; raw values remain available with scaling disabled. Boundary endpoint: activity zero retains old values; 127 may be a range ceiling.";

CM_ SG_ 222 RightLaneRangeStartEstimate "Metric estimate from lane-width and image-ground-contact calibration; not independently surveyed or OEM confirmed. Encoding unchanged; raw values remain available with scaling disabled. Boundary endpoint: activity zero retains old values; 127 may be a range ceiling.";

CM_ SG_ 222 Object0LongitudinalEstimate "Metric estimate from lane-width and image-ground-contact calibration; not independently surveyed or OEM confirmed. Encoding unchanged; raw values remain available with scaling disabled. Position or velocity does not independently establish object validity; retain source identity and freshness checks.";

CM_ SG_ 222 Object0RelativeLongitudinalVelocityEstimate "Metric estimate from lane-width and image-ground-contact calibration; not independently surveyed or OEM confirmed. Encoding unchanged; raw values remain available with scaling disabled. Position or velocity does not independently establish object validity; retain source identity and freshness checks.";

CM_ SG_ 222 Object0LateralEstimate "Metric estimate from lane-width and image-ground-contact calibration; not independently surveyed or OEM confirmed. Encoding unchanged; raw values remain available with scaling disabled. Position or velocity does not independently establish object validity; retain source identity and freshness checks.";

CM_ SG_ 222 Object0RelativeLateralVelocityEstimate "Metric estimate from lane-width and image-ground-contact calibration; not independently surveyed or OEM confirmed. Encoding unchanged; raw values remain available with scaling disabled. Position or velocity does not independently establish object validity; retain source identity and freshness checks. Raw -256/+255 endpoints excluded from numeric extrapolation; exact sentinel semantics unverified.";

CM_ SG_ 233 LeftLaneOffsetEstimate "Metric estimate from lane-width and image-ground-contact calibration; not independently surveyed or OEM confirmed. Encoding unchanged; raw values remain available with scaling disabled. Apply freshness/activity and geometry checks; offset alone does not establish a valid boundary.";

CM_ SG_ 233 LeftLaneRangeEndEstimate "Metric estimate from lane-width and image-ground-contact calibration; not independently surveyed or OEM confirmed. Encoding unchanged; raw values remain available with scaling disabled. Boundary endpoint: activity zero retains old values; 127 may be a range ceiling.";

CM_ SG_ 233 LeftLaneRangeStartEstimate "Metric estimate from lane-width and image-ground-contact calibration; not independently surveyed or OEM confirmed. Encoding unchanged; raw values remain available with scaling disabled. Boundary endpoint: activity zero retains old values; 127 may be a range ceiling.";

CM_ SG_ 233 Object0LongitudinalEstimate "Metric estimate from lane-width and image-ground-contact calibration; not independently surveyed or OEM confirmed. Encoding unchanged; raw values remain available with scaling disabled. Position or velocity does not independently establish object validity; retain source identity and freshness checks.";

CM_ SG_ 233 Object0RelativeLongitudinalVelocityEstimate "Metric estimate from lane-width and image-ground-contact calibration; not independently surveyed or OEM confirmed. Encoding unchanged; raw values remain available with scaling disabled. Position or velocity does not independently establish object validity; retain source identity and freshness checks.";

CM_ SG_ 233 Object0LateralEstimate "Metric estimate from lane-width and image-ground-contact calibration; not independently surveyed or OEM confirmed. Encoding unchanged; raw values remain available with scaling disabled. Position or velocity does not independently establish object validity; retain source identity and freshness checks.";

CM_ SG_ 233 Object0RelativeLateralVelocityEstimate "Metric estimate from lane-width and image-ground-contact calibration; not independently surveyed or OEM confirmed. Encoding unchanged; raw values remain available with scaling disabled. Position or velocity does not independently establish object validity; retain source identity and freshness checks. Raw -256/+255 endpoints excluded from numeric extrapolation; exact sentinel semantics unverified.";

CM_ SG_ 234 OuterLeftLaneCandidateOffsetEstimate "Metric estimate from lane-width and image-ground-contact calibration; not independently surveyed or OEM confirmed. Encoding unchanged; raw values remain available with scaling disabled. Apply freshness/activity and geometry checks; offset alone does not establish a valid boundary.";

CM_ SG_ 234 OuterLeftLaneCandidateRangeEndEstimate "Metric estimate from lane-width and image-ground-contact calibration; not independently surveyed or OEM confirmed. Encoding unchanged; raw values remain available with scaling disabled. Boundary endpoint: activity zero retains old values; 127 may be a range ceiling.";

CM_ SG_ 234 OuterLeftLaneCandidateRangeStartEstimate "Metric estimate from lane-width and image-ground-contact calibration; not independently surveyed or OEM confirmed. Encoding unchanged; raw values remain available with scaling disabled. Boundary endpoint: activity zero retains old values; 127 may be a range ceiling.";

CM_ SG_ 234 Object0LongitudinalEstimate "Metric estimate from lane-width and image-ground-contact calibration; not independently surveyed or OEM confirmed. Encoding unchanged; raw values remain available with scaling disabled. Position or velocity does not independently establish object validity; retain source identity and freshness checks.";

CM_ SG_ 234 Object0RelativeLongitudinalVelocityEstimate "Metric estimate from lane-width and image-ground-contact calibration; not independently surveyed or OEM confirmed. Encoding unchanged; raw values remain available with scaling disabled. Position or velocity does not independently establish object validity; retain source identity and freshness checks.";

CM_ SG_ 234 Object0LateralEstimate "Metric estimate from lane-width and image-ground-contact calibration; not independently surveyed or OEM confirmed. Encoding unchanged; raw values remain available with scaling disabled. Position or velocity does not independently establish object validity; retain source identity and freshness checks.";

CM_ SG_ 234 Object0RelativeLateralVelocityEstimate "Metric estimate from lane-width and image-ground-contact calibration; not independently surveyed or OEM confirmed. Encoding unchanged; raw values remain available with scaling disabled. Position or velocity does not independently establish object validity; retain source identity and freshness checks. Raw -256/+255 endpoints excluded from numeric extrapolation; exact sentinel semantics unverified.";

CM_ SG_ 235 LeftSecondaryBoundaryCandidateOffsetEstimate "Metric estimate from lane-width and image-ground-contact calibration; not independently surveyed or OEM confirmed. Encoding unchanged; raw values remain available with scaling disabled. Apply freshness/activity and geometry checks; offset alone does not establish a valid boundary.";

CM_ SG_ 235 LeftSecondaryBoundaryCandidateRangeEndEstimate "Metric estimate from lane-width and image-ground-contact calibration; not independently surveyed or OEM confirmed. Encoding unchanged; raw values remain available with scaling disabled. Boundary endpoint: activity zero retains old values; 127 may be a range ceiling.";

CM_ SG_ 235 LeftSecondaryBoundaryCandidateRangeStartEstimate "Metric estimate from lane-width and image-ground-contact calibration; not independently surveyed or OEM confirmed. Encoding unchanged; raw values remain available with scaling disabled. Boundary endpoint: activity zero retains old values; 127 may be a range ceiling.";

CM_ SG_ 235 Object0LongitudinalEstimate "Metric estimate from lane-width and image-ground-contact calibration; not independently surveyed or OEM confirmed. Encoding unchanged; raw values remain available with scaling disabled. Position or velocity does not independently establish object validity; retain source identity and freshness checks.";

CM_ SG_ 235 Object0RelativeLongitudinalVelocityEstimate "Metric estimate from lane-width and image-ground-contact calibration; not independently surveyed or OEM confirmed. Encoding unchanged; raw values remain available with scaling disabled. Position or velocity does not independently establish object validity; retain source identity and freshness checks.";

CM_ SG_ 235 Object0LateralEstimate "Metric estimate from lane-width and image-ground-contact calibration; not independently surveyed or OEM confirmed. Encoding unchanged; raw values remain available with scaling disabled. Position or velocity does not independently establish object validity; retain source identity and freshness checks.";

CM_ SG_ 235 Object0RelativeLateralVelocityEstimate "Metric estimate from lane-width and image-ground-contact calibration; not independently surveyed or OEM confirmed. Encoding unchanged; raw values remain available with scaling disabled. Position or velocity does not independently establish object validity; retain source identity and freshness checks. Raw -256/+255 endpoints excluded from numeric extrapolation; exact sentinel semantics unverified.";

CM_ SG_ 236 LeftRoadEdgeCandidateOffsetEstimate "Metric estimate from lane-width and image-ground-contact calibration; not independently surveyed or OEM confirmed. Encoding unchanged; raw values remain available with scaling disabled. Apply freshness/activity and geometry checks; offset alone does not establish a valid boundary.";

CM_ SG_ 236 LeftRoadEdgeCandidateRangeEndEstimate "Metric estimate from lane-width and image-ground-contact calibration; not independently surveyed or OEM confirmed. Encoding unchanged; raw values remain available with scaling disabled. Boundary endpoint: activity zero retains old values; 127 may be a range ceiling.";

CM_ SG_ 236 LeftRoadEdgeCandidateRangeStartEstimate "Metric estimate from lane-width and image-ground-contact calibration; not independently surveyed or OEM confirmed. Encoding unchanged; raw values remain available with scaling disabled. Boundary endpoint: activity zero retains old values; 127 may be a range ceiling.";

CM_ SG_ 236 Object0LongitudinalEstimate "Metric estimate from lane-width and image-ground-contact calibration; not independently surveyed or OEM confirmed. Encoding unchanged; raw values remain available with scaling disabled. Position or velocity does not independently establish object validity; retain source identity and freshness checks.";

CM_ SG_ 236 Object0RelativeLongitudinalVelocityEstimate "Metric estimate from lane-width and image-ground-contact calibration; not independently surveyed or OEM confirmed. Encoding unchanged; raw values remain available with scaling disabled. Position or velocity does not independently establish object validity; retain source identity and freshness checks.";

CM_ SG_ 236 Object0LateralEstimate "Metric estimate from lane-width and image-ground-contact calibration; not independently surveyed or OEM confirmed. Encoding unchanged; raw values remain available with scaling disabled. Position or velocity does not independently establish object validity; retain source identity and freshness checks.";

CM_ SG_ 236 Object0RelativeLateralVelocityEstimate "Metric estimate from lane-width and image-ground-contact calibration; not independently surveyed or OEM confirmed. Encoding unchanged; raw values remain available with scaling disabled. Position or velocity does not independently establish object validity; retain source identity and freshness checks. Raw -256/+255 endpoints excluded from numeric extrapolation; exact sentinel semantics unverified.";

CM_ SG_ 204 LaneOffsetEstimate "Metric estimate from lane-width and image-ground-contact calibration; not independently surveyed or OEM confirmed. Encoding unchanged; raw values remain available with scaling disabled. Apply freshness/activity and geometry checks; offset alone does not establish a valid boundary.";

CM_ SG_ 206 LaneOffsetEstimate "Metric estimate from lane-width and image-ground-contact calibration; not independently surveyed or OEM confirmed. Encoding unchanged; raw values remain available with scaling disabled. Apply freshness/activity and geometry checks; offset alone does not establish a valid boundary.";

CM_ SG_ 237 LeftBoundaryCandidateOffsetEstimate "Metric estimate from lane-width and image-ground-contact calibration; not independently surveyed or OEM confirmed. Encoding unchanged; raw values remain available with scaling disabled. Apply freshness/activity and geometry checks; offset alone does not establish a valid boundary.";

CM_ SG_ 237 RightBoundaryCandidateOffsetEstimate "Metric estimate from lane-width and image-ground-contact calibration; not independently surveyed or OEM confirmed. Encoding unchanged; raw values remain available with scaling disabled. Apply freshness/activity and geometry checks; offset alone does not establish a valid boundary.";

CM_ SG_ 237 CenterCandidateOffsetEstimate "Metric estimate from lane-width and image-ground-contact calibration; not independently surveyed or OEM confirmed. Encoding unchanged; raw values remain available with scaling disabled. Apply freshness/activity and geometry checks; offset alone does not establish a valid boundary.";

CM_ SG_ 237 CenterCopyCandidateOffsetEstimate "Metric estimate from lane-width and image-ground-contact calibration; not independently surveyed or OEM confirmed. Encoding unchanged; raw values remain available with scaling disabled. Apply freshness/activity and geometry checks; offset alone does not establish a valid boundary.";

CM_ SG_ 213 Slot14LongitudinalEstimate "Metric estimate from lane-width and image-ground-contact calibration; not independently surveyed or OEM confirmed. Encoding unchanged; raw values remain available with scaling disabled. Position or velocity does not independently establish object validity; retain source identity and freshness checks.";

CM_ SG_ 213 Slot14LateralEstimate "Metric estimate from lane-width and image-ground-contact calibration; not independently surveyed or OEM confirmed. Encoding unchanged; raw values remain available with scaling disabled. Position or velocity does not independently establish object validity; retain source identity and freshness checks.";

CM_ SG_ 213 Slot16LongitudinalEstimate "Metric estimate from lane-width and image-ground-contact calibration; not independently surveyed or OEM confirmed. Encoding unchanged; raw values remain available with scaling disabled. Position or velocity does not independently establish object validity; retain source identity and freshness checks.";

CM_ SG_ 213 Slot16LateralEstimate "Metric estimate from lane-width and image-ground-contact calibration; not independently surveyed or OEM confirmed. Encoding unchanged; raw values remain available with scaling disabled. Position or velocity does not independently establish object validity; retain source identity and freshness checks.";

CM_ SG_ 213 Slot17LongitudinalEstimate "Metric estimate from lane-width and image-ground-contact calibration; not independently surveyed or OEM confirmed. Encoding unchanged; raw values remain available with scaling disabled. Position or velocity does not independently establish object validity; retain source identity and freshness checks.";

CM_ SG_ 213 Slot17LateralEstimate "Metric estimate from lane-width and image-ground-contact calibration; not independently surveyed or OEM confirmed. Encoding unchanged; raw values remain available with scaling disabled. Position or velocity does not independently establish object validity; retain source identity and freshness checks.";

CM_ SG_ 213 Slot18LongitudinalEstimate "Metric estimate from lane-width and image-ground-contact calibration; not independently surveyed or OEM confirmed. Encoding unchanged; raw values remain available with scaling disabled. Position or velocity does not independently establish object validity; retain source identity and freshness checks.";

CM_ SG_ 213 Slot18LateralEstimate "Metric estimate from lane-width and image-ground-contact calibration; not independently surveyed or OEM confirmed. Encoding unchanged; raw values remain available with scaling disabled. Position or velocity does not independently establish object validity; retain source identity and freshness checks.";

CM_ SG_ 210 Object0LongitudinalEstimate "Metric estimate from lane-width and image-ground-contact calibration; not independently surveyed or OEM confirmed. Encoding unchanged; raw values remain available with scaling disabled. Position or velocity does not independently establish object validity; retain source identity and freshness checks.";

CM_ SG_ 210 Object0LateralEstimate "Metric estimate from lane-width and image-ground-contact calibration; not independently surveyed or OEM confirmed. Encoding unchanged; raw values remain available with scaling disabled. Position or velocity does not independently establish object validity; retain source identity and freshness checks.";

CM_ SG_ 210 Object1LongitudinalEstimate "Metric estimate from lane-width and image-ground-contact calibration; not independently surveyed or OEM confirmed. Encoding unchanged; raw values remain available with scaling disabled. Position or velocity does not independently establish object validity; retain source identity and freshness checks.";

CM_ SG_ 210 Object1LateralEstimate "Metric estimate from lane-width and image-ground-contact calibration; not independently surveyed or OEM confirmed. Encoding unchanged; raw values remain available with scaling disabled. Position or velocity does not independently establish object validity; retain source identity and freshness checks.";

CM_ SG_ 210 Object2LongitudinalEstimate "Metric estimate from lane-width and image-ground-contact calibration; not independently surveyed or OEM confirmed. Encoding unchanged; raw values remain available with scaling disabled. Position or velocity does not independently establish object validity; retain source identity and freshness checks.";

CM_ SG_ 210 Object2LateralEstimate "Metric estimate from lane-width and image-ground-contact calibration; not independently surveyed or OEM confirmed. Encoding unchanged; raw values remain available with scaling disabled. Position or velocity does not independently establish object validity; retain source identity and freshness checks.";

CM_ SG_ 210 Object3LongitudinalEstimate "Metric estimate from lane-width and image-ground-contact calibration; not independently surveyed or OEM confirmed. Encoding unchanged; raw values remain available with scaling disabled. Position or velocity does not independently establish object validity; retain source identity and freshness checks.";

CM_ SG_ 210 Object3LateralEstimate "Metric estimate from lane-width and image-ground-contact calibration; not independently surveyed or OEM confirmed. Encoding unchanged; raw values remain available with scaling disabled. Position or velocity does not independently establish object validity; retain source identity and freshness checks.";

CM_ SG_ 210 Object4LongitudinalEstimate "Metric estimate from lane-width and image-ground-contact calibration; not independently surveyed or OEM confirmed. Encoding unchanged; raw values remain available with scaling disabled. Position or velocity does not independently establish object validity; retain source identity and freshness checks.";

CM_ SG_ 210 Object4LateralEstimate "Metric estimate from lane-width and image-ground-contact calibration; not independently surveyed or OEM confirmed. Encoding unchanged; raw values remain available with scaling disabled. Position or velocity does not independently establish object validity; retain source identity and freshness checks.";

CM_ SG_ 210 Object5LongitudinalEstimate "Metric estimate from lane-width and image-ground-contact calibration; not independently surveyed or OEM confirmed. Encoding unchanged; raw values remain available with scaling disabled. Position or velocity does not independently establish object validity; retain source identity and freshness checks.";

CM_ SG_ 210 Object5LateralEstimate "Metric estimate from lane-width and image-ground-contact calibration; not independently surveyed or OEM confirmed. Encoding unchanged; raw values remain available with scaling disabled. Position or velocity does not independently establish object validity; retain source identity and freshness checks.";

CM_ SG_ 210 Object6LongitudinalEstimate "Metric estimate from lane-width and image-ground-contact calibration; not independently surveyed or OEM confirmed. Encoding unchanged; raw values remain available with scaling disabled. Position or velocity does not independently establish object validity; retain source identity and freshness checks.";

CM_ SG_ 210 Object6LateralEstimate "Metric estimate from lane-width and image-ground-contact calibration; not independently surveyed or OEM confirmed. Encoding unchanged; raw values remain available with scaling disabled. Position or velocity does not independently establish object validity; retain source identity and freshness checks.";

CM_ SG_ 210 Object7LongitudinalEstimate "Metric estimate from lane-width and image-ground-contact calibration; not independently surveyed or OEM confirmed. Encoding unchanged; raw values remain available with scaling disabled. Position or velocity does not independently establish object validity; retain source identity and freshness checks.";

CM_ SG_ 210 Object7LateralEstimate "Metric estimate from lane-width and image-ground-contact calibration; not independently surveyed or OEM confirmed. Encoding unchanged; raw values remain available with scaling disabled. Position or velocity does not independently establish object validity; retain source identity and freshness checks.";

CM_ SG_ 210 Object8LongitudinalEstimate "Metric estimate from lane-width and image-ground-contact calibration; not independently surveyed or OEM confirmed. Encoding unchanged; raw values remain available with scaling disabled. Position or velocity does not independently establish object validity; retain source identity and freshness checks.";

CM_ SG_ 210 Object8LateralEstimate "Metric estimate from lane-width and image-ground-contact calibration; not independently surveyed or OEM confirmed. Encoding unchanged; raw values remain available with scaling disabled. Position or velocity does not independently establish object validity; retain source identity and freshness checks.";

CM_ SG_ 207 Object0LongitudinalEstimate "Metric estimate from lane-width and image-ground-contact calibration; not independently surveyed or OEM confirmed. Encoding unchanged; raw values remain available with scaling disabled. Position or velocity does not independently establish object validity; retain source identity and freshness checks.";

CM_ SG_ 207 Object0LateralEstimate "Metric estimate from lane-width and image-ground-contact calibration; not independently surveyed or OEM confirmed. Encoding unchanged; raw values remain available with scaling disabled. Position or velocity does not independently establish object validity; retain source identity and freshness checks.";

CM_ SG_ 207 Object1LongitudinalEstimate "Metric estimate from lane-width and image-ground-contact calibration; not independently surveyed or OEM confirmed. Encoding unchanged; raw values remain available with scaling disabled. Position or velocity does not independently establish object validity; retain source identity and freshness checks.";

CM_ SG_ 207 Object1LateralEstimate "Metric estimate from lane-width and image-ground-contact calibration; not independently surveyed or OEM confirmed. Encoding unchanged; raw values remain available with scaling disabled. Position or velocity does not independently establish object validity; retain source identity and freshness checks.";

CM_ SG_ 207 Object2LongitudinalEstimate "Metric estimate from lane-width and image-ground-contact calibration; not independently surveyed or OEM confirmed. Encoding unchanged; raw values remain available with scaling disabled. Position or velocity does not independently establish object validity; retain source identity and freshness checks.";

CM_ SG_ 207 Object2LateralEstimate "Metric estimate from lane-width and image-ground-contact calibration; not independently surveyed or OEM confirmed. Encoding unchanged; raw values remain available with scaling disabled. Position or velocity does not independently establish object validity; retain source identity and freshness checks.";

CM_ SG_ 207 Object3LongitudinalEstimate "Metric estimate from lane-width and image-ground-contact calibration; not independently surveyed or OEM confirmed. Encoding unchanged; raw values remain available with scaling disabled. Position or velocity does not independently establish object validity; retain source identity and freshness checks.";

CM_ SG_ 207 Object3LateralEstimate "Metric estimate from lane-width and image-ground-contact calibration; not independently surveyed or OEM confirmed. Encoding unchanged; raw values remain available with scaling disabled. Position or velocity does not independently establish object validity; retain source identity and freshness checks.";

CM_ SG_ 207 Object4LongitudinalEstimate "Metric estimate from lane-width and image-ground-contact calibration; not independently surveyed or OEM confirmed. Encoding unchanged; raw values remain available with scaling disabled. Position or velocity does not independently establish object validity; retain source identity and freshness checks.";

CM_ SG_ 207 Object4LateralEstimate "Metric estimate from lane-width and image-ground-contact calibration; not independently surveyed or OEM confirmed. Encoding unchanged; raw values remain available with scaling disabled. Position or velocity does not independently establish object validity; retain source identity and freshness checks.";

CM_ SG_ 207 Object5LongitudinalEstimate "Metric estimate from lane-width and image-ground-contact calibration; not independently surveyed or OEM confirmed. Encoding unchanged; raw values remain available with scaling disabled. Position or velocity does not independently establish object validity; retain source identity and freshness checks.";

CM_ SG_ 207 Object5LateralEstimate "Metric estimate from lane-width and image-ground-contact calibration; not independently surveyed or OEM confirmed. Encoding unchanged; raw values remain available with scaling disabled. Position or velocity does not independently establish object validity; retain source identity and freshness checks.";

CM_ SG_ 207 Object6LongitudinalEstimate "Metric estimate from lane-width and image-ground-contact calibration; not independently surveyed or OEM confirmed. Encoding unchanged; raw values remain available with scaling disabled. Position or velocity does not independently establish object validity; retain source identity and freshness checks.";

CM_ SG_ 207 Object6LateralEstimate "Metric estimate from lane-width and image-ground-contact calibration; not independently surveyed or OEM confirmed. Encoding unchanged; raw values remain available with scaling disabled. Position or velocity does not independently establish object validity; retain source identity and freshness checks.";

CM_ SG_ 207 Object7LongitudinalEstimate "Metric estimate from lane-width and image-ground-contact calibration; not independently surveyed or OEM confirmed. Encoding unchanged; raw values remain available with scaling disabled. Position or velocity does not independently establish object validity; retain source identity and freshness checks.";

CM_ SG_ 207 Object7LateralEstimate "Metric estimate from lane-width and image-ground-contact calibration; not independently surveyed or OEM confirmed. Encoding unchanged; raw values remain available with scaling disabled. Position or velocity does not independently establish object validity; retain source identity and freshness checks.";

CM_ SG_ 207 Object8LongitudinalEstimate "Metric estimate from lane-width and image-ground-contact calibration; not independently surveyed or OEM confirmed. Encoding unchanged; raw values remain available with scaling disabled. Position or velocity does not independently establish object validity; retain source identity and freshness checks.";

CM_ SG_ 207 Object8LateralEstimate "Metric estimate from lane-width and image-ground-contact calibration; not independently surveyed or OEM confirmed. Encoding unchanged; raw values remain available with scaling disabled. Position or velocity does not independently establish object validity; retain source identity and freshness checks.";

CM_ SG_ 517 Object0LongitudinalEstimate "Metric estimate from lane-width and image-ground-contact calibration; not independently surveyed or OEM confirmed. Encoding unchanged; raw values remain available with scaling disabled. Position or velocity does not independently establish object validity; retain source identity and freshness checks.";

CM_ SG_ 517 Object0LateralEstimate "Metric estimate from lane-width and image-ground-contact calibration; not independently surveyed or OEM confirmed. Encoding unchanged; raw values remain available with scaling disabled. Position or velocity does not independently establish object validity; retain source identity and freshness checks.";

CM_ SG_ 517 Object1LongitudinalEstimate "Metric estimate from lane-width and image-ground-contact calibration; not independently surveyed or OEM confirmed. Encoding unchanged; raw values remain available with scaling disabled. Position or velocity does not independently establish object validity; retain source identity and freshness checks.";

CM_ SG_ 517 Object1LateralEstimate "Metric estimate from lane-width and image-ground-contact calibration; not independently surveyed or OEM confirmed. Encoding unchanged; raw values remain available with scaling disabled. Position or velocity does not independently establish object validity; retain source identity and freshness checks.";

CM_ SG_ 517 Object2LongitudinalEstimate "Metric estimate from lane-width and image-ground-contact calibration; not independently surveyed or OEM confirmed. Encoding unchanged; raw values remain available with scaling disabled. Position or velocity does not independently establish object validity; retain source identity and freshness checks.";

CM_ SG_ 517 Object2LateralEstimate "Metric estimate from lane-width and image-ground-contact calibration; not independently surveyed or OEM confirmed. Encoding unchanged; raw values remain available with scaling disabled. Position or velocity does not independently establish object validity; retain source identity and freshness checks.";

CM_ SG_ 517 Object3LongitudinalEstimate "Metric estimate from lane-width and image-ground-contact calibration; not independently surveyed or OEM confirmed. Encoding unchanged; raw values remain available with scaling disabled. Position or velocity does not independently establish object validity; retain source identity and freshness checks.";

CM_ SG_ 517 Object3LateralEstimate "Metric estimate from lane-width and image-ground-contact calibration; not independently surveyed or OEM confirmed. Encoding unchanged; raw values remain available with scaling disabled. Position or velocity does not independently establish object validity; retain source identity and freshness checks.";

CM_ SG_ 517 Object4LongitudinalEstimate "Metric estimate from lane-width and image-ground-contact calibration; not independently surveyed or OEM confirmed. Encoding unchanged; raw values remain available with scaling disabled. Position or velocity does not independently establish object validity; retain source identity and freshness checks.";

CM_ SG_ 517 Object4LateralEstimate "Metric estimate from lane-width and image-ground-contact calibration; not independently surveyed or OEM confirmed. Encoding unchanged; raw values remain available with scaling disabled. Position or velocity does not independently establish object validity; retain source identity and freshness checks.";

CM_ SG_ 517 Object5LongitudinalEstimate "Metric estimate from lane-width and image-ground-contact calibration; not independently surveyed or OEM confirmed. Encoding unchanged; raw values remain available with scaling disabled. Position or velocity does not independently establish object validity; retain source identity and freshness checks.";

CM_ SG_ 517 Object5LateralEstimate "Metric estimate from lane-width and image-ground-contact calibration; not independently surveyed or OEM confirmed. Encoding unchanged; raw values remain available with scaling disabled. Position or velocity does not independently establish object validity; retain source identity and freshness checks.";

CM_ SG_ 517 Object6LongitudinalEstimate "Metric estimate from lane-width and image-ground-contact calibration; not independently surveyed or OEM confirmed. Encoding unchanged; raw values remain available with scaling disabled. Position or velocity does not independently establish object validity; retain source identity and freshness checks.";

CM_ SG_ 517 Object6LateralEstimate "Metric estimate from lane-width and image-ground-contact calibration; not independently surveyed or OEM confirmed. Encoding unchanged; raw values remain available with scaling disabled. Position or velocity does not independently establish object validity; retain source identity and freshness checks.";

CM_ SG_ 517 Object7LongitudinalEstimate "Metric estimate from lane-width and image-ground-contact calibration; not independently surveyed or OEM confirmed. Encoding unchanged; raw values remain available with scaling disabled. Position or velocity does not independently establish object validity; retain source identity and freshness checks.";

CM_ SG_ 517 Object7LateralEstimate "Metric estimate from lane-width and image-ground-contact calibration; not independently surveyed or OEM confirmed. Encoding unchanged; raw values remain available with scaling disabled. Position or velocity does not independently establish object validity; retain source identity and freshness checks.";

CM_ SG_ 517 Object8LongitudinalEstimate "Metric estimate from lane-width and image-ground-contact calibration; not independently surveyed or OEM confirmed. Encoding unchanged; raw values remain available with scaling disabled. Position or velocity does not independently establish object validity; retain source identity and freshness checks.";

CM_ SG_ 517 Object8LateralEstimate "Metric estimate from lane-width and image-ground-contact calibration; not independently surveyed or OEM confirmed. Encoding unchanged; raw values remain available with scaling disabled. Position or velocity does not independently establish object validity; retain source identity and freshness checks.";

CM_ SG_ 190 Object0LongitudinalEstimate "Metric estimate from lane-width and image-ground-contact calibration; not independently surveyed or OEM confirmed. Encoding unchanged; raw values remain available with scaling disabled. Position or velocity does not independently establish object validity; retain source identity and freshness checks.";

CM_ SG_ 190 Object0LateralEstimate "Metric estimate from lane-width and image-ground-contact calibration; not independently surveyed or OEM confirmed. Encoding unchanged; raw values remain available with scaling disabled. Position or velocity does not independently establish object validity; retain source identity and freshness checks.";

CM_ SG_ 190 Object1LongitudinalEstimate "Metric estimate from lane-width and image-ground-contact calibration; not independently surveyed or OEM confirmed. Encoding unchanged; raw values remain available with scaling disabled. Position or velocity does not independently establish object validity; retain source identity and freshness checks.";

CM_ SG_ 190 Object1LateralEstimate "Metric estimate from lane-width and image-ground-contact calibration; not independently surveyed or OEM confirmed. Encoding unchanged; raw values remain available with scaling disabled. Position or velocity does not independently establish object validity; retain source identity and freshness checks.";

CM_ SG_ 190 Object2LongitudinalEstimate "Metric estimate from lane-width and image-ground-contact calibration; not independently surveyed or OEM confirmed. Encoding unchanged; raw values remain available with scaling disabled. Position or velocity does not independently establish object validity; retain source identity and freshness checks.";

CM_ SG_ 190 Object2LateralEstimate "Metric estimate from lane-width and image-ground-contact calibration; not independently surveyed or OEM confirmed. Encoding unchanged; raw values remain available with scaling disabled. Position or velocity does not independently establish object validity; retain source identity and freshness checks.";

CM_ SG_ 190 Object3LongitudinalEstimate "Metric estimate from lane-width and image-ground-contact calibration; not independently surveyed or OEM confirmed. Encoding unchanged; raw values remain available with scaling disabled. Position or velocity does not independently establish object validity; retain source identity and freshness checks.";

CM_ SG_ 190 Object3LateralEstimate "Metric estimate from lane-width and image-ground-contact calibration; not independently surveyed or OEM confirmed. Encoding unchanged; raw values remain available with scaling disabled. Position or velocity does not independently establish object validity; retain source identity and freshness checks.";

CM_ SG_ 190 Object4LongitudinalEstimate "Metric estimate from lane-width and image-ground-contact calibration; not independently surveyed or OEM confirmed. Encoding unchanged; raw values remain available with scaling disabled. Position or velocity does not independently establish object validity; retain source identity and freshness checks.";

CM_ SG_ 190 Object4LateralEstimate "Metric estimate from lane-width and image-ground-contact calibration; not independently surveyed or OEM confirmed. Encoding unchanged; raw values remain available with scaling disabled. Position or velocity does not independently establish object validity; retain source identity and freshness checks.";

CM_ SG_ 190 Object5LongitudinalEstimate "Metric estimate from lane-width and image-ground-contact calibration; not independently surveyed or OEM confirmed. Encoding unchanged; raw values remain available with scaling disabled. Position or velocity does not independently establish object validity; retain source identity and freshness checks.";

CM_ SG_ 190 Object5LateralEstimate "Metric estimate from lane-width and image-ground-contact calibration; not independently surveyed or OEM confirmed. Encoding unchanged; raw values remain available with scaling disabled. Position or velocity does not independently establish object validity; retain source identity and freshness checks.";

CM_ SG_ 190 Object6LongitudinalEstimate "Metric estimate from lane-width and image-ground-contact calibration; not independently surveyed or OEM confirmed. Encoding unchanged; raw values remain available with scaling disabled. Position or velocity does not independently establish object validity; retain source identity and freshness checks.";

CM_ SG_ 190 Object6LateralEstimate "Metric estimate from lane-width and image-ground-contact calibration; not independently surveyed or OEM confirmed. Encoding unchanged; raw values remain available with scaling disabled. Position or velocity does not independently establish object validity; retain source identity and freshness checks.";

CM_ SG_ 190 Object7LongitudinalEstimate "Metric estimate from lane-width and image-ground-contact calibration; not independently surveyed or OEM confirmed. Encoding unchanged; raw values remain available with scaling disabled. Position or velocity does not independently establish object validity; retain source identity and freshness checks.";

CM_ SG_ 190 Object7LateralEstimate "Metric estimate from lane-width and image-ground-contact calibration; not independently surveyed or OEM confirmed. Encoding unchanged; raw values remain available with scaling disabled. Position or velocity does not independently establish object validity; retain source identity and freshness checks.";

CM_ SG_ 190 Object8LongitudinalEstimate "Metric estimate from lane-width and image-ground-contact calibration; not independently surveyed or OEM confirmed. Encoding unchanged; raw values remain available with scaling disabled. Position or velocity does not independently establish object validity; retain source identity and freshness checks.";

CM_ SG_ 190 Object8LateralEstimate "Metric estimate from lane-width and image-ground-contact calibration; not independently surveyed or OEM confirmed. Encoding unchanged; raw values remain available with scaling disabled. Position or velocity does not independently establish object validity; retain source identity and freshness checks.";

CM_ SG_ 199 Object0LongitudinalEstimate "Metric estimate from lane-width and image-ground-contact calibration; not independently surveyed or OEM confirmed. Encoding unchanged; raw values remain available with scaling disabled. Position or velocity does not independently establish object validity; retain source identity and freshness checks.";

CM_ SG_ 199 Object0LateralEstimate "Metric estimate from lane-width and image-ground-contact calibration; not independently surveyed or OEM confirmed. Encoding unchanged; raw values remain available with scaling disabled. Position or velocity does not independently establish object validity; retain source identity and freshness checks.";

CM_ SG_ 199 Object1LongitudinalEstimate "Metric estimate from lane-width and image-ground-contact calibration; not independently surveyed or OEM confirmed. Encoding unchanged; raw values remain available with scaling disabled. Position or velocity does not independently establish object validity; retain source identity and freshness checks.";

CM_ SG_ 199 Object1LateralEstimate "Metric estimate from lane-width and image-ground-contact calibration; not independently surveyed or OEM confirmed. Encoding unchanged; raw values remain available with scaling disabled. Position or velocity does not independently establish object validity; retain source identity and freshness checks.";

CM_ SG_ 199 Object2LongitudinalEstimate "Metric estimate from lane-width and image-ground-contact calibration; not independently surveyed or OEM confirmed. Encoding unchanged; raw values remain available with scaling disabled. Position or velocity does not independently establish object validity; retain source identity and freshness checks.";

CM_ SG_ 199 Object2LateralEstimate "Metric estimate from lane-width and image-ground-contact calibration; not independently surveyed or OEM confirmed. Encoding unchanged; raw values remain available with scaling disabled. Position or velocity does not independently establish object validity; retain source identity and freshness checks.";

CM_ SG_ 199 Object3LongitudinalEstimate "Metric estimate from lane-width and image-ground-contact calibration; not independently surveyed or OEM confirmed. Encoding unchanged; raw values remain available with scaling disabled. Position or velocity does not independently establish object validity; retain source identity and freshness checks.";

CM_ SG_ 199 Object3LateralEstimate "Metric estimate from lane-width and image-ground-contact calibration; not independently surveyed or OEM confirmed. Encoding unchanged; raw values remain available with scaling disabled. Position or velocity does not independently establish object validity; retain source identity and freshness checks.";

CM_ SG_ 199 Object4LongitudinalEstimate "Metric estimate from lane-width and image-ground-contact calibration; not independently surveyed or OEM confirmed. Encoding unchanged; raw values remain available with scaling disabled. Position or velocity does not independently establish object validity; retain source identity and freshness checks.";

CM_ SG_ 199 Object4LateralEstimate "Metric estimate from lane-width and image-ground-contact calibration; not independently surveyed or OEM confirmed. Encoding unchanged; raw values remain available with scaling disabled. Position or velocity does not independently establish object validity; retain source identity and freshness checks.";

CM_ SG_ 199 Object5LongitudinalEstimate "Metric estimate from lane-width and image-ground-contact calibration; not independently surveyed or OEM confirmed. Encoding unchanged; raw values remain available with scaling disabled. Position or velocity does not independently establish object validity; retain source identity and freshness checks.";

CM_ SG_ 199 Object5LateralEstimate "Metric estimate from lane-width and image-ground-contact calibration; not independently surveyed or OEM confirmed. Encoding unchanged; raw values remain available with scaling disabled. Position or velocity does not independently establish object validity; retain source identity and freshness checks.";

CM_ SG_ 199 Object6LongitudinalEstimate "Metric estimate from lane-width and image-ground-contact calibration; not independently surveyed or OEM confirmed. Encoding unchanged; raw values remain available with scaling disabled. Position or velocity does not independently establish object validity; retain source identity and freshness checks.";

CM_ SG_ 199 Object6LateralEstimate "Metric estimate from lane-width and image-ground-contact calibration; not independently surveyed or OEM confirmed. Encoding unchanged; raw values remain available with scaling disabled. Position or velocity does not independently establish object validity; retain source identity and freshness checks.";

CM_ SG_ 199 Object7LongitudinalEstimate "Metric estimate from lane-width and image-ground-contact calibration; not independently surveyed or OEM confirmed. Encoding unchanged; raw values remain available with scaling disabled. Position or velocity does not independently establish object validity; retain source identity and freshness checks.";

CM_ SG_ 199 Object7LateralEstimate "Metric estimate from lane-width and image-ground-contact calibration; not independently surveyed or OEM confirmed. Encoding unchanged; raw values remain available with scaling disabled. Position or velocity does not independently establish object validity; retain source identity and freshness checks.";

CM_ SG_ 199 Object8LongitudinalEstimate "Metric estimate from lane-width and image-ground-contact calibration; not independently surveyed or OEM confirmed. Encoding unchanged; raw values remain available with scaling disabled. Position or velocity does not independently establish object validity; retain source identity and freshness checks.";

CM_ SG_ 199 Object8LateralEstimate "Metric estimate from lane-width and image-ground-contact calibration; not independently surveyed or OEM confirmed. Encoding unchanged; raw values remain available with scaling disabled. Position or velocity does not independently establish object validity; retain source identity and freshness checks.";

CM_ SG_ 219 Object0OrientationCandidateRaw "FCM object orientation candidate: near zero correlates with forward-facing traffic; near +/-1024 with opposing-facing traffic. Display estimate uses pi/1024 rad/count; exact angular scale, intermediate-angle accuracy and sentinel semantics remain unverified. Require state 2, valid range, freshness and temporal consistency. FCM sensor-fusion provenance unresolved.";

CM_ SG_ 219 Object0StateCandidateRaw "Empirical FCM object-record state: 0 accompanies cleared identity and companion states even when old coordinates remain; 2 accompanies populated records. 1 and 3 unobserved in validation. State 2 alone does not establish object existence: range/sentinel and freshness checks remain necessary. Not an OEM validity enumeration.";

CM_ SG_ 219 Object1OrientationCandidateRaw "FCM object orientation candidate: near zero correlates with forward-facing traffic; near +/-1024 with opposing-facing traffic. Display estimate uses pi/1024 rad/count; exact angular scale, intermediate-angle accuracy and sentinel semantics remain unverified. Require state 2, valid range, freshness and temporal consistency. FCM sensor-fusion provenance unresolved.";

CM_ SG_ 219 Object1StateCandidateRaw "Empirical FCM object-record state: 0 accompanies cleared identity and companion states even when old coordinates remain; 2 accompanies populated records. 1 and 3 unobserved in validation. State 2 alone does not establish object existence: range/sentinel and freshness checks remain necessary. Not an OEM validity enumeration.";

CM_ SG_ 220 Object0OrientationCandidateRaw "FCM object orientation candidate: near zero correlates with forward-facing traffic; near +/-1024 with opposing-facing traffic. Display estimate uses pi/1024 rad/count; exact angular scale, intermediate-angle accuracy and sentinel semantics remain unverified. Require state 2, valid range, freshness and temporal consistency. FCM sensor-fusion provenance unresolved.";

CM_ SG_ 220 Object0StateCandidateRaw "Empirical FCM object-record state: 0 accompanies cleared identity and companion states even when old coordinates remain; 2 accompanies populated records. 1 and 3 unobserved in validation. State 2 alone does not establish object existence: range/sentinel and freshness checks remain necessary. Not an OEM validity enumeration.";

CM_ SG_ 220 Object1OrientationCandidateRaw "FCM object orientation candidate: near zero correlates with forward-facing traffic; near +/-1024 with opposing-facing traffic. Display estimate uses pi/1024 rad/count; exact angular scale, intermediate-angle accuracy and sentinel semantics remain unverified. Require state 2, valid range, freshness and temporal consistency. FCM sensor-fusion provenance unresolved.";

CM_ SG_ 220 Object1StateCandidateRaw "Empirical FCM object-record state: 0 accompanies cleared identity and companion states even when old coordinates remain; 2 accompanies populated records. 1 and 3 unobserved in validation. State 2 alone does not establish object existence: range/sentinel and freshness checks remain necessary. Not an OEM validity enumeration.";

CM_ SG_ 221 Object0OrientationCandidateRaw "FCM object orientation candidate: near zero correlates with forward-facing traffic; near +/-1024 with opposing-facing traffic. Display estimate uses pi/1024 rad/count; exact angular scale, intermediate-angle accuracy and sentinel semantics remain unverified. Require state 2, valid range, freshness and temporal consistency. FCM sensor-fusion provenance unresolved.";

CM_ SG_ 221 Object0StateCandidateRaw "Empirical FCM object-record state: 0 accompanies cleared identity and companion states even when old coordinates remain; 2 accompanies populated records. 1 and 3 unobserved in validation. State 2 alone does not establish object existence: range/sentinel and freshness checks remain necessary. Not an OEM validity enumeration.";

CM_ SG_ 222 Object0OrientationCandidateRaw "FCM object orientation candidate: near zero correlates with forward-facing traffic; near +/-1024 with opposing-facing traffic. Display estimate uses pi/1024 rad/count; exact angular scale, intermediate-angle accuracy and sentinel semantics remain unverified. Require state 2, valid range, freshness and temporal consistency. FCM sensor-fusion provenance unresolved.";

CM_ SG_ 222 Object0StateCandidateRaw "Empirical FCM object-record state: 0 accompanies cleared identity and companion states even when old coordinates remain; 2 accompanies populated records. 1 and 3 unobserved in validation. State 2 alone does not establish object existence: range/sentinel and freshness checks remain necessary. Not an OEM validity enumeration.";

CM_ SG_ 233 Object0OrientationCandidateRaw "FCM object orientation candidate: near zero correlates with forward-facing traffic; near +/-1024 with opposing-facing traffic. Display estimate uses pi/1024 rad/count; exact angular scale, intermediate-angle accuracy and sentinel semantics remain unverified. Require state 2, valid range, freshness and temporal consistency. FCM sensor-fusion provenance unresolved.";

CM_ SG_ 233 Object0StateCandidateRaw "Empirical FCM object-record state: 0 accompanies cleared identity and companion states even when old coordinates remain; 2 accompanies populated records. 1 and 3 unobserved in validation. State 2 alone does not establish object existence: range/sentinel and freshness checks remain necessary. Not an OEM validity enumeration.";

CM_ SG_ 234 Object0OrientationCandidateRaw "FCM object orientation candidate: near zero correlates with forward-facing traffic; near +/-1024 with opposing-facing traffic. Display estimate uses pi/1024 rad/count; exact angular scale, intermediate-angle accuracy and sentinel semantics remain unverified. Require state 2, valid range, freshness and temporal consistency. FCM sensor-fusion provenance unresolved.";

CM_ SG_ 234 Object0StateCandidateRaw "Empirical FCM object-record state: 0 accompanies cleared identity and companion states even when old coordinates remain; 2 accompanies populated records. 1 and 3 unobserved in validation. State 2 alone does not establish object existence: range/sentinel and freshness checks remain necessary. Not an OEM validity enumeration.";

CM_ SG_ 235 Object0OrientationCandidateRaw "FCM object orientation candidate: near zero correlates with forward-facing traffic; near +/-1024 with opposing-facing traffic. Display estimate uses pi/1024 rad/count; exact angular scale, intermediate-angle accuracy and sentinel semantics remain unverified. Require state 2, valid range, freshness and temporal consistency. FCM sensor-fusion provenance unresolved.";

CM_ SG_ 235 Object0StateCandidateRaw "Empirical FCM object-record state: 0 accompanies cleared identity and companion states even when old coordinates remain; 2 accompanies populated records. 1 and 3 unobserved in validation. State 2 alone does not establish object existence: range/sentinel and freshness checks remain necessary. Not an OEM validity enumeration.";

CM_ SG_ 236 Object0OrientationCandidateRaw "FCM object orientation candidate: near zero correlates with forward-facing traffic; near +/-1024 with opposing-facing traffic. Display estimate uses pi/1024 rad/count; exact angular scale, intermediate-angle accuracy and sentinel semantics remain unverified. Require state 2, valid range, freshness and temporal consistency. FCM sensor-fusion provenance unresolved.";

CM_ SG_ 236 Object0StateCandidateRaw "Empirical FCM object-record state: 0 accompanies cleared identity and companion states even when old coordinates remain; 2 accompanies populated records. 1 and 3 unobserved in validation. State 2 alone does not establish object existence: range/sentinel and freshness checks remain necessary. Not an OEM validity enumeration.";

CM_ SG_ 212 Object0TrackId "Empirically identified sensor-local track label; follows targets across summary-slot changes. IDs may be recycled after loss and are not shared across sensors. Require fresh coordinate-matched details and spatial continuity. Not object class or width.";
CM_ SG_ 209 Object0TrackId "Empirically identified sensor-local track label; follows targets across summary-slot changes. IDs may be recycled after loss and are not shared across sensors. Require fresh coordinate-matched details and spatial continuity. Not object class or width.";
CM_ SG_ 198 Object0TrackId "Empirically identified sensor-local track label; follows targets across summary-slot changes. IDs may be recycled after loss and are not shared across sensors. Require fresh coordinate-matched details and spatial continuity. Not object class or width.";
CM_ SG_ 193 Object0TrackId "Empirically identified sensor-local track label; follows targets across summary-slot changes. IDs may be recycled after loss and are not shared across sensors. Require fresh coordinate-matched details and spatial continuity. Not object class or width.";
CM_ SG_ 254 Object0TrackId "Empirically identified sensor-local track label; follows targets across summary-slot changes. IDs may be recycled after loss and are not shared across sensors. Require fresh coordinate-matched details and spatial continuity. Not object class or width.";
CM_ SG_ 244 Object1TrackId "Empirically identified sensor-local track label; follows targets across summary-slot changes. IDs may be recycled after loss and are not shared across sensors. Require fresh coordinate-matched details and spatial continuity. Not object class or width.";
CM_ SG_ 244 Object2TrackId "Empirically identified sensor-local track label; follows targets across summary-slot changes. IDs may be recycled after loss and are not shared across sensors. Require fresh coordinate-matched details and spatial continuity. Not object class or width.";
CM_ SG_ 244 Object3TrackId "Empirically identified sensor-local track label; follows targets across summary-slot changes. IDs may be recycled after loss and are not shared across sensors. Require fresh coordinate-matched details and spatial continuity. Not object class or width.";
CM_ SG_ 247 Object1TrackId "Empirically identified sensor-local track label; follows targets across summary-slot changes. IDs may be recycled after loss and are not shared across sensors. Require fresh coordinate-matched details and spatial continuity. Not object class or width.";
CM_ SG_ 247 Object2TrackId "Empirically identified sensor-local track label; follows targets across summary-slot changes. IDs may be recycled after loss and are not shared across sensors. Require fresh coordinate-matched details and spatial continuity. Not object class or width.";
CM_ SG_ 247 Object3TrackId "Empirically identified sensor-local track label; follows targets across summary-slot changes. IDs may be recycled after loss and are not shared across sensors. Require fresh coordinate-matched details and spatial continuity. Not object class or width.";
CM_ SG_ 197 Object1TrackId "Empirically identified sensor-local track label; follows targets across summary-slot changes. IDs may be recycled after loss and are not shared across sensors. Require fresh coordinate-matched details and spatial continuity. Not object class or width.";
CM_ SG_ 197 Object2TrackId "Empirically identified sensor-local track label; follows targets across summary-slot changes. IDs may be recycled after loss and are not shared across sensors. Require fresh coordinate-matched details and spatial continuity. Not object class or width.";
CM_ SG_ 197 Object3TrackId "Empirically identified sensor-local track label; follows targets across summary-slot changes. IDs may be recycled after loss and are not shared across sensors. Require fresh coordinate-matched details and spatial continuity. Not object class or width.";
CM_ SG_ 519 Object1TrackId "Empirically identified sensor-local track label; follows targets across summary-slot changes. IDs may be recycled after loss and are not shared across sensors. Require fresh coordinate-matched details and spatial continuity. Not object class or width.";
CM_ SG_ 519 Object2TrackId "Empirically identified sensor-local track label; follows targets across summary-slot changes. IDs may be recycled after loss and are not shared across sensors. Require fresh coordinate-matched details and spatial continuity. Not object class or width.";
CM_ SG_ 519 Object3TrackId "Empirically identified sensor-local track label; follows targets across summary-slot changes. IDs may be recycled after loss and are not shared across sensors. Require fresh coordinate-matched details and spatial continuity. Not object class or width.";
CM_ SG_ 201 Object1TrackId "Empirically identified sensor-local track label; follows targets across summary-slot changes. IDs may be recycled after loss and are not shared across sensors. Require fresh coordinate-matched details and spatial continuity. Not object class or width.";
CM_ SG_ 201 Object2TrackId "Empirically identified sensor-local track label; follows targets across summary-slot changes. IDs may be recycled after loss and are not shared across sensors. Require fresh coordinate-matched details and spatial continuity. Not object class or width.";
CM_ SG_ 201 Object3TrackId "Empirically identified sensor-local track label; follows targets across summary-slot changes. IDs may be recycled after loss and are not shared across sensors. Require fresh coordinate-matched details and spatial continuity. Not object class or width.";

CM_ SG_ 212 Object0RelativeLongitudinalVelocityRaw "Empirical relative velocity in position-counts per second. Estimated physical conversion 0.125 m/s per count; not an OEM calibrated scale. Positive longitudinal is forward relative to ego, positive lateral is left. Lateral interpretation remains provisional. Require fresh identity-matched detail and reject extrema.";
CM_ SG_ 212 Object0RelativeLateralVelocityCandidateRaw "Empirical relative velocity in position-counts per second. Estimated physical conversion 0.125 m/s per count; not an OEM calibrated scale. Positive longitudinal is forward relative to ego, positive lateral is left. Lateral interpretation remains provisional. Require fresh identity-matched detail and reject extrema.";
CM_ SG_ 209 Object0RelativeLongitudinalVelocityRaw "Empirical relative velocity in position-counts per second. Estimated physical conversion 0.125 m/s per count; not an OEM calibrated scale. Positive longitudinal is forward relative to ego, positive lateral is left. Lateral interpretation remains provisional. Require fresh identity-matched detail and reject extrema.";
CM_ SG_ 209 Object0RelativeLateralVelocityCandidateRaw "Empirical relative velocity in position-counts per second. Estimated physical conversion 0.125 m/s per count; not an OEM calibrated scale. Positive longitudinal is forward relative to ego, positive lateral is left. Lateral interpretation remains provisional. Require fresh identity-matched detail and reject extrema.";
CM_ SG_ 198 Object0RelativeLongitudinalVelocityRaw "Empirical relative velocity in position-counts per second. Estimated physical conversion 0.125 m/s per count; not an OEM calibrated scale. Positive longitudinal is forward relative to ego, positive lateral is left. Lateral interpretation remains provisional. Require fresh identity-matched detail and reject extrema.";
CM_ SG_ 198 Object0RelativeLateralVelocityCandidateRaw "Empirical relative velocity in position-counts per second. Estimated physical conversion 0.125 m/s per count; not an OEM calibrated scale. Positive longitudinal is forward relative to ego, positive lateral is left. Lateral interpretation remains provisional. Require fresh identity-matched detail and reject extrema.";
CM_ SG_ 193 Object0RelativeLongitudinalVelocityRaw "Empirical relative velocity in position-counts per second. Estimated physical conversion 0.125 m/s per count; not an OEM calibrated scale. Positive longitudinal is forward relative to ego, positive lateral is left. Lateral interpretation remains provisional. Require fresh identity-matched detail and reject extrema.";
CM_ SG_ 193 Object0RelativeLateralVelocityCandidateRaw "Empirical relative velocity in position-counts per second. Estimated physical conversion 0.125 m/s per count; not an OEM calibrated scale. Positive longitudinal is forward relative to ego, positive lateral is left. Lateral interpretation remains provisional. Require fresh identity-matched detail and reject extrema.";
CM_ SG_ 254 Object0RelativeLongitudinalVelocityRaw "Empirical relative velocity in position-counts per second. Estimated physical conversion 0.125 m/s per count; not an OEM calibrated scale. Positive longitudinal is forward relative to ego, positive lateral is left. Lateral interpretation remains provisional. Require fresh identity-matched detail and reject extrema.";
CM_ SG_ 254 Object0RelativeLateralVelocityCandidateRaw "Empirical relative velocity in position-counts per second. Estimated physical conversion 0.125 m/s per count; not an OEM calibrated scale. Positive longitudinal is forward relative to ego, positive lateral is left. Lateral interpretation remains provisional. Require fresh identity-matched detail and reject extrema.";
CM_ SG_ 244 Object1RelativeLongitudinalVelocityRaw "Empirical relative velocity in position-counts per second. Estimated physical conversion 0.125 m/s per count; not an OEM calibrated scale. Positive longitudinal is forward relative to ego, positive lateral is left. Lateral interpretation remains provisional. Require fresh identity-matched detail and reject extrema.";
CM_ SG_ 244 Object1RelativeLateralVelocityCandidateRaw "Empirical relative velocity in position-counts per second. Estimated physical conversion 0.125 m/s per count; not an OEM calibrated scale. Positive longitudinal is forward relative to ego, positive lateral is left. Lateral interpretation remains provisional. Require fresh identity-matched detail and reject extrema.";
CM_ SG_ 244 Object2RelativeLongitudinalVelocityRaw "Empirical relative velocity in position-counts per second. Estimated physical conversion 0.125 m/s per count; not an OEM calibrated scale. Positive longitudinal is forward relative to ego, positive lateral is left. Lateral interpretation remains provisional. Require fresh identity-matched detail and reject extrema.";
CM_ SG_ 244 Object2RelativeLateralVelocityCandidateRaw "Empirical relative velocity in position-counts per second. Estimated physical conversion 0.125 m/s per count; not an OEM calibrated scale. Positive longitudinal is forward relative to ego, positive lateral is left. Lateral interpretation remains provisional. Require fresh identity-matched detail and reject extrema.";
CM_ SG_ 244 Object3RelativeLongitudinalVelocityRaw "Empirical relative velocity in position-counts per second. Estimated physical conversion 0.125 m/s per count; not an OEM calibrated scale. Positive longitudinal is forward relative to ego, positive lateral is left. Lateral interpretation remains provisional. Require fresh identity-matched detail and reject extrema.";
CM_ SG_ 244 Object3RelativeLateralVelocityCandidateRaw "Empirical relative velocity in position-counts per second. Estimated physical conversion 0.125 m/s per count; not an OEM calibrated scale. Positive longitudinal is forward relative to ego, positive lateral is left. Lateral interpretation remains provisional. Require fresh identity-matched detail and reject extrema.";
CM_ SG_ 247 Object1RelativeLongitudinalVelocityRaw "Empirical relative velocity in position-counts per second. Estimated physical conversion 0.125 m/s per count; not an OEM calibrated scale. Positive longitudinal is forward relative to ego, positive lateral is left. Lateral interpretation remains provisional. Require fresh identity-matched detail and reject extrema.";
CM_ SG_ 247 Object1RelativeLateralVelocityCandidateRaw "Empirical relative velocity in position-counts per second. Estimated physical conversion 0.125 m/s per count; not an OEM calibrated scale. Positive longitudinal is forward relative to ego, positive lateral is left. Lateral interpretation remains provisional. Require fresh identity-matched detail and reject extrema.";
CM_ SG_ 247 Object2RelativeLongitudinalVelocityRaw "Empirical relative velocity in position-counts per second. Estimated physical conversion 0.125 m/s per count; not an OEM calibrated scale. Positive longitudinal is forward relative to ego, positive lateral is left. Lateral interpretation remains provisional. Require fresh identity-matched detail and reject extrema.";
CM_ SG_ 247 Object2RelativeLateralVelocityCandidateRaw "Empirical relative velocity in position-counts per second. Estimated physical conversion 0.125 m/s per count; not an OEM calibrated scale. Positive longitudinal is forward relative to ego, positive lateral is left. Lateral interpretation remains provisional. Require fresh identity-matched detail and reject extrema.";
CM_ SG_ 247 Object3RelativeLongitudinalVelocityRaw "Empirical relative velocity in position-counts per second. Estimated physical conversion 0.125 m/s per count; not an OEM calibrated scale. Positive longitudinal is forward relative to ego, positive lateral is left. Lateral interpretation remains provisional. Require fresh identity-matched detail and reject extrema.";
CM_ SG_ 247 Object3RelativeLateralVelocityCandidateRaw "Empirical relative velocity in position-counts per second. Estimated physical conversion 0.125 m/s per count; not an OEM calibrated scale. Positive longitudinal is forward relative to ego, positive lateral is left. Lateral interpretation remains provisional. Require fresh identity-matched detail and reject extrema.";
CM_ SG_ 197 Object1RelativeLongitudinalVelocityRaw "Empirical relative velocity in position-counts per second. Estimated physical conversion 0.125 m/s per count; not an OEM calibrated scale. Positive longitudinal is forward relative to ego, positive lateral is left. Lateral interpretation remains provisional. Require fresh identity-matched detail and reject extrema.";
CM_ SG_ 197 Object1RelativeLateralVelocityCandidateRaw "Empirical relative velocity in position-counts per second. Estimated physical conversion 0.125 m/s per count; not an OEM calibrated scale. Positive longitudinal is forward relative to ego, positive lateral is left. Lateral interpretation remains provisional. Require fresh identity-matched detail and reject extrema.";
CM_ SG_ 197 Object2RelativeLongitudinalVelocityRaw "Empirical relative velocity in position-counts per second. Estimated physical conversion 0.125 m/s per count; not an OEM calibrated scale. Positive longitudinal is forward relative to ego, positive lateral is left. Lateral interpretation remains provisional. Require fresh identity-matched detail and reject extrema.";
CM_ SG_ 197 Object2RelativeLateralVelocityCandidateRaw "Empirical relative velocity in position-counts per second. Estimated physical conversion 0.125 m/s per count; not an OEM calibrated scale. Positive longitudinal is forward relative to ego, positive lateral is left. Lateral interpretation remains provisional. Require fresh identity-matched detail and reject extrema.";
CM_ SG_ 197 Object3RelativeLongitudinalVelocityRaw "Empirical relative velocity in position-counts per second. Estimated physical conversion 0.125 m/s per count; not an OEM calibrated scale. Positive longitudinal is forward relative to ego, positive lateral is left. Lateral interpretation remains provisional. Require fresh identity-matched detail and reject extrema.";
CM_ SG_ 197 Object3RelativeLateralVelocityCandidateRaw "Empirical relative velocity in position-counts per second. Estimated physical conversion 0.125 m/s per count; not an OEM calibrated scale. Positive longitudinal is forward relative to ego, positive lateral is left. Lateral interpretation remains provisional. Require fresh identity-matched detail and reject extrema.";
CM_ SG_ 519 Object1RelativeLongitudinalVelocityRaw "Empirical relative velocity in position-counts per second. Estimated physical conversion 0.125 m/s per count; not an OEM calibrated scale. Positive longitudinal is forward relative to ego, positive lateral is left. Lateral interpretation remains provisional. Require fresh identity-matched detail and reject extrema.";
CM_ SG_ 519 Object1RelativeLateralVelocityCandidateRaw "Empirical relative velocity in position-counts per second. Estimated physical conversion 0.125 m/s per count; not an OEM calibrated scale. Positive longitudinal is forward relative to ego, positive lateral is left. Lateral interpretation remains provisional. Require fresh identity-matched detail and reject extrema.";
CM_ SG_ 519 Object2RelativeLongitudinalVelocityRaw "Empirical relative velocity in position-counts per second. Estimated physical conversion 0.125 m/s per count; not an OEM calibrated scale. Positive longitudinal is forward relative to ego, positive lateral is left. Lateral interpretation remains provisional. Require fresh identity-matched detail and reject extrema.";
CM_ SG_ 519 Object2RelativeLateralVelocityCandidateRaw "Empirical relative velocity in position-counts per second. Estimated physical conversion 0.125 m/s per count; not an OEM calibrated scale. Positive longitudinal is forward relative to ego, positive lateral is left. Lateral interpretation remains provisional. Require fresh identity-matched detail and reject extrema.";
CM_ SG_ 519 Object3RelativeLongitudinalVelocityRaw "Empirical relative velocity in position-counts per second. Estimated physical conversion 0.125 m/s per count; not an OEM calibrated scale. Positive longitudinal is forward relative to ego, positive lateral is left. Lateral interpretation remains provisional. Require fresh identity-matched detail and reject extrema.";
CM_ SG_ 519 Object3RelativeLateralVelocityCandidateRaw "Empirical relative velocity in position-counts per second. Estimated physical conversion 0.125 m/s per count; not an OEM calibrated scale. Positive longitudinal is forward relative to ego, positive lateral is left. Lateral interpretation remains provisional. Require fresh identity-matched detail and reject extrema.";
CM_ SG_ 201 Object1RelativeLongitudinalVelocityRaw "Empirical relative velocity in position-counts per second. Estimated physical conversion 0.125 m/s per count; not an OEM calibrated scale. Positive longitudinal is forward relative to ego, positive lateral is left. Lateral interpretation remains provisional. Require fresh identity-matched detail and reject extrema.";
CM_ SG_ 201 Object1RelativeLateralVelocityCandidateRaw "Empirical relative velocity in position-counts per second. Estimated physical conversion 0.125 m/s per count; not an OEM calibrated scale. Positive longitudinal is forward relative to ego, positive lateral is left. Lateral interpretation remains provisional. Require fresh identity-matched detail and reject extrema.";
CM_ SG_ 201 Object2RelativeLongitudinalVelocityRaw "Empirical relative velocity in position-counts per second. Estimated physical conversion 0.125 m/s per count; not an OEM calibrated scale. Positive longitudinal is forward relative to ego, positive lateral is left. Lateral interpretation remains provisional. Require fresh identity-matched detail and reject extrema.";
CM_ SG_ 201 Object2RelativeLateralVelocityCandidateRaw "Empirical relative velocity in position-counts per second. Estimated physical conversion 0.125 m/s per count; not an OEM calibrated scale. Positive longitudinal is forward relative to ego, positive lateral is left. Lateral interpretation remains provisional. Require fresh identity-matched detail and reject extrema.";
CM_ SG_ 201 Object3RelativeLongitudinalVelocityRaw "Empirical relative velocity in position-counts per second. Estimated physical conversion 0.125 m/s per count; not an OEM calibrated scale. Positive longitudinal is forward relative to ego, positive lateral is left. Lateral interpretation remains provisional. Require fresh identity-matched detail and reject extrema.";
CM_ SG_ 201 Object3RelativeLateralVelocityCandidateRaw "Empirical relative velocity in position-counts per second. Estimated physical conversion 0.125 m/s per count; not an OEM calibrated scale. Positive longitudinal is forward relative to ego, positive lateral is left. Lateral interpretation remains provisional. Require fresh identity-matched detail and reject extrema.";
